VERSION "canboat-NMEA2000-curated"

NS_ :

BS_:

BU_: Vector__XXX
BO_ 2382300672 PGN_130822_navicoConfigurationSet: 17 Vector__XXX
 SG_ Manufacturer_Code : 0|11@1+ (1.0,0) [0|2047] "" Vector__XXX
 SG_ Industry_Code : 13|3@1+ (1.0,0) [0|7] "" Vector__XXX
 SG_ Marker : 16|8@1+ (1.0,0) [0|255] "" Vector__XXX
 SG_ Command : 24|6@1+ (1.0,0) [0|63] "" Vector__XXX
 SG_ Spare : 30|2@1+ (1.0,0) [0|3] "" Vector__XXX
 SG_ Address : 32|8@1+ (1.0,0) [0|255] "" Vector__XXX
 SG_ Section : 40|8@1+ (1.0,0) [0|255] "" Vector__XXX
 SG_ Item : 48|8@1+ (1.0,0) [0|255] "" Vector__XXX
 SG_ Spare_1 : 56|8@1+ (1.0,0) [0|255] "" Vector__XXX
 SG_ Source_Setting_Id : 64|8@1+ (1.0,0) [0|255] "" Vector__XXX
 SG_ Spare_2 : 72|24@1+ (1.0,0) [0|16777215] "" Vector__XXX
 SG_ Token : 96|16@1+ (1.0,0) [0|65535] "" Vector__XXX
 SG_ Length : 112|16@1+ (1.0,0) [0|65535] "" Vector__XXX
 SG_ Value : 128|8@1+ (1.0,0) [0|255] "" Vector__XXX

BO_ 2382300672 PGN_130822_navicoUdbDatabaseBulkReport2: 223 Vector__XXX
 SG_ Manufacturer_Code : 0|11@1+ (1.0,0) [0|2047] "" Vector__XXX
 SG_ Industry_Code : 13|3@1+ (1.0,0) [0|7] "" Vector__XXX
 SG_ Marker : 16|8@1+ (1.0,0) [0|255] "" Vector__XXX
 SG_ Command : 24|6@1+ (1.0,0) [0|63] "" Vector__XXX
 SG_ Spare : 30|2@1+ (1.0,0) [0|3] "" Vector__XXX
 SG_ Address : 32|8@1+ (1.0,0) [0|255] "" Vector__XXX
 SG_ Section : 40|8@1+ (1.0,0) [0|255] "" Vector__XXX
 SG_ Item : 48|8@1+ (1.0,0) [0|255] "" Vector__XXX
 SG_ Data : 56|1728@1+ (1.0,0) [0|15129776317850095820092511389349266990292718729815631986418537353879463563521162185150219603700165130994236082131324756445942491538167955612355559370819630786874949073054392871127532858565042604704229027792897149278536911570984376289178239414281093587086254280625511423417734560103547720775941236898584297864754056409689723511538383397266829071642966529789271374337767970717302376007449935423628987375161285038699647338790955261847896303406764539379637294632424461577413789356619528237622525126579905139518845267220627455] "" Vector__XXX

BO_ 2382300672 PGN_130822_navicoUdbDatabaseBulkReport4: 223 Vector__XXX
 SG_ Manufacturer_Code : 0|11@1+ (1.0,0) [0|2047] "" Vector__XXX
 SG_ Industry_Code : 13|3@1+ (1.0,0) [0|7] "" Vector__XXX
 SG_ Marker : 16|8@1+ (1.0,0) [0|255] "" Vector__XXX
 SG_ Command : 24|6@1+ (1.0,0) [0|63] "" Vector__XXX
 SG_ Address : 32|8@1+ (1.0,0) [0|255] "" Vector__XXX
 SG_ Section : 40|8@1+ (1.0,0) [0|255] "" Vector__XXX
 SG_ Item : 48|8@1+ (1.0,0) [0|255] "" Vector__XXX
 SG_ Data : 56|1728@1+ (1.0,0) [0|15129776317850095820092511389349266990292718729815631986418537353879463563521162185150219603700165130994236082131324756445942491538167955612355559370819630786874949073054392871127532858565042604704229027792897149278536911570984376289178239414281093587086254280625511423417734560103547720775941236898584297864754056409689723511538383397266829071642966529789271374337767970717302376007449935423628987375161285038699647338790955261847896303406764539379637294632424461577413789356619528237622525126579905139518845267220627455] "" Vector__XXX

BO_ 2382300672 PGN_130822_navicoUdbDatabaseObjectDump: 15 Vector__XXX
 SG_ Manufacturer_Code : 0|11@1+ (1.0,0) [0|2047] "" Vector__XXX
 SG_ Industry_Code : 13|3@1+ (1.0,0) [0|7] "" Vector__XXX
 SG_ Marker : 16|8@1+ (1.0,0) [0|255] "" Vector__XXX
 SG_ Command : 24|6@1+ (1.0,0) [0|63] "" Vector__XXX
 SG_ Address : 32|8@1+ (1.0,0) [0|255] "" Vector__XXX
 SG_ Section : 40|8@1+ (1.0,0) [0|255] "" Vector__XXX
 SG_ Item : 48|8@1+ (1.0,0) [0|255] "" Vector__XXX
 SG_ Object_Value : 56|16@1+ (1.0,0) [0|65535] "" Vector__XXX
 SG_ Sub : 72|24@1+ (1.0,0) [0|16777215] "" Vector__XXX
 SG_ Token : 96|16@1+ (1.0,0) [0|65535] "" Vector__XXX
 SG_ field112 : 112|8@1+ (1.0,0) [0|255] "" Vector__XXX

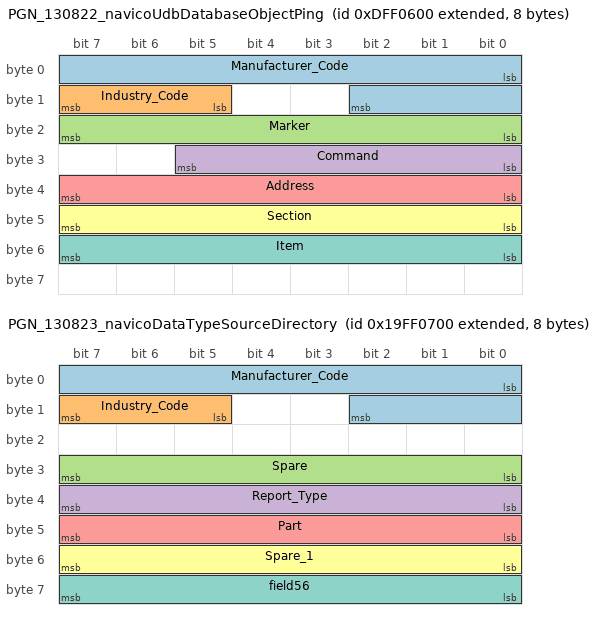
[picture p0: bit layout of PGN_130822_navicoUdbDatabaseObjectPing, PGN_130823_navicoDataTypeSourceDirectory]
BO_ 2382300672 PGN_130822_navicoUdbDatabaseObjectPing: 8 Vector__XXX
 SG_ Manufacturer_Code : 0|11@1+ (1.0,0) [0|2047] "" Vector__XXX
 SG_ Industry_Code : 13|3@1+ (1.0,0) [0|7] "" Vector__XXX
 SG_ Marker : 16|8@1+ (1.0,0) [0|255] "" Vector__XXX
 SG_ Command : 24|6@1+ (1.0,0) [0|63] "" Vector__XXX
 SG_ Address : 32|8@1+ (1.0,0) [0|255] "" Vector__XXX
 SG_ Section : 40|8@1+ (1.0,0) [0|255] "" Vector__XXX
 SG_ Item : 48|8@1+ (1.0,0) [0|255] "" Vector__XXX

BO_ 2382300672 PGN_130822_navicoUdbDatabaseShortReport5: 11 Vector__XXX
 SG_ Manufacturer_Code : 0|11@1+ (1.0,0) [0|2047] "" Vector__XXX
 SG_ Industry_Code : 13|3@1+ (1.0,0) [0|7] "" Vector__XXX
 SG_ Marker : 16|8@1+ (1.0,0) [0|255] "" Vector__XXX
 SG_ Command : 24|6@1+ (1.0,0) [0|63] "" Vector__XXX
 SG_ Address : 32|8@1+ (1.0,0) [0|255] "" Vector__XXX
 SG_ Section : 40|8@1+ (1.0,0) [0|255] "" Vector__XXX
 SG_ Item : 48|8@1+ (1.0,0) [0|255] "" Vector__XXX
 SG_ Data : 56|32@1+ (1.0,0) [0|4294967295] "" Vector__XXX

BO_ 2382300672 PGN_130822_navicoUdbDatabaseShortReport7: 11 Vector__XXX
 SG_ Manufacturer_Code : 0|11@1+ (1.0,0) [0|2047] "" Vector__XXX
 SG_ Industry_Code : 13|3@1+ (1.0,0) [0|7] "" Vector__XXX
 SG_ Marker : 16|8@1+ (1.0,0) [0|255] "" Vector__XXX
 SG_ Command : 24|6@1+ (1.0,0) [0|63] "" Vector__XXX
 SG_ Address : 32|8@1+ (1.0,0) [0|255] "" Vector__XXX
 SG_ Section : 40|8@1+ (1.0,0) [0|255] "" Vector__XXX
 SG_ Item : 48|8@1+ (1.0,0) [0|255] "" Vector__XXX
 SG_ Data : 56|32@1+ (1.0,0) [0|4294967295] "" Vector__XXX

BO_ 2382300672 PGN_130822_navicoUdbDatabaseSourceReport: 15 Vector__XXX
 SG_ Manufacturer_Code : 0|11@1+ (1.0,0) [0|2047] "" Vector__XXX
 SG_ Industry_Code : 13|3@1+ (1.0,0) [0|7] "" Vector__XXX
 SG_ Marker : 16|8@1+ (1.0,0) [0|255] "" Vector__XXX
 SG_ Command : 24|6@1+ (1.0,0) [0|63] "" Vector__XXX
 SG_ Spare : 30|2@1+ (1.0,0) [0|3] "" Vector__XXX
 SG_ Address : 32|8@1+ (1.0,0) [0|255] "" Vector__XXX
 SG_ Source_Setting_Id : 40|8@1+ (1.0,0) [0|255] "" Vector__XXX
 SG_ Item : 48|8@1+ (1.0,0) [0|255] "" Vector__XXX
 SG_ Object_Value : 56|16@1+ (1.0,0) [0|65535] "" Vector__XXX
 SG_ Instance : 72|4@1+ (1.0,0) [0|15] "" Vector__XXX
 SG_ Source_Selection_Master : 76|1@1+ (1.0,0) [0|1] "" Vector__XXX
 SG_ Spare_1 : 77|3@1+ (1.0,0) [0|7] "" Vector__XXX
 SG_ Sub : 80|24@1+ (1.0,0) [0|16777215] "" Vector__XXX
 SG_ Token : 104|16@1+ (1.0,0) [0|65535] "" Vector__XXX

BO_ 2382300928 PGN_130823_maretronProprietaryTemperatureHighRange: 9 Vector__XXX
 SG_ Manufacturer_Code : 0|11@1+ (1.0,0) [0|2047] "" Vector__XXX
 SG_ Industry_Code : 13|3@1+ (1.0,0) [0|7] "" Vector__XXX
 SG_ SID : 16|8@1+ (1.0,0) [0|255] "" Vector__XXX
 SG_ Instance : 24|8@1+ (1.0,0) [0|255] "" Vector__XXX
 SG_ Source : 32|8@1+ (1.0,0) [0|255] "" Vector__XXX
 SG_ Actual_Temperature : 40|16@1+ (0.1,0) [0.0|6553.5] "" Vector__XXX
 SG_ Set_Temperature : 56|16@1+ (0.1,0) [0.0|6553.5] "" Vector__XXX

BO_ 2583627520 PGN_130823_navicoBoatSpeedPolarTable: 230 Vector__XXX
 SG_ Manufacturer_Code : 0|11@1+ (1.0,0) [0|2047] "" Vector__XXX
 SG_ Industry_Code : 13|3@1+ (1.0,0) [0|7] "" Vector__XXX
 SG_ Spare : 24|8@1+ (1.0,0) [0|255] "" Vector__XXX
 SG_ Report_Type : 32|8@1+ (1.0,0) [0|255] "" Vector__XXX
 SG_ Part : 40|8@1+ (1.0,0) [0|255] "" Vector__XXX
 SG_ Spare_1 : 48|8@1+ (1.0,0) [0|255] "" Vector__XXX
 SG_ Data : 56|1784@1+ (1.0,0) [0|1090215279796298345343057319992441691038624747443985361781209060500115864369550760897269927218265076257224706224150656474098235960303036328065314058501678867531182833105052489870268422279120576700031813116210596361941430020414688522690787050244934600671795757515093047026287646566366777283893649942831776083163858446641848270013788759459916945946844663111358071639842481472666169361795887031940572252862030682746818684507336852618633070135215708762463263460541984102045620907003420426453486084172633338261276848631947315738747720031010815] "" Vector__XXX

BO_ 2583627520 PGN_130823_navicoDataTypeSourceDirectory: 8 Vector__XXX
 SG_ Manufacturer_Code : 0|11@1+ (1.0,0) [0|2047] "" Vector__XXX
 SG_ Industry_Code : 13|3@1+ (1.0,0) [0|7] "" Vector__XXX
 SG_ Spare : 24|8@1+ (1.0,0) [0|255] "" Vector__XXX
 SG_ Report_Type : 32|8@1+ (1.0,0) [0|255] "" Vector__XXX
 SG_ Part : 40|8@1+ (1.0,0) [0|255] "" Vector__XXX
 SG_ Spare_1 : 48|8@1+ (1.0,0) [0|255] "" Vector__XXX
 SG_ field56 : 56|8@1+ (1.0,0) [0|255] "" Vector__XXX

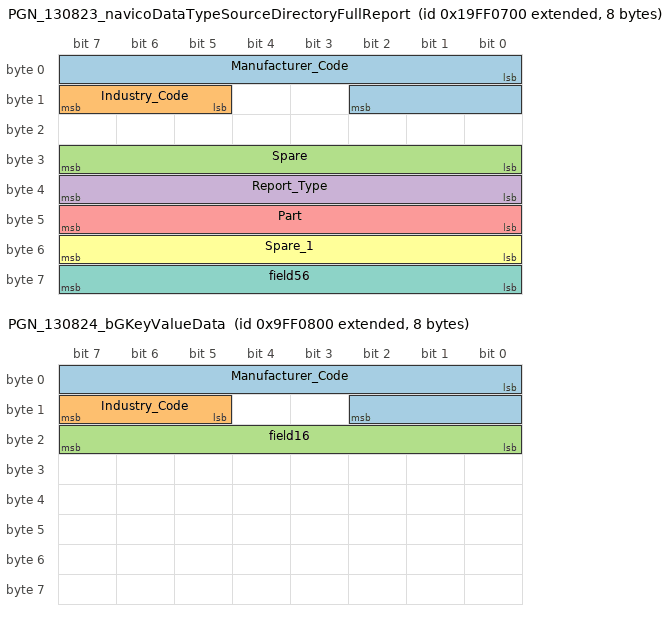
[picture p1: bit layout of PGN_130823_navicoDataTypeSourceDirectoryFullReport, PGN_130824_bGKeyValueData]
BO_ 2583627520 PGN_130823_navicoDataTypeSourceDirectoryFullReport: 8 Vector__XXX
 SG_ Manufacturer_Code : 0|11@1+ (1.0,0) [0|2047] "" Vector__XXX
 SG_ Industry_Code : 13|3@1+ (1.0,0) [0|7] "" Vector__XXX
 SG_ Spare : 24|8@1+ (1.0,0) [0|255] "" Vector__XXX
 SG_ Report_Type : 32|8@1+ (1.0,0) [0|255] "" Vector__XXX
 SG_ Part : 40|8@1+ (1.0,0) [0|255] "" Vector__XXX
 SG_ Spare_1 : 48|8@1+ (1.0,0) [0|255] "" Vector__XXX
 SG_ field56 : 56|8@1+ (1.0,0) [0|255] "" Vector__XXX

BO_ 2315192320 PGN_130824_bGKeyValueData: 8 Vector__XXX
 SG_ Manufacturer_Code : 0|11@1+ (1.0,0) [0|2047] "" Vector__XXX
 SG_ Industry_Code : 13|3@1+ (1.0,0) [0|7] "" Vector__XXX
 SG_ field16 : 16|8@1+ (1.0,0) [0|255] "" Vector__XXX

BO_ 2650736640 PGN_130824_maretronAnnunciator: 9 Vector__XXX
 SG_ Manufacturer_Code : 0|11@1+ (1.0,0) [0|2047] "" Vector__XXX
 SG_ Industry_Code : 13|3@1+ (1.0,0) [0|7] "" Vector__XXX
 SG_ Annunciator_Instance : 16|8@1+ (1.0,0) [0|255] "" Vector__XXX
 SG_ Annunciator_State : 24|8@1+ (1.0,0) [0|255] "" Vector__XXX
 SG_ Pattern : 32|16@1+ (1.0,0) [0|65535] "" Vector__XXX
 SG_ Field_7 : 48|8@1+ (1.0,0) [0|255] "" Vector__XXX
 SG_ Alert_ID : 56|16@1+ (1.0,0) [0|65535] "" Vector__XXX

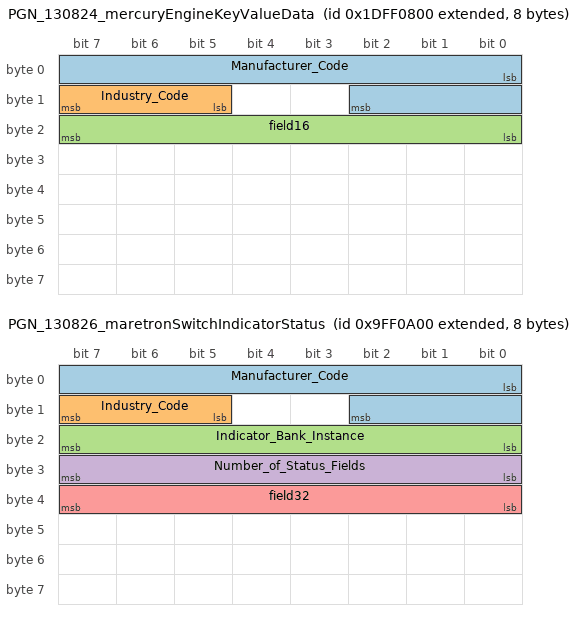
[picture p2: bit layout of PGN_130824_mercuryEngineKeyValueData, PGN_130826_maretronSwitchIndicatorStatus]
BO_ 2650736640 PGN_130824_mercuryEngineKeyValueData: 8 Vector__XXX
 SG_ Manufacturer_Code : 0|11@1+ (1.0,0) [0|2047] "" Vector__XXX
 SG_ Industry_Code : 13|3@1+ (1.0,0) [0|7] "" Vector__XXX
 SG_ field16 : 16|8@1+ (1.0,0) [0|255] "" Vector__XXX

BO_ 2583628032 PGN_130825_bepMarineProprietaryPgn130825: 223 Vector__XXX
 SG_ Manufacturer_Code : 0|11@1+ (1.0,0) [0|2047] "" Vector__XXX
 SG_ Industry_Code : 13|3@1+ (1.0,0) [0|7] "" Vector__XXX
 SG_ Data : 16|1768@1+ (1.0,0) [0|16635364987126134419907490844611231857889171561340108669757218330385068731224834608417815051548234195819468783937845710359164977421616154908223175941492902641772198991471137845920843845811776377869137773379678289214194183661112800944378464511794046030758602257005203964634516091405743061582849883160885255175229773660916874237270946647032424101972117051870087763059119895517977437771543686400460392041962138103436564399831189767740372774280024852942859855049773927338342604171805121253257539126169331943684033945189625789470637817855] "" Vector__XXX

BO_ 2583628032 PGN_130825_maretronDataInstanceChannelCorrelation: 9 Vector__XXX
 SG_ Manufacturer_Code : 0|11@1+ (1.0,0) [0|2047] "" Vector__XXX
 SG_ Industry_Code : 13|3@1+ (1.0,0) [0|7] "" Vector__XXX
 SG_ PGN : 16|24@1+ (1.0,0) [0.0|262143.0] "" Vector__XXX
 SG_ Hardware_Channel : 40|8@1+ (1.0,0) [0|255] "" Vector__XXX
 SG_ Instance : 48|8@1+ (1.0,0) [0|255] "" Vector__XXX
 SG_ Data_Source : 56|8@1+ (1.0,0) [0|255] "" Vector__XXX
 SG_ Data_Indicator : 64|8@1+ (1.0,0) [0|255] "" Vector__XXX

BO_ 2650736896 PGN_130825_mercuryCommandResponse: 33 Vector__XXX
 SG_ Manufacturer_Code : 0|11@1+ (1.0,0) [0|2047] "" Vector__XXX
 SG_ Industry_Code : 13|3@1+ (1.0,0) [0|7] "" Vector__XXX
 SG_ Opcode : 16|8@1+ (1.0,0) [0|255] "" Vector__XXX
 SG_ Data : 24|240@1+ (1.0,0) [0|1766847064778384329583297500742918515827483896875618958121606201292619775] "" Vector__XXX

BO_ 2650736896 PGN_130825_mercuryCruiseControlData: 13 Vector__XXX
 SG_ Manufacturer_Code : 0|11@1+ (1.0,0) [0|2047] "" Vector__XXX
 SG_ Industry_Code : 13|3@1+ (1.0,0) [0|7] "" Vector__XXX
 SG_ Opcode : 16|8@1+ (1.0,0) [0|255] "" Vector__XXX
 SG_ Engine_Instance : 24|8@1+ (1.0,0) [0|255] "" Vector__XXX
 SG_ Cruise_State : 40|8@1+ (1.0,0) [0|255] "" Vector__XXX
 SG_ Cruise_RPM_Setpoint : 48|16@1+ (1.0,0) [0|65535] "rpm" Vector__XXX
 SG_ Cruise_Speed_Setpoint : 64|16@1+ (0.01,0) [0.0|655.35] "km/h" Vector__XXX

BO_ 2650736896 PGN_130825_navicoAlarm: 11 Vector__XXX
 SG_ Manufacturer_Code : 0|11@1+ (1.0,0) [0|2047] "" Vector__XXX
 SG_ Industry_Code : 13|3@1+ (1.0,0) [0|7] "" Vector__XXX
 SG_ Instance : 16|8@1+ (1.0,0) [0|255] "" Vector__XXX
 SG_ Record_ID : 24|8@1+ (1.0,0) [0|255] "" Vector__XXX
 SG_ Alarm_Type : 32|16@1+ (1.0,0) [0|65535] "" Vector__XXX
 SG_ Alarm_ID : 48|16@1+ (1.0,0) [0|65535] "" Vector__XXX
 SG_ Alarm_State : 64|3@1+ (1.0,0) [0|7] "" Vector__XXX
 SG_ Action_Flag : 67|1@1+ (1.0,0) [0|1] "" Vector__XXX
 SG_ Alarm_Severity : 68|4@1+ (1.0,0) [0|15] "" Vector__XXX
 SG_ Value : 72|16@1+ (1.0,0) [0|65535] "" Vector__XXX

BO_ 2583628288 PGN_130826_bepMarineProprietaryPgn130826: 223 Vector__XXX
 SG_ Manufacturer_Code : 0|11@1+ (1.0,0) [0|2047] "" Vector__XXX
 SG_ Industry_Code : 13|3@1+ (1.0,0) [0|7] "" Vector__XXX
 SG_ Data : 16|1768@1+ (1.0,0) [0|16635364987126134419907490844611231857889171561340108669757218330385068731224834608417815051548234195819468783937845710359164977421616154908223175941492902641772198991471137845920843845811776377869137773379678289214194183661112800944378464511794046030758602257005203964634516091405743061582849883160885255175229773660916874237270946647032424101972117051870087763059119895517977437771543686400460392041962138103436564399831189767740372774280024852942859855049773927338342604171805121253257539126169331943684033945189625789470637817855] "" Vector__XXX

BO_ 2315192832 PGN_130826_maretronSwitchIndicatorStatus: 8 Vector__XXX
 SG_ Manufacturer_Code : 0|11@1+ (1.0,0) [0|2047] "" Vector__XXX
 SG_ Industry_Code : 13|3@1+ (1.0,0) [0|7] "" Vector__XXX
 SG_ Indicator_Bank_Instance : 16|8@1+ (1.0,0) [0|255] "" Vector__XXX
 SG_ Number_of_Status_Fields : 24|8@1+ (1.0,0) [0|255] "" Vector__XXX
 SG_ field32 : 32|8@1+ (1.0,0) [0|255] "" Vector__XXX

BO_ 2650737152 PGN_130826_mercuryBamDigitalDataProxy: 38 Vector__XXX
 SG_ Manufacturer_Code : 0|11@1+ (1.0,0) [0|2047] "" Vector__XXX
 SG_ Industry_Code : 13|3@1+ (1.0,0) [0|7] "" Vector__XXX
 SG_ Type : 16|8@1+ (1.0,0) [0|255] "" Vector__XXX
 SG_ Instance : 24|8@1+ (1.0,0) [0|255] "" Vector__XXX
 SG_ Field_4 : 32|2@1+ (1.0,0) [0|3] "" Vector__XXX
 SG_ Flag : 40|8@1+ (1.0,0) [0|255] "" Vector__XXX
 SG_ Data : 48|256@1+ (1.0,0) [0|115792089237316195423570985008687907853269984665640564039457584007913129639935] "" Vector__XXX

CM_ BO_ 2382300672 "NMEA2000: PGN 130822 - Navico: Configuration Set (type: Fast)";
CM_ BO_ 2382300672 "NMEA2000: PGN 130822 - Navico: UDB Database, Bulk Report 2 (type: Fast)";
CM_ BO_ 2382300672 "NMEA2000: PGN 130822 - Navico: UDB Database, Bulk Report 4 (type: Fast)";
CM_ BO_ 2382300672 "NMEA2000: PGN 130822 - Navico: UDB Database, Object Dump (type: Fast)";
CM_ BO_ 2382300672 "NMEA2000: PGN 130822 - Navico: UDB Database, Object Ping (type: Fast)";
CM_ BO_ 2382300672 "NMEA2000: PGN 130822 - Navico: UDB Database, Short Report 5 (type: Fast)";
CM_ BO_ 2382300672 "NMEA2000: PGN 130822 - Navico: UDB Database, Short Report 7 (type: Fast)";
CM_ BO_ 2382300672 "NMEA2000: PGN 130822 - Navico: UDB Database, Source Report (type: Fast)";
CM_ BO_ 2382300928 "NMEA2000: PGN 130823 - Maretron: Proprietary Temperature High Range (type: Fast)";
CM_ BO_ 2583627520 "NMEA2000: PGN 130823 - Navico: Boat Speed Polar Table (type: Fast)";
CM_ BO_ 2583627520 "NMEA2000: PGN 130823 - Navico: Data Type Source Directory (type: Fast)";
CM_ BO_ 2583627520 "NMEA2000: PGN 130823 - Navico: Data Type Source Directory, Full Report (type: Fast)";
CM_ BO_ 2315192320 "NMEA2000: PGN 130824 - B&G: key-value data (type: Fast)";
CM_ BO_ 2650736640 "NMEA2000: PGN 130824 - Maretron: Annunciator (type: Fast)";
CM_ BO_ 2650736640 "NMEA2000: PGN 130824 - Mercury: Engine Key-Value Data (type: Fast)";
CM_ BO_ 2583628032 "NMEA2000: PGN 130825 - BEP Marine: Proprietary PGN 130825 (type: Fast)";
CM_ BO_ 2583628032 "NMEA2000: PGN 130825 - Maretron: Data Instance Channel Correlation (type: Fast)";
CM_ BO_ 2650736896 "NMEA2000: PGN 130825 - Mercury: Command/Response (type: Fast)";
CM_ BO_ 2650736896 "NMEA2000: PGN 130825 - Mercury: Cruise Control Data (type: Fast)";
CM_ BO_ 2650736896 "NMEA2000: PGN 130825 - Navico: Alarm (type: Fast)";
CM_ BO_ 2583628288 "NMEA2000: PGN 130826 - BEP Marine: Proprietary PGN 130826 (type: Fast)";
CM_ BO_ 2315192832 "NMEA2000: PGN 130826 - Maretron: Switch Indicator Status (type: Fast)";
CM_ BO_ 2650737152 "NMEA2000: PGN 130826 - Mercury: BAM Digital-Data Proxy (type: Fast)";
CM_ SG_ 2382300672 Manufacturer_Code "Navico; canboat type: LOOKUP";
CM_ SG_ 2382300672 Industry_Code "Marine Industry; canboat type: LOOKUP";
CM_ SG_ 2382300672 Marker "Always 0xFF; canboat type: UINT8";
CM_ SG_ 2382300672 Command "Configuration Set; canboat type: UNSIGNED_INTEGER";
CM_ SG_ 2382300672 Spare "canboat type: SPARE";
CM_ SG_ 2382300672 Address "Part of the object address; canboat type: UINT8";
CM_ SG_ 2382300672 Section "canboat type: UINT8";
CM_ SG_ 2382300672 Item "canboat type: UINT8";
CM_ SG_ 2382300672 Spare_1 "canboat type: SPARE";
CM_ SG_ 2382300672 Source_Setting_Id "Compacted id selecting which setting this object reports; also resolves the wire type of the Value field that follows. Different id space from the Command 1 'Source Setting Id', the Command 6 dump / PGN 130845 NAVICO_DATA_TYPE ids, and PGN 130840.; canboat type: DYNAMIC_FIELD_KEY";
CM_ SG_ 2382300672 Spare_2 "canboat type: SPARE";
CM_ SG_ 2382300672 Token "Per-object identity token, constant per object; canboat type: UINT16";
CM_ SG_ 2382300672 Length "Byte length of the Value field that follows; canboat type: DYNAMIC_FIELD_LENGTH";
CM_ SG_ 2382300672 Value "Value for this setting; its type is resolved from Source Setting Id.; canboat type: DYNAMIC_FIELD_VALUE";
CM_ SG_ 2382300672 Manufacturer_Code "Navico; canboat type: LOOKUP";
CM_ SG_ 2382300672 Industry_Code "Marine Industry; canboat type: LOOKUP";
CM_ SG_ 2382300672 Marker "Always 0xFF; canboat type: UINT8";
CM_ SG_ 2382300672 Command "Bulk Report 2; canboat type: UNSIGNED_INTEGER";
CM_ SG_ 2382300672 Spare "canboat type: SPARE";
CM_ SG_ 2382300672 Address "Part of the object address; canboat type: UINT8";
CM_ SG_ 2382300672 Section "canboat type: UINT8";
CM_ SG_ 2382300672 Item "canboat type: UINT8";
CM_ SG_ 2382300672 Data "Bulk variant payload (length-prefixed); layout not yet observed on the wire; canboat type: BINARY";
CM_ SG_ 2382300672 Manufacturer_Code "Navico; canboat type: LOOKUP";
CM_ SG_ 2382300672 Industry_Code "Marine Industry; canboat type: LOOKUP";
CM_ SG_ 2382300672 Marker "Always 0xFF; canboat type: UINT8";
CM_ SG_ 2382300672 Command "Bulk Report 4; canboat type: UNSIGNED_INTEGER";
CM_ SG_ 2382300672 Address "Part of the object address; canboat type: UINT8";
CM_ SG_ 2382300672 Section "canboat type: UINT8";
CM_ SG_ 2382300672 Item "canboat type: UINT8";
CM_ SG_ 2382300672 Data "Bulk variant payload (length-prefixed); layout not yet observed on the wire; canboat type: BINARY";
CM_ SG_ 2382300672 Manufacturer_Code "Navico; canboat type: LOOKUP";
CM_ SG_ 2382300672 Industry_Code "Marine Industry; canboat type: LOOKUP";
CM_ SG_ 2382300672 Marker "Always 0xFF; canboat type: UINT8";
CM_ SG_ 2382300672 Command "Object Dump; canboat type: UNSIGNED_INTEGER";
CM_ SG_ 2382300672 Address "Part of the object address; canboat type: UINT8";
CM_ SG_ 2382300672 Section "canboat type: UINT8";
CM_ SG_ 2382300672 Item "canboat type: UINT8";
CM_ SG_ 2382300672 Object_Value "Current value (A); 0xFC00 means no value; canboat type: UINT16";
CM_ SG_ 2382300672 Sub "Sub-index and auxiliary bytes; canboat type: BINARY";
CM_ SG_ 2382300672 Token "Per-object identity/CRC-like token (B), constant per object; canboat type: UINT16";
CM_ SG_ 2382300672 field112 "canboat type: NUMBER";
CM_ SG_ 2382300672 Manufacturer_Code "Navico; canboat type: LOOKUP";
CM_ SG_ 2382300672 Industry_Code "Marine Industry; canboat type: LOOKUP";
CM_ SG_ 2382300672 Marker "Always 0xFF; canboat type: UINT8";
CM_ SG_ 2382300672 Command "Object Ping; canboat type: UNSIGNED_INTEGER";
CM_ SG_ 2382300672 Address "Part of the object address; canboat type: UINT8";
CM_ SG_ 2382300672 Section "canboat type: UINT8";
CM_ SG_ 2382300672 Item "canboat type: UINT8";
CM_ SG_ 2382300672 Manufacturer_Code "Navico; canboat type: LOOKUP";
CM_ SG_ 2382300672 Industry_Code "Marine Industry; canboat type: LOOKUP";
CM_ SG_ 2382300672 Marker "Always 0xFF; canboat type: UINT8";
CM_ SG_ 2382300672 Command "Short Report 5; canboat type: UNSIGNED_INTEGER";
CM_ SG_ 2382300672 Address "Part of the object address; canboat type: UINT8";
CM_ SG_ 2382300672 Section "canboat type: UINT8";
CM_ SG_ 2382300672 Item "canboat type: UINT8";
CM_ SG_ 2382300672 Data "canboat type: BINARY";
CM_ SG_ 2382300672 Manufacturer_Code "Navico; canboat type: LOOKUP";
CM_ SG_ 2382300672 Industry_Code "Marine Industry; canboat type: LOOKUP";
CM_ SG_ 2382300672 Marker "Always 0xFF; canboat type: UINT8";
CM_ SG_ 2382300672 Command "Short Report 7; canboat type: UNSIGNED_INTEGER";
CM_ SG_ 2382300672 Address "Part of the object address; canboat type: UINT8";
CM_ SG_ 2382300672 Section "canboat type: UINT8";
CM_ SG_ 2382300672 Item "canboat type: UINT8";
CM_ SG_ 2382300672 Data "canboat type: BINARY";
CM_ SG_ 2382300672 Manufacturer_Code "Navico; canboat type: LOOKUP";
CM_ SG_ 2382300672 Industry_Code "Marine Industry; canboat type: LOOKUP";
CM_ SG_ 2382300672 Marker "Always 0xFF; canboat type: UINT8";
CM_ SG_ 2382300672 Command "Source Report; canboat type: UNSIGNED_INTEGER";
CM_ SG_ 2382300672 Spare "canboat type: SPARE";
CM_ SG_ 2382300672 Address "Part of the object address; canboat type: UINT8";
CM_ SG_ 2382300672 Source_Setting_Id "Compacted id selecting which data type this object is for. This is a different id space from the Command 6 dump / PGN 130845 data-type ids (NAVICO_DATA_TYPE) - the two use different numbers for the same quantity. Only 0x0F = Heading is mapped so far; see PGN 130840.; canboat type: UINT8";
CM_ SG_ 2382300672 Item "canboat type: UINT8";
CM_ SG_ 2382300672 Object_Value "Current value (A); 0xFC00 means no value. This is the field that varies over time.; canboat type: UINT16";
CM_ SG_ 2382300672 Instance "canboat type: UNSIGNED_INTEGER";
CM_ SG_ 2382300672 Source_Selection_Master "Auto-select / source-selection-master flag; canboat type: UNSIGNED_INTEGER";
CM_ SG_ 2382300672 Spare_1 "canboat type: SPARE";
CM_ SG_ 2382300672 Sub "Sub-index and auxiliary bytes; constant per object (same Sub as the Command 6 dump); canboat type: BINARY";
CM_ SG_ 2382300672 Token "Per-object identity/CRC-like token (B), constant per object (same Token as the Command 6 dump); canboat type: UINT16";
CM_ SG_ 2382300928 Manufacturer_Code "Maretron; canboat type: LOOKUP";
CM_ SG_ 2382300928 Industry_Code "Marine Industry; canboat type: LOOKUP";
CM_ SG_ 2382300928 SID "canboat type: UINT8";
CM_ SG_ 2382300928 Instance "canboat type: UINT8";
CM_ SG_ 2382300928 Source "canboat type: LOOKUP";
CM_ SG_ 2382300928 Actual_Temperature "canboat type: TEMPERATURE_HIGH";
CM_ SG_ 2382300928 Set_Temperature "canboat type: TEMPERATURE_HIGH";
CM_ SG_ 2583627520 Manufacturer_Code "Navico; canboat type: LOOKUP";
CM_ SG_ 2583627520 Industry_Code "Marine Industry; canboat type: LOOKUP";
CM_ SG_ 2583627520 Spare "canboat type: SPARE";
CM_ SG_ 2583627520 Report_Type "Boat-speed polar / performance table; canboat type: UINT8";
CM_ SG_ 2583627520 Part "Part number; the table is split across several parts that must be concatenated in order; canboat type: UINT8";
CM_ SG_ 2583627520 Spare_1 "canboat type: SPARE";
CM_ SG_ 2583627520 Data "Raw table fragment carried by this part; canboat type: BINARY";
CM_ SG_ 2583627520 Manufacturer_Code "Navico; canboat type: LOOKUP";
CM_ SG_ 2583627520 Industry_Code "Marine Industry; canboat type: LOOKUP";
CM_ SG_ 2583627520 Spare "canboat type: SPARE";
CM_ SG_ 2583627520 Report_Type "Data-type source directory; canboat type: UINT8";
CM_ SG_ 2583627520 Part "Sequence/part number of the directory report; canboat type: UINT8";
CM_ SG_ 2583627520 Spare_1 "canboat type: SPARE";
CM_ SG_ 2583627520 field56 "canboat type: NUMBER";
CM_ SG_ 2583627520 Manufacturer_Code "Navico; canboat type: LOOKUP";
CM_ SG_ 2583627520 Industry_Code "Marine Industry; canboat type: LOOKUP";
CM_ SG_ 2583627520 Spare "canboat type: SPARE";
CM_ SG_ 2583627520 Report_Type "Data-type source directory (full report); canboat type: UINT8";
CM_ SG_ 2583627520 Part "Sequence/part number of the directory report; canboat type: UINT8";
CM_ SG_ 2583627520 Spare_1 "canboat type: SPARE";
CM_ SG_ 2583627520 field56 "canboat type: NUMBER";
CM_ SG_ 2315192320 Manufacturer_Code "B & G; canboat type: LOOKUP";
CM_ SG_ 2315192320 Industry_Code "Marine Industry; canboat type: LOOKUP";
CM_ SG_ 2315192320 field16 "canboat type: NUMBER";
CM_ SG_ 2650736640 Manufacturer_Code "Maretron; canboat type: LOOKUP";
CM_ SG_ 2650736640 Industry_Code "Marine Industry; canboat type: LOOKUP";
CM_ SG_ 2650736640 Annunciator_Instance "canboat type: UINT8";
CM_ SG_ 2650736640 Annunciator_State "100 while the annunciator is sounding, 0 while it is idle.; canboat type: UINT8";
CM_ SG_ 2650736640 Pattern "Selects the pulse pattern; observed values 0 to 4 give audibly different beep cadences, not different pitches. Unavailable while idle.; canboat type: UINT16";
CM_ SG_ 2650736640 Field_7 "canboat type: UINT8";
CM_ SG_ 2650736640 Alert_ID "Identifies the alert the annunciator is currently sounding for.; canboat type: UINT16";
CM_ SG_ 2650736640 Manufacturer_Code "Mercury Marine; canboat type: LOOKUP";
CM_ SG_ 2650736640 Industry_Code "Marine Industry; canboat type: LOOKUP";
CM_ SG_ 2650736640 field16 "canboat type: NUMBER";
CM_ SG_ 2583628032 Manufacturer_Code "BEP Marine; canboat type: LOOKUP";
CM_ SG_ 2583628032 Industry_Code "Marine Industry; canboat type: LOOKUP";
CM_ SG_ 2583628032 Data "canboat type: BINARY";
CM_ SG_ 2583628032 Manufacturer_Code "Maretron; canboat type: LOOKUP";
CM_ SG_ 2583628032 Industry_Code "Marine Industry; canboat type: LOOKUP";
CM_ SG_ 2583628032 PGN "PGN for which the correlation is reported; canboat type: PGN";
CM_ SG_ 2583628032 Hardware_Channel "canboat type: UINT8";
CM_ SG_ 2583628032 Instance "canboat type: UINT8";
CM_ SG_ 2583628032 Data_Source "canboat type: UINT8";
CM_ SG_ 2583628032 Data_Indicator "canboat type: UINT8";
CM_ SG_ 2650736896 Manufacturer_Code "Mercury Marine; canboat type: LOOKUP";
CM_ SG_ 2650736896 Industry_Code "Marine Industry; canboat type: LOOKUP";
CM_ SG_ 2650736896 Opcode "canboat type: LOOKUP";
CM_ SG_ 2650736896 Data "canboat type: BINARY";
CM_ SG_ 2650736896 Manufacturer_Code "Mercury Marine; canboat type: LOOKUP";
CM_ SG_ 2650736896 Industry_Code "Marine Industry; canboat type: LOOKUP";
CM_ SG_ 2650736896 Opcode "Cruise Control; canboat type: LOOKUP";
CM_ SG_ 2650736896 Engine_Instance "canboat type: UINT8";
CM_ SG_ 2650736896 Cruise_State "Cruise engagement/mode byte; 0 = disengaged, 5 = engaged; canboat type: UINT8";
CM_ SG_ 2650736896 Cruise_RPM_Setpoint "canboat type: UINT16";
CM_ SG_ 2650736896 Cruise_Speed_Setpoint "canboat type: DILUTION_OF_PRECISION_UFIX16";
CM_ SG_ 2650736896 Manufacturer_Code "Navico; canboat type: LOOKUP";
CM_ SG_ 2650736896 Industry_Code "Marine Industry; canboat type: LOOKUP";
CM_ SG_ 2650736896 Instance "canboat type: UINT8";
CM_ SG_ 2650736896 Record_ID "canboat type: UINT8";
CM_ SG_ 2650736896 Alarm_Type "canboat type: UINT16";
CM_ SG_ 2650736896 Alarm_ID "canboat type: LOOKUP";
CM_ SG_ 2650736896 Alarm_State "canboat type: LOOKUP";
CM_ SG_ 2650736896 Action_Flag "canboat type: UNSIGNED_INTEGER";
CM_ SG_ 2650736896 Alarm_Severity "canboat type: LOOKUP";
CM_ SG_ 2650736896 Value "canboat type: UINT16";
CM_ SG_ 2583628288 Manufacturer_Code "BEP Marine; canboat type: LOOKUP";
CM_ SG_ 2583628288 Industry_Code "Marine Industry; canboat type: LOOKUP";
CM_ SG_ 2583628288 Data "canboat type: BINARY";
CM_ SG_ 2315192832 Manufacturer_Code "Maretron; canboat type: LOOKUP";
CM_ SG_ 2315192832 Industry_Code "Marine Industry; canboat type: LOOKUP";
CM_ SG_ 2315192832 Indicator_Bank_Instance "canboat type: UINT8";
CM_ SG_ 2315192832 Number_of_Status_Fields "canboat type: UINT8";
CM_ SG_ 2315192832 field32 "canboat type: NUMBER";
CM_ SG_ 2650737152 Manufacturer_Code "Mercury Marine; canboat type: LOOKUP";
CM_ SG_ 2650737152 Industry_Code "Marine Industry; canboat type: LOOKUP";
CM_ SG_ 2650737152 Type "canboat type: UINT8";
CM_ SG_ 2650737152 Instance "canboat type: UINT8";
CM_ SG_ 2650737152 Field_4 "canboat type: UNSIGNED_INTEGER";
CM_ SG_ 2650737152 Flag "canboat type: UINT8";
CM_ SG_ 2650737152 Data "canboat type: BINARY";
VAL_ 2382300672 Manufacturer_Code 69 "ARKS Enterprises" 78 "FW Murphy/Enovation Controls" 80 "Twin Disc" 85 "Kohler Power Systems" 88 "Hemisphere GPS" 135 "Airmar" 137 "Maretron" 140 "Lowrance" 144 "Mercury Marine" 147 "Nautibus Electronic" 148 "Blue Water Data" 154 "Westerbeke" 157 "ISSPRO" 161 "Offshore Systems (UK)" 163 "Evinrude/BRP" 165 "CPAC Systems" 168 "Xantrex Technology" 169 "Marlin Technologies" 172 "Yanmar Marine" 174 "Volvo Penta" 176 "Carling Technologies Inc. (Moritz Aerospace)" 185 "Beede Instruments" 192 "Floscan Instrument" 193 "Nobeltec" 198 "Mystic Valley Communications" 199 "Actia" 201 "Disenos Y Technologia" 211 "Digital Switching Systems" 215 "Xintex/Atena" 224 "EMMI NETWORK" 228 "ZF" 229 "Garmin" 233 "Yacht Monitoring Solutions" 235 "Sailormade Marine Telemetry/Tetra Technology" 243 "Eride" 257 "Honda Motor" 272 "Groco" 273 "Actisense" 274 "Amphenol LTW Technology" 275 "Navico" 283 "Hamilton Jet" 285 "Sea Recovery" 286 "Coelmo SRL Italy" 295 "BEP Marine" 304 "Empir Bus" 305 "NovAtel" 306 "Sleipner Motor" 307 "MBW Technologies" 315 "ICOM" 328 "Qwerty" 329 "Dief" 341 "Boening Automationstechnologie" 345 "Korean Maritime University" 351 "Thrane and Thrane" 355 "Mastervolt" 356 "Fischer Panda Generators" 358 "Victron Energy" 370 "Rolls Royce Marine" 373 "Electronic Design" 374 "Northern Lights" 378 "Glendinning" 381 "B & G" 384 "Rose Point Navigation Systems" 385 "Johnson Outdoors Marine Electronics Inc Geonav" 394 "Capi 2" 396 "Beyond Measure" 400 "Livorsi Marine" 404 "ComNav" 409 "Chetco" 419 "Fusion Electronics" 421 "Standard Horizon" 422 "True Heading" 426 "Egersund Marine Electronics" 427 "em-trak Marine Electronics" 431 "Tohatsu Co, JP" 437 "Digital Yacht" 438 "Comar Systems Limited" 440 "Cummins" 443 "VDO (aka Continental-Corporation)" 451 "Parker Hannifin aka Village Marine Tech" 459 "Alltek Marine Electronics" 460 "SAN GIORGIO S.E.I.N" 466 "Veethree Electronics & Marine" 470 "SI-TEX Marine Electronics" 471 "Sea Cross Marine" 475 "GME aka Standard Communications" 476 "Humminbird Marine Electronics" 478 "Ocean Sat" 481 "Chetco Digital Instruments" 493 "Watcheye" 499 "Lcj Capteurs" 502 "Attwood Marine" 503 "Naviop S.R.L." 504 "Vesper Marine" 510 "Marinesoft" 513 "Simarine" 517 "NoLand Engineering" 518 "Transas USA" 529 "National Instruments Korea" 530 "National Marine Electronics Association" 532 "Onwa Marine" 540 "Webasto" 571 "Marinecraft (South Korea)" 573 "McMurdo Group aka Orolia" 578 "Advansea" 579 "KVH" 580 "San Jose Technology" 583 "Yacht Control" 586 "Suzuki Motor" 591 "US Coast Guard" 595 "Ship Module aka Customware" 600 "Aquatic AV" 605 "Aventics" 606 "Intellian" 612 "SamwonIT" 614 "Arlt Tecnologies" 637 "Bavaria Yachts" 641 "Diverse Yacht Services" 644 "Wema U.S.A dba KUS" 658 "Shenzhen Jiuzhou Himunication" 688 "Rockford" 699 "Harman International" 704 "JL Audio" 708 "Lars Thrane" 715 "Autonnic" 717 "Yacht Devices" 734 "REAP Systems" 735 "AEM Performance Electronics" 739 "LxNav" 741 "Littelfuse, Inc (formerly Carling Technologies)" 743 "DaeMyung" 744 "Woosung" 748 "ISOTTA IFRA srl" 773 "Clarion US" 776 "HMI Systems" 777 "Ocean Signal" 778 "Seakeeper" 781 "Poly Planar" 785 "Fischer Panda DE" 795 "Broyda Industries" 796 "Canadian Automotive" 797 "Tides Marine" 798 "Lumishore" 799 "Still Water Designs and Audio" 802 "BJ Technologies (Beneteau)" 803 "Gill Sensors" 811 "Blue Water Desalination" 815 "FLIR" 824 "Undheim Systems" 826 "Lewmar" 838 "TeamSurv" 844 "Fell Marine" 847 "Oceanvolt" 862 "Prospec" 868 "Data Panel" 890 "L3 Technologies" 894 "Rhodan Marine Systems" 896 "Nexfour Solutions" 905 "ASA Electronics" 909 "Marines Co (South Korea)" 911 "Nautic-on" 917 "Sentinel" 929 "JL Marine Systems" 930 "Ecotronix" 944 "Zontisa Marine" 951 "EXOR International" 962 "Timbolier Industries" 963 "TJC Micro" 968 "Cox Powertrain" 969 "Blue Seas" 981 "Kobelt Manufacturing" 992 "Blue Ocean IOT" 997 "Xenta Systems" 999 "Signal K" 1004 "Ultraflex" 1008 "Lintest SmartBoat" 1011 "Soundmax" 1020 "Team Italia Marine (Onyx Marine Automation s.r.l)" 1021 "Entratech" 1022 "ITC" 1029 "The Marine Guardian" 1047 "Sonic" 1051 "ProNav" 1053 "Vetus Maxwell INC." 1056 "Lithium Pros" 1059 "Boatrax" 1062 "Marol Co ltd" 1065 "CALYPSO Instruments" 1066 "Spot Zero Water" 1069 "Lithionics Battery" 1070 "Quick-teck Electronics" 1075 "Uniden America" 1083 "Nauticoncept" 1084 "Shadow-Caster LED lighting" 1085 "Wet Sounds" 1088 "E-T-A Circuit Breakers" 1092 "Scheiber" 1100 "Smart Yachts International Limited" 1109 "Dockmate" 1114 "Bobs Machine" 1118 "L3Harris ASV" 1119 "Balmar" 1120 "Elettromedia" 1127 "Electromaax" 1140 "Across Oceans Systems" 1145 "Kiwi Yachting" 1150 "BSB Artificial Intelligence" 1151 "Orca Technologies" 1154 "TBS Electronics" 1158 "Technoton Electroics" 1160 "MG Energy Systems" 1169 "Sea Machine Robotics" 1171 "Vista Manufacturing" 1183 "Zipwake" 1186 "Sailmon" 1192 "Airmoniq Pro Kft" 1194 "Sierra Marine" 1200 "Xinuo Information Technology (Xiamen)" 1218 "Septentrio" 1233 "NKE Marine Electronics" 1238 "SuperTrack Aps" 1239 "Honda Electronics" 1245 "Raritan Engineering" 1249 "Integrated Power Solutions AG" 1260 "Interactive Technologies" 1283 "LTG-Tech" 1299 "Energy Solutions (UK)" 1300 "WATT Fuel Cell" 1302 "Pro Mainer" 1305 "Dragonfly Energy" 1306 "Koden Electronics" 1311 "Humphree" 1316 "Hinkley Yachts" 1317 "Global Marine Management GmbH (GMM)" 1320 "Triskel Marine" 1330 "Warwick Control Technologies" 1331 "Dolphin Charger" 1337 "Barnacle Systems" 1348 "Radian IoT" 1353 "Ocean LED Marine" 1359 "BluNav" 1361 "OVA (Nantong Saiyang Electronics Co., Ltd)" 1368 "RAD Propulsion" 1369 "Electric Yacht" 1372 "Elco Motor Yachts" 1384 "Tecnoseal Foundry S.r.l" 1385 "Pro Charging Systems" 1389 "EVEX" 1398 "Gobius Sensor Technology" 1403 "Arco Marine" 1408 "Lenco Marine" 1413 "Naocontrol" 1417 "Revatek" 1438 "Aeolionics" 1439 "PredictWind" 1440 "Egis Mobile Electric" 1445 "Starboard Yacht Group" 1446 "Roswell Marine" 1451 "ePropulsion (Guangdong ePropulsion Technology Ltd.)" 1452 "Micro-Air" 1453 "Vital Battery" 1458 "Ride Controller" 1460 "Tocaro Blue" 1461 "Vanquish Yachts" 1471 "FT Technologies" 1478 "Alps Alpine" 1481 "E-Force Marine" 1482 "CMC Marine" 1483 "Nanjing Sandemarine Information Technology" 1850 "Teleflex Marine (SeaStar Solutions)" 1851 "Raymarine" 1852 "Navionics" 1853 "Japan Radio" 1854 "Northstar Technologies" 1855 "Furuno" 1856 "Trimble" 1857 "Simrad" 1858 "Litton" 1859 "Kvasar" 1860 "MMP" 1861 "Vector Cantech" 1862 "Yamaha Marine" 1863 "Faria Instruments" ;
VAL_ 2382300672 Industry_Code 0 "Global" 1 "Highway" 2 "Agriculture" 3 "Construction" 4 "Marine Industry" 5 "Industrial" ;
VAL_ 2382300672 Manufacturer_Code 69 "ARKS Enterprises" 78 "FW Murphy/Enovation Controls" 80 "Twin Disc" 85 "Kohler Power Systems" 88 "Hemisphere GPS" 135 "Airmar" 137 "Maretron" 140 "Lowrance" 144 "Mercury Marine" 147 "Nautibus Electronic" 148 "Blue Water Data" 154 "Westerbeke" 157 "ISSPRO" 161 "Offshore Systems (UK)" 163 "Evinrude/BRP" 165 "CPAC Systems" 168 "Xantrex Technology" 169 "Marlin Technologies" 172 "Yanmar Marine" 174 "Volvo Penta" 176 "Carling Technologies Inc. (Moritz Aerospace)" 185 "Beede Instruments" 192 "Floscan Instrument" 193 "Nobeltec" 198 "Mystic Valley Communications" 199 "Actia" 201 "Disenos Y Technologia" 211 "Digital Switching Systems" 215 "Xintex/Atena" 224 "EMMI NETWORK" 228 "ZF" 229 "Garmin" 233 "Yacht Monitoring Solutions" 235 "Sailormade Marine Telemetry/Tetra Technology" 243 "Eride" 257 "Honda Motor" 272 "Groco" 273 "Actisense" 274 "Amphenol LTW Technology" 275 "Navico" 283 "Hamilton Jet" 285 "Sea Recovery" 286 "Coelmo SRL Italy" 295 "BEP Marine" 304 "Empir Bus" 305 "NovAtel" 306 "Sleipner Motor" 307 "MBW Technologies" 315 "ICOM" 328 "Qwerty" 329 "Dief" 341 "Boening Automationstechnologie" 345 "Korean Maritime University" 351 "Thrane and Thrane" 355 "Mastervolt" 356 "Fischer Panda Generators" 358 "Victron Energy" 370 "Rolls Royce Marine" 373 "Electronic Design" 374 "Northern Lights" 378 "Glendinning" 381 "B & G" 384 "Rose Point Navigation Systems" 385 "Johnson Outdoors Marine Electronics Inc Geonav" 394 "Capi 2" 396 "Beyond Measure" 400 "Livorsi Marine" 404 "ComNav" 409 "Chetco" 419 "Fusion Electronics" 421 "Standard Horizon" 422 "True Heading" 426 "Egersund Marine Electronics" 427 "em-trak Marine Electronics" 431 "Tohatsu Co, JP" 437 "Digital Yacht" 438 "Comar Systems Limited" 440 "Cummins" 443 "VDO (aka Continental-Corporation)" 451 "Parker Hannifin aka Village Marine Tech" 459 "Alltek Marine Electronics" 460 "SAN GIORGIO S.E.I.N" 466 "Veethree Electronics & Marine" 470 "SI-TEX Marine Electronics" 471 "Sea Cross Marine" 475 "GME aka Standard Communications" 476 "Humminbird Marine Electronics" 478 "Ocean Sat" 481 "Chetco Digital Instruments" 493 "Watcheye" 499 "Lcj Capteurs" 502 "Attwood Marine" 503 "Naviop S.R.L." 504 "Vesper Marine" 510 "Marinesoft" 513 "Simarine" 517 "NoLand Engineering" 518 "Transas USA" 529 "National Instruments Korea" 530 "National Marine Electronics Association" 532 "Onwa Marine" 540 "Webasto" 571 "Marinecraft (South Korea)" 573 "McMurdo Group aka Orolia" 578 "Advansea" 579 "KVH" 580 "San Jose Technology" 583 "Yacht Control" 586 "Suzuki Motor" 591 "US Coast Guard" 595 "Ship Module aka Customware" 600 "Aquatic AV" 605 "Aventics" 606 "Intellian" 612 "SamwonIT" 614 "Arlt Tecnologies" 637 "Bavaria Yachts" 641 "Diverse Yacht Services" 644 "Wema U.S.A dba KUS" 658 "Shenzhen Jiuzhou Himunication" 688 "Rockford" 699 "Harman International" 704 "JL Audio" 708 "Lars Thrane" 715 "Autonnic" 717 "Yacht Devices" 734 "REAP Systems" 735 "AEM Performance Electronics" 739 "LxNav" 741 "Littelfuse, Inc (formerly Carling Technologies)" 743 "DaeMyung" 744 "Woosung" 748 "ISOTTA IFRA srl" 773 "Clarion US" 776 "HMI Systems" 777 "Ocean Signal" 778 "Seakeeper" 781 "Poly Planar" 785 "Fischer Panda DE" 795 "Broyda Industries" 796 "Canadian Automotive" 797 "Tides Marine" 798 "Lumishore" 799 "Still Water Designs and Audio" 802 "BJ Technologies (Beneteau)" 803 "Gill Sensors" 811 "Blue Water Desalination" 815 "FLIR" 824 "Undheim Systems" 826 "Lewmar" 838 "TeamSurv" 844 "Fell Marine" 847 "Oceanvolt" 862 "Prospec" 868 "Data Panel" 890 "L3 Technologies" 894 "Rhodan Marine Systems" 896 "Nexfour Solutions" 905 "ASA Electronics" 909 "Marines Co (South Korea)" 911 "Nautic-on" 917 "Sentinel" 929 "JL Marine Systems" 930 "Ecotronix" 944 "Zontisa Marine" 951 "EXOR International" 962 "Timbolier Industries" 963 "TJC Micro" 968 "Cox Powertrain" 969 "Blue Seas" 981 "Kobelt Manufacturing" 992 "Blue Ocean IOT" 997 "Xenta Systems" 999 "Signal K" 1004 "Ultraflex" 1008 "Lintest SmartBoat" 1011 "Soundmax" 1020 "Team Italia Marine (Onyx Marine Automation s.r.l)" 1021 "Entratech" 1022 "ITC" 1029 "The Marine Guardian" 1047 "Sonic" 1051 "ProNav" 1053 "Vetus Maxwell INC." 1056 "Lithium Pros" 1059 "Boatrax" 1062 "Marol Co ltd" 1065 "CALYPSO Instruments" 1066 "Spot Zero Water" 1069 "Lithionics Battery" 1070 "Quick-teck Electronics" 1075 "Uniden America" 1083 "Nauticoncept" 1084 "Shadow-Caster LED lighting" 1085 "Wet Sounds" 1088 "E-T-A Circuit Breakers" 1092 "Scheiber" 1100 "Smart Yachts International Limited" 1109 "Dockmate" 1114 "Bobs Machine" 1118 "L3Harris ASV" 1119 "Balmar" 1120 "Elettromedia" 1127 "Electromaax" 1140 "Across Oceans Systems" 1145 "Kiwi Yachting" 1150 "BSB Artificial Intelligence" 1151 "Orca Technologies" 1154 "TBS Electronics" 1158 "Technoton Electroics" 1160 "MG Energy Systems" 1169 "Sea Machine Robotics" 1171 "Vista Manufacturing" 1183 "Zipwake" 1186 "Sailmon" 1192 "Airmoniq Pro Kft" 1194 "Sierra Marine" 1200 "Xinuo Information Technology (Xiamen)" 1218 "Septentrio" 1233 "NKE Marine Electronics" 1238 "SuperTrack Aps" 1239 "Honda Electronics" 1245 "Raritan Engineering" 1249 "Integrated Power Solutions AG" 1260 "Interactive Technologies" 1283 "LTG-Tech" 1299 "Energy Solutions (UK)" 1300 "WATT Fuel Cell" 1302 "Pro Mainer" 1305 "Dragonfly Energy" 1306 "Koden Electronics" 1311 "Humphree" 1316 "Hinkley Yachts" 1317 "Global Marine Management GmbH (GMM)" 1320 "Triskel Marine" 1330 "Warwick Control Technologies" 1331 "Dolphin Charger" 1337 "Barnacle Systems" 1348 "Radian IoT" 1353 "Ocean LED Marine" 1359 "BluNav" 1361 "OVA (Nantong Saiyang Electronics Co., Ltd)" 1368 "RAD Propulsion" 1369 "Electric Yacht" 1372 "Elco Motor Yachts" 1384 "Tecnoseal Foundry S.r.l" 1385 "Pro Charging Systems" 1389 "EVEX" 1398 "Gobius Sensor Technology" 1403 "Arco Marine" 1408 "Lenco Marine" 1413 "Naocontrol" 1417 "Revatek" 1438 "Aeolionics" 1439 "PredictWind" 1440 "Egis Mobile Electric" 1445 "Starboard Yacht Group" 1446 "Roswell Marine" 1451 "ePropulsion (Guangdong ePropulsion Technology Ltd.)" 1452 "Micro-Air" 1453 "Vital Battery" 1458 "Ride Controller" 1460 "Tocaro Blue" 1461 "Vanquish Yachts" 1471 "FT Technologies" 1478 "Alps Alpine" 1481 "E-Force Marine" 1482 "CMC Marine" 1483 "Nanjing Sandemarine Information Technology" 1850 "Teleflex Marine (SeaStar Solutions)" 1851 "Raymarine" 1852 "Navionics" 1853 "Japan Radio" 1854 "Northstar Technologies" 1855 "Furuno" 1856 "Trimble" 1857 "Simrad" 1858 "Litton" 1859 "Kvasar" 1860 "MMP" 1861 "Vector Cantech" 1862 "Yamaha Marine" 1863 "Faria Instruments" ;
VAL_ 2382300672 Industry_Code 0 "Global" 1 "Highway" 2 "Agriculture" 3 "Construction" 4 "Marine Industry" 5 "Industrial" ;
VAL_ 2382300672 Manufacturer_Code 69 "ARKS Enterprises" 78 "FW Murphy/Enovation Controls" 80 "Twin Disc" 85 "Kohler Power Systems" 88 "Hemisphere GPS" 135 "Airmar" 137 "Maretron" 140 "Lowrance" 144 "Mercury Marine" 147 "Nautibus Electronic" 148 "Blue Water Data" 154 "Westerbeke" 157 "ISSPRO" 161 "Offshore Systems (UK)" 163 "Evinrude/BRP" 165 "CPAC Systems" 168 "Xantrex Technology" 169 "Marlin Technologies" 172 "Yanmar Marine" 174 "Volvo Penta" 176 "Carling Technologies Inc. (Moritz Aerospace)" 185 "Beede Instruments" 192 "Floscan Instrument" 193 "Nobeltec" 198 "Mystic Valley Communications" 199 "Actia" 201 "Disenos Y Technologia" 211 "Digital Switching Systems" 215 "Xintex/Atena" 224 "EMMI NETWORK" 228 "ZF" 229 "Garmin" 233 "Yacht Monitoring Solutions" 235 "Sailormade Marine Telemetry/Tetra Technology" 243 "Eride" 257 "Honda Motor" 272 "Groco" 273 "Actisense" 274 "Amphenol LTW Technology" 275 "Navico" 283 "Hamilton Jet" 285 "Sea Recovery" 286 "Coelmo SRL Italy" 295 "BEP Marine" 304 "Empir Bus" 305 "NovAtel" 306 "Sleipner Motor" 307 "MBW Technologies" 315 "ICOM" 328 "Qwerty" 329 "Dief" 341 "Boening Automationstechnologie" 345 "Korean Maritime University" 351 "Thrane and Thrane" 355 "Mastervolt" 356 "Fischer Panda Generators" 358 "Victron Energy" 370 "Rolls Royce Marine" 373 "Electronic Design" 374 "Northern Lights" 378 "Glendinning" 381 "B & G" 384 "Rose Point Navigation Systems" 385 "Johnson Outdoors Marine Electronics Inc Geonav" 394 "Capi 2" 396 "Beyond Measure" 400 "Livorsi Marine" 404 "ComNav" 409 "Chetco" 419 "Fusion Electronics" 421 "Standard Horizon" 422 "True Heading" 426 "Egersund Marine Electronics" 427 "em-trak Marine Electronics" 431 "Tohatsu Co, JP" 437 "Digital Yacht" 438 "Comar Systems Limited" 440 "Cummins" 443 "VDO (aka Continental-Corporation)" 451 "Parker Hannifin aka Village Marine Tech" 459 "Alltek Marine Electronics" 460 "SAN GIORGIO S.E.I.N" 466 "Veethree Electronics & Marine" 470 "SI-TEX Marine Electronics" 471 "Sea Cross Marine" 475 "GME aka Standard Communications" 476 "Humminbird Marine Electronics" 478 "Ocean Sat" 481 "Chetco Digital Instruments" 493 "Watcheye" 499 "Lcj Capteurs" 502 "Attwood Marine" 503 "Naviop S.R.L." 504 "Vesper Marine" 510 "Marinesoft" 513 "Simarine" 517 "NoLand Engineering" 518 "Transas USA" 529 "National Instruments Korea" 530 "National Marine Electronics Association" 532 "Onwa Marine" 540 "Webasto" 571 "Marinecraft (South Korea)" 573 "McMurdo Group aka Orolia" 578 "Advansea" 579 "KVH" 580 "San Jose Technology" 583 "Yacht Control" 586 "Suzuki Motor" 591 "US Coast Guard" 595 "Ship Module aka Customware" 600 "Aquatic AV" 605 "Aventics" 606 "Intellian" 612 "SamwonIT" 614 "Arlt Tecnologies" 637 "Bavaria Yachts" 641 "Diverse Yacht Services" 644 "Wema U.S.A dba KUS" 658 "Shenzhen Jiuzhou Himunication" 688 "Rockford" 699 "Harman International" 704 "JL Audio" 708 "Lars Thrane" 715 "Autonnic" 717 "Yacht Devices" 734 "REAP Systems" 735 "AEM Performance Electronics" 739 "LxNav" 741 "Littelfuse, Inc (formerly Carling Technologies)" 743 "DaeMyung" 744 "Woosung" 748 "ISOTTA IFRA srl" 773 "Clarion US" 776 "HMI Systems" 777 "Ocean Signal" 778 "Seakeeper" 781 "Poly Planar" 785 "Fischer Panda DE" 795 "Broyda Industries" 796 "Canadian Automotive" 797 "Tides Marine" 798 "Lumishore" 799 "Still Water Designs and Audio" 802 "BJ Technologies (Beneteau)" 803 "Gill Sensors" 811 "Blue Water Desalination" 815 "FLIR" 824 "Undheim Systems" 826 "Lewmar" 838 "TeamSurv" 844 "Fell Marine" 847 "Oceanvolt" 862 "Prospec" 868 "Data Panel" 890 "L3 Technologies" 894 "Rhodan Marine Systems" 896 "Nexfour Solutions" 905 "ASA Electronics" 909 "Marines Co (South Korea)" 911 "Nautic-on" 917 "Sentinel" 929 "JL Marine Systems" 930 "Ecotronix" 944 "Zontisa Marine" 951 "EXOR International" 962 "Timbolier Industries" 963 "TJC Micro" 968 "Cox Powertrain" 969 "Blue Seas" 981 "Kobelt Manufacturing" 992 "Blue Ocean IOT" 997 "Xenta Systems" 999 "Signal K" 1004 "Ultraflex" 1008 "Lintest SmartBoat" 1011 "Soundmax" 1020 "Team Italia Marine (Onyx Marine Automation s.r.l)" 1021 "Entratech" 1022 "ITC" 1029 "The Marine Guardian" 1047 "Sonic" 1051 "ProNav" 1053 "Vetus Maxwell INC." 1056 "Lithium Pros" 1059 "Boatrax" 1062 "Marol Co ltd" 1065 "CALYPSO Instruments" 1066 "Spot Zero Water" 1069 "Lithionics Battery" 1070 "Quick-teck Electronics" 1075 "Uniden America" 1083 "Nauticoncept" 1084 "Shadow-Caster LED lighting" 1085 "Wet Sounds" 1088 "E-T-A Circuit Breakers" 1092 "Scheiber" 1100 "Smart Yachts International Limited" 1109 "Dockmate" 1114 "Bobs Machine" 1118 "L3Harris ASV" 1119 "Balmar" 1120 "Elettromedia" 1127 "Electromaax" 1140 "Across Oceans Systems" 1145 "Kiwi Yachting" 1150 "BSB Artificial Intelligence" 1151 "Orca Technologies" 1154 "TBS Electronics" 1158 "Technoton Electroics" 1160 "MG Energy Systems" 1169 "Sea Machine Robotics" 1171 "Vista Manufacturing" 1183 "Zipwake" 1186 "Sailmon" 1192 "Airmoniq Pro Kft" 1194 "Sierra Marine" 1200 "Xinuo Information Technology (Xiamen)" 1218 "Septentrio" 1233 "NKE Marine Electronics" 1238 "SuperTrack Aps" 1239 "Honda Electronics" 1245 "Raritan Engineering" 1249 "Integrated Power Solutions AG" 1260 "Interactive Technologies" 1283 "LTG-Tech" 1299 "Energy Solutions (UK)" 1300 "WATT Fuel Cell" 1302 "Pro Mainer" 1305 "Dragonfly Energy" 1306 "Koden Electronics" 1311 "Humphree" 1316 "Hinkley Yachts" 1317 "Global Marine Management GmbH (GMM)" 1320 "Triskel Marine" 1330 "Warwick Control Technologies" 1331 "Dolphin Charger" 1337 "Barnacle Systems" 1348 "Radian IoT" 1353 "Ocean LED Marine" 1359 "BluNav" 1361 "OVA (Nantong Saiyang Electronics Co., Ltd)" 1368 "RAD Propulsion" 1369 "Electric Yacht" 1372 "Elco Motor Yachts" 1384 "Tecnoseal Foundry S.r.l" 1385 "Pro Charging Systems" 1389 "EVEX" 1398 "Gobius Sensor Technology" 1403 "Arco Marine" 1408 "Lenco Marine" 1413 "Naocontrol" 1417 "Revatek" 1438 "Aeolionics" 1439 "PredictWind" 1440 "Egis Mobile Electric" 1445 "Starboard Yacht Group" 1446 "Roswell Marine" 1451 "ePropulsion (Guangdong ePropulsion Technology Ltd.)" 1452 "Micro-Air" 1453 "Vital Battery" 1458 "Ride Controller" 1460 "Tocaro Blue" 1461 "Vanquish Yachts" 1471 "FT Technologies" 1478 "Alps Alpine" 1481 "E-Force Marine" 1482 "CMC Marine" 1483 "Nanjing Sandemarine Information Technology" 1850 "Teleflex Marine (SeaStar Solutions)" 1851 "Raymarine" 1852 "Navionics" 1853 "Japan Radio" 1854 "Northstar Technologies" 1855 "Furuno" 1856 "Trimble" 1857 "Simrad" 1858 "Litton" 1859 "Kvasar" 1860 "MMP" 1861 "Vector Cantech" 1862 "Yamaha Marine" 1863 "Faria Instruments" ;
VAL_ 2382300672 Industry_Code 0 "Global" 1 "Highway" 2 "Agriculture" 3 "Construction" 4 "Marine Industry" 5 "Industrial" ;
VAL_ 2382300672 Manufacturer_Code 69 "ARKS Enterprises" 78 "FW Murphy/Enovation Controls" 80 "Twin Disc" 85 "Kohler Power Systems" 88 "Hemisphere GPS" 135 "Airmar" 137 "Maretron" 140 "Lowrance" 144 "Mercury Marine" 147 "Nautibus Electronic" 148 "Blue Water Data" 154 "Westerbeke" 157 "ISSPRO" 161 "Offshore Systems (UK)" 163 "Evinrude/BRP" 165 "CPAC Systems" 168 "Xantrex Technology" 169 "Marlin Technologies" 172 "Yanmar Marine" 174 "Volvo Penta" 176 "Carling Technologies Inc. (Moritz Aerospace)" 185 "Beede Instruments" 192 "Floscan Instrument" 193 "Nobeltec" 198 "Mystic Valley Communications" 199 "Actia" 201 "Disenos Y Technologia" 211 "Digital Switching Systems" 215 "Xintex/Atena" 224 "EMMI NETWORK" 228 "ZF" 229 "Garmin" 233 "Yacht Monitoring Solutions" 235 "Sailormade Marine Telemetry/Tetra Technology" 243 "Eride" 257 "Honda Motor" 272 "Groco" 273 "Actisense" 274 "Amphenol LTW Technology" 275 "Navico" 283 "Hamilton Jet" 285 "Sea Recovery" 286 "Coelmo SRL Italy" 295 "BEP Marine" 304 "Empir Bus" 305 "NovAtel" 306 "Sleipner Motor" 307 "MBW Technologies" 315 "ICOM" 328 "Qwerty" 329 "Dief" 341 "Boening Automationstechnologie" 345 "Korean Maritime University" 351 "Thrane and Thrane" 355 "Mastervolt" 356 "Fischer Panda Generators" 358 "Victron Energy" 370 "Rolls Royce Marine" 373 "Electronic Design" 374 "Northern Lights" 378 "Glendinning" 381 "B & G" 384 "Rose Point Navigation Systems" 385 "Johnson Outdoors Marine Electronics Inc Geonav" 394 "Capi 2" 396 "Beyond Measure" 400 "Livorsi Marine" 404 "ComNav" 409 "Chetco" 419 "Fusion Electronics" 421 "Standard Horizon" 422 "True Heading" 426 "Egersund Marine Electronics" 427 "em-trak Marine Electronics" 431 "Tohatsu Co, JP" 437 "Digital Yacht" 438 "Comar Systems Limited" 440 "Cummins" 443 "VDO (aka Continental-Corporation)" 451 "Parker Hannifin aka Village Marine Tech" 459 "Alltek Marine Electronics" 460 "SAN GIORGIO S.E.I.N" 466 "Veethree Electronics & Marine" 470 "SI-TEX Marine Electronics" 471 "Sea Cross Marine" 475 "GME aka Standard Communications" 476 "Humminbird Marine Electronics" 478 "Ocean Sat" 481 "Chetco Digital Instruments" 493 "Watcheye" 499 "Lcj Capteurs" 502 "Attwood Marine" 503 "Naviop S.R.L." 504 "Vesper Marine" 510 "Marinesoft" 513 "Simarine" 517 "NoLand Engineering" 518 "Transas USA" 529 "National Instruments Korea" 530 "National Marine Electronics Association" 532 "Onwa Marine" 540 "Webasto" 571 "Marinecraft (South Korea)" 573 "McMurdo Group aka Orolia" 578 "Advansea" 579 "KVH" 580 "San Jose Technology" 583 "Yacht Control" 586 "Suzuki Motor" 591 "US Coast Guard" 595 "Ship Module aka Customware" 600 "Aquatic AV" 605 "Aventics" 606 "Intellian" 612 "SamwonIT" 614 "Arlt Tecnologies" 637 "Bavaria Yachts" 641 "Diverse Yacht Services" 644 "Wema U.S.A dba KUS" 658 "Shenzhen Jiuzhou Himunication" 688 "Rockford" 699 "Harman International" 704 "JL Audio" 708 "Lars Thrane" 715 "Autonnic" 717 "Yacht Devices" 734 "REAP Systems" 735 "AEM Performance Electronics" 739 "LxNav" 741 "Littelfuse, Inc (formerly Carling Technologies)" 743 "DaeMyung" 744 "Woosung" 748 "ISOTTA IFRA srl" 773 "Clarion US" 776 "HMI Systems" 777 "Ocean Signal" 778 "Seakeeper" 781 "Poly Planar" 785 "Fischer Panda DE" 795 "Broyda Industries" 796 "Canadian Automotive" 797 "Tides Marine" 798 "Lumishore" 799 "Still Water Designs and Audio" 802 "BJ Technologies (Beneteau)" 803 "Gill Sensors" 811 "Blue Water Desalination" 815 "FLIR" 824 "Undheim Systems" 826 "Lewmar" 838 "TeamSurv" 844 "Fell Marine" 847 "Oceanvolt" 862 "Prospec" 868 "Data Panel" 890 "L3 Technologies" 894 "Rhodan Marine Systems" 896 "Nexfour Solutions" 905 "ASA Electronics" 909 "Marines Co (South Korea)" 911 "Nautic-on" 917 "Sentinel" 929 "JL Marine Systems" 930 "Ecotronix" 944 "Zontisa Marine" 951 "EXOR International" 962 "Timbolier Industries" 963 "TJC Micro" 968 "Cox Powertrain" 969 "Blue Seas" 981 "Kobelt Manufacturing" 992 "Blue Ocean IOT" 997 "Xenta Systems" 999 "Signal K" 1004 "Ultraflex" 1008 "Lintest SmartBoat" 1011 "Soundmax" 1020 "Team Italia Marine (Onyx Marine Automation s.r.l)" 1021 "Entratech" 1022 "ITC" 1029 "The Marine Guardian" 1047 "Sonic" 1051 "ProNav" 1053 "Vetus Maxwell INC." 1056 "Lithium Pros" 1059 "Boatrax" 1062 "Marol Co ltd" 1065 "CALYPSO Instruments" 1066 "Spot Zero Water" 1069 "Lithionics Battery" 1070 "Quick-teck Electronics" 1075 "Uniden America" 1083 "Nauticoncept" 1084 "Shadow-Caster LED lighting" 1085 "Wet Sounds" 1088 "E-T-A Circuit Breakers" 1092 "Scheiber" 1100 "Smart Yachts International Limited" 1109 "Dockmate" 1114 "Bobs Machine" 1118 "L3Harris ASV" 1119 "Balmar" 1120 "Elettromedia" 1127 "Electromaax" 1140 "Across Oceans Systems" 1145 "Kiwi Yachting" 1150 "BSB Artificial Intelligence" 1151 "Orca Technologies" 1154 "TBS Electronics" 1158 "Technoton Electroics" 1160 "MG Energy Systems" 1169 "Sea Machine Robotics" 1171 "Vista Manufacturing" 1183 "Zipwake" 1186 "Sailmon" 1192 "Airmoniq Pro Kft" 1194 "Sierra Marine" 1200 "Xinuo Information Technology (Xiamen)" 1218 "Septentrio" 1233 "NKE Marine Electronics" 1238 "SuperTrack Aps" 1239 "Honda Electronics" 1245 "Raritan Engineering" 1249 "Integrated Power Solutions AG" 1260 "Interactive Technologies" 1283 "LTG-Tech" 1299 "Energy Solutions (UK)" 1300 "WATT Fuel Cell" 1302 "Pro Mainer" 1305 "Dragonfly Energy" 1306 "Koden Electronics" 1311 "Humphree" 1316 "Hinkley Yachts" 1317 "Global Marine Management GmbH (GMM)" 1320 "Triskel Marine" 1330 "Warwick Control Technologies" 1331 "Dolphin Charger" 1337 "Barnacle Systems" 1348 "Radian IoT" 1353 "Ocean LED Marine" 1359 "BluNav" 1361 "OVA (Nantong Saiyang Electronics Co., Ltd)" 1368 "RAD Propulsion" 1369 "Electric Yacht" 1372 "Elco Motor Yachts" 1384 "Tecnoseal Foundry S.r.l" 1385 "Pro Charging Systems" 1389 "EVEX" 1398 "Gobius Sensor Technology" 1403 "Arco Marine" 1408 "Lenco Marine" 1413 "Naocontrol" 1417 "Revatek" 1438 "Aeolionics" 1439 "PredictWind" 1440 "Egis Mobile Electric" 1445 "Starboard Yacht Group" 1446 "Roswell Marine" 1451 "ePropulsion (Guangdong ePropulsion Technology Ltd.)" 1452 "Micro-Air" 1453 "Vital Battery" 1458 "Ride Controller" 1460 "Tocaro Blue" 1461 "Vanquish Yachts" 1471 "FT Technologies" 1478 "Alps Alpine" 1481 "E-Force Marine" 1482 "CMC Marine" 1483 "Nanjing Sandemarine Information Technology" 1850 "Teleflex Marine (SeaStar Solutions)" 1851 "Raymarine" 1852 "Navionics" 1853 "Japan Radio" 1854 "Northstar Technologies" 1855 "Furuno" 1856 "Trimble" 1857 "Simrad" 1858 "Litton" 1859 "Kvasar" 1860 "MMP" 1861 "Vector Cantech" 1862 "Yamaha Marine" 1863 "Faria Instruments" ;
VAL_ 2382300672 Industry_Code 0 "Global" 1 "Highway" 2 "Agriculture" 3 "Construction" 4 "Marine Industry" 5 "Industrial" ;
VAL_ 2382300672 Manufacturer_Code 69 "ARKS Enterprises" 78 "FW Murphy/Enovation Controls" 80 "Twin Disc" 85 "Kohler Power Systems" 88 "Hemisphere GPS" 135 "Airmar" 137 "Maretron" 140 "Lowrance" 144 "Mercury Marine" 147 "Nautibus Electronic" 148 "Blue Water Data" 154 "Westerbeke" 157 "ISSPRO" 161 "Offshore Systems (UK)" 163 "Evinrude/BRP" 165 "CPAC Systems" 168 "Xantrex Technology" 169 "Marlin Technologies" 172 "Yanmar Marine" 174 "Volvo Penta" 176 "Carling Technologies Inc. (Moritz Aerospace)" 185 "Beede Instruments" 192 "Floscan Instrument" 193 "Nobeltec" 198 "Mystic Valley Communications" 199 "Actia" 201 "Disenos Y Technologia" 211 "Digital Switching Systems" 215 "Xintex/Atena" 224 "EMMI NETWORK" 228 "ZF" 229 "Garmin" 233 "Yacht Monitoring Solutions" 235 "Sailormade Marine Telemetry/Tetra Technology" 243 "Eride" 257 "Honda Motor" 272 "Groco" 273 "Actisense" 274 "Amphenol LTW Technology" 275 "Navico" 283 "Hamilton Jet" 285 "Sea Recovery" 286 "Coelmo SRL Italy" 295 "BEP Marine" 304 "Empir Bus" 305 "NovAtel" 306 "Sleipner Motor" 307 "MBW Technologies" 315 "ICOM" 328 "Qwerty" 329 "Dief" 341 "Boening Automationstechnologie" 345 "Korean Maritime University" 351 "Thrane and Thrane" 355 "Mastervolt" 356 "Fischer Panda Generators" 358 "Victron Energy" 370 "Rolls Royce Marine" 373 "Electronic Design" 374 "Northern Lights" 378 "Glendinning" 381 "B & G" 384 "Rose Point Navigation Systems" 385 "Johnson Outdoors Marine Electronics Inc Geonav" 394 "Capi 2" 396 "Beyond Measure" 400 "Livorsi Marine" 404 "ComNav" 409 "Chetco" 419 "Fusion Electronics" 421 "Standard Horizon" 422 "True Heading" 426 "Egersund Marine Electronics" 427 "em-trak Marine Electronics" 431 "Tohatsu Co, JP" 437 "Digital Yacht" 438 "Comar Systems Limited" 440 "Cummins" 443 "VDO (aka Continental-Corporation)" 451 "Parker Hannifin aka Village Marine Tech" 459 "Alltek Marine Electronics" 460 "SAN GIORGIO S.E.I.N" 466 "Veethree Electronics & Marine" 470 "SI-TEX Marine Electronics" 471 "Sea Cross Marine" 475 "GME aka Standard Communications" 476 "Humminbird Marine Electronics" 478 "Ocean Sat" 481 "Chetco Digital Instruments" 493 "Watcheye" 499 "Lcj Capteurs" 502 "Attwood Marine" 503 "Naviop S.R.L." 504 "Vesper Marine" 510 "Marinesoft" 513 "Simarine" 517 "NoLand Engineering" 518 "Transas USA" 529 "National Instruments Korea" 530 "National Marine Electronics Association" 532 "Onwa Marine" 540 "Webasto" 571 "Marinecraft (South Korea)" 573 "McMurdo Group aka Orolia" 578 "Advansea" 579 "KVH" 580 "San Jose Technology" 583 "Yacht Control" 586 "Suzuki Motor" 591 "US Coast Guard" 595 "Ship Module aka Customware" 600 "Aquatic AV" 605 "Aventics" 606 "Intellian" 612 "SamwonIT" 614 "Arlt Tecnologies" 637 "Bavaria Yachts" 641 "Diverse Yacht Services" 644 "Wema U.S.A dba KUS" 658 "Shenzhen Jiuzhou Himunication" 688 "Rockford" 699 "Harman International" 704 "JL Audio" 708 "Lars Thrane" 715 "Autonnic" 717 "Yacht Devices" 734 "REAP Systems" 735 "AEM Performance Electronics" 739 "LxNav" 741 "Littelfuse, Inc (formerly Carling Technologies)" 743 "DaeMyung" 744 "Woosung" 748 "ISOTTA IFRA srl" 773 "Clarion US" 776 "HMI Systems" 777 "Ocean Signal" 778 "Seakeeper" 781 "Poly Planar" 785 "Fischer Panda DE" 795 "Broyda Industries" 796 "Canadian Automotive" 797 "Tides Marine" 798 "Lumishore" 799 "Still Water Designs and Audio" 802 "BJ Technologies (Beneteau)" 803 "Gill Sensors" 811 "Blue Water Desalination" 815 "FLIR" 824 "Undheim Systems" 826 "Lewmar" 838 "TeamSurv" 844 "Fell Marine" 847 "Oceanvolt" 862 "Prospec" 868 "Data Panel" 890 "L3 Technologies" 894 "Rhodan Marine Systems" 896 "Nexfour Solutions" 905 "ASA Electronics" 909 "Marines Co (South Korea)" 911 "Nautic-on" 917 "Sentinel" 929 "JL Marine Systems" 930 "Ecotronix" 944 "Zontisa Marine" 951 "EXOR International" 962 "Timbolier Industries" 963 "TJC Micro" 968 "Cox Powertrain" 969 "Blue Seas" 981 "Kobelt Manufacturing" 992 "Blue Ocean IOT" 997 "Xenta Systems" 999 "Signal K" 1004 "Ultraflex" 1008 "Lintest SmartBoat" 1011 "Soundmax" 1020 "Team Italia Marine (Onyx Marine Automation s.r.l)" 1021 "Entratech" 1022 "ITC" 1029 "The Marine Guardian" 1047 "Sonic" 1051 "ProNav" 1053 "Vetus Maxwell INC." 1056 "Lithium Pros" 1059 "Boatrax" 1062 "Marol Co ltd" 1065 "CALYPSO Instruments" 1066 "Spot Zero Water" 1069 "Lithionics Battery" 1070 "Quick-teck Electronics" 1075 "Uniden America" 1083 "Nauticoncept" 1084 "Shadow-Caster LED lighting" 1085 "Wet Sounds" 1088 "E-T-A Circuit Breakers" 1092 "Scheiber" 1100 "Smart Yachts International Limited" 1109 "Dockmate" 1114 "Bobs Machine" 1118 "L3Harris ASV" 1119 "Balmar" 1120 "Elettromedia" 1127 "Electromaax" 1140 "Across Oceans Systems" 1145 "Kiwi Yachting" 1150 "BSB Artificial Intelligence" 1151 "Orca Technologies" 1154 "TBS Electronics" 1158 "Technoton Electroics" 1160 "MG Energy Systems" 1169 "Sea Machine Robotics" 1171 "Vista Manufacturing" 1183 "Zipwake" 1186 "Sailmon" 1192 "Airmoniq Pro Kft" 1194 "Sierra Marine" 1200 "Xinuo Information Technology (Xiamen)" 1218 "Septentrio" 1233 "NKE Marine Electronics" 1238 "SuperTrack Aps" 1239 "Honda Electronics" 1245 "Raritan Engineering" 1249 "Integrated Power Solutions AG" 1260 "Interactive Technologies" 1283 "LTG-Tech" 1299 "Energy Solutions (UK)" 1300 "WATT Fuel Cell" 1302 "Pro Mainer" 1305 "Dragonfly Energy" 1306 "Koden Electronics" 1311 "Humphree" 1316 "Hinkley Yachts" 1317 "Global Marine Management GmbH (GMM)" 1320 "Triskel Marine" 1330 "Warwick Control Technologies" 1331 "Dolphin Charger" 1337 "Barnacle Systems" 1348 "Radian IoT" 1353 "Ocean LED Marine" 1359 "BluNav" 1361 "OVA (Nantong Saiyang Electronics Co., Ltd)" 1368 "RAD Propulsion" 1369 "Electric Yacht" 1372 "Elco Motor Yachts" 1384 "Tecnoseal Foundry S.r.l" 1385 "Pro Charging Systems" 1389 "EVEX" 1398 "Gobius Sensor Technology" 1403 "Arco Marine" 1408 "Lenco Marine" 1413 "Naocontrol" 1417 "Revatek" 1438 "Aeolionics" 1439 "PredictWind" 1440 "Egis Mobile Electric" 1445 "Starboard Yacht Group" 1446 "Roswell Marine" 1451 "ePropulsion (Guangdong ePropulsion Technology Ltd.)" 1452 "Micro-Air" 1453 "Vital Battery" 1458 "Ride Controller" 1460 "Tocaro Blue" 1461 "Vanquish Yachts" 1471 "FT Technologies" 1478 "Alps Alpine" 1481 "E-Force Marine" 1482 "CMC Marine" 1483 "Nanjing Sandemarine Information Technology" 1850 "Teleflex Marine (SeaStar Solutions)" 1851 "Raymarine" 1852 "Navionics" 1853 "Japan Radio" 1854 "Northstar Technologies" 1855 "Furuno" 1856 "Trimble" 1857 "Simrad" 1858 "Litton" 1859 "Kvasar" 1860 "MMP" 1861 "Vector Cantech" 1862 "Yamaha Marine" 1863 "Faria Instruments" ;
VAL_ 2382300672 Industry_Code 0 "Global" 1 "Highway" 2 "Agriculture" 3 "Construction" 4 "Marine Industry" 5 "Industrial" ;
VAL_ 2382300672 Manufacturer_Code 69 "ARKS Enterprises" 78 "FW Murphy/Enovation Controls" 80 "Twin Disc" 85 "Kohler Power Systems" 88 "Hemisphere GPS" 135 "Airmar" 137 "Maretron" 140 "Lowrance" 144 "Mercury Marine" 147 "Nautibus Electronic" 148 "Blue Water Data" 154 "Westerbeke" 157 "ISSPRO" 161 "Offshore Systems (UK)" 163 "Evinrude/BRP" 165 "CPAC Systems" 168 "Xantrex Technology" 169 "Marlin Technologies" 172 "Yanmar Marine" 174 "Volvo Penta" 176 "Carling Technologies Inc. (Moritz Aerospace)" 185 "Beede Instruments" 192 "Floscan Instrument" 193 "Nobeltec" 198 "Mystic Valley Communications" 199 "Actia" 201 "Disenos Y Technologia" 211 "Digital Switching Systems" 215 "Xintex/Atena" 224 "EMMI NETWORK" 228 "ZF" 229 "Garmin" 233 "Yacht Monitoring Solutions" 235 "Sailormade Marine Telemetry/Tetra Technology" 243 "Eride" 257 "Honda Motor" 272 "Groco" 273 "Actisense" 274 "Amphenol LTW Technology" 275 "Navico" 283 "Hamilton Jet" 285 "Sea Recovery" 286 "Coelmo SRL Italy" 295 "BEP Marine" 304 "Empir Bus" 305 "NovAtel" 306 "Sleipner Motor" 307 "MBW Technologies" 315 "ICOM" 328 "Qwerty" 329 "Dief" 341 "Boening Automationstechnologie" 345 "Korean Maritime University" 351 "Thrane and Thrane" 355 "Mastervolt" 356 "Fischer Panda Generators" 358 "Victron Energy" 370 "Rolls Royce Marine" 373 "Electronic Design" 374 "Northern Lights" 378 "Glendinning" 381 "B & G" 384 "Rose Point Navigation Systems" 385 "Johnson Outdoors Marine Electronics Inc Geonav" 394 "Capi 2" 396 "Beyond Measure" 400 "Livorsi Marine" 404 "ComNav" 409 "Chetco" 419 "Fusion Electronics" 421 "Standard Horizon" 422 "True Heading" 426 "Egersund Marine Electronics" 427 "em-trak Marine Electronics" 431 "Tohatsu Co, JP" 437 "Digital Yacht" 438 "Comar Systems Limited" 440 "Cummins" 443 "VDO (aka Continental-Corporation)" 451 "Parker Hannifin aka Village Marine Tech" 459 "Alltek Marine Electronics" 460 "SAN GIORGIO S.E.I.N" 466 "Veethree Electronics & Marine" 470 "SI-TEX Marine Electronics" 471 "Sea Cross Marine" 475 "GME aka Standard Communications" 476 "Humminbird Marine Electronics" 478 "Ocean Sat" 481 "Chetco Digital Instruments" 493 "Watcheye" 499 "Lcj Capteurs" 502 "Attwood Marine" 503 "Naviop S.R.L." 504 "Vesper Marine" 510 "Marinesoft" 513 "Simarine" 517 "NoLand Engineering" 518 "Transas USA" 529 "National Instruments Korea" 530 "National Marine Electronics Association" 532 "Onwa Marine" 540 "Webasto" 571 "Marinecraft (South Korea)" 573 "McMurdo Group aka Orolia" 578 "Advansea" 579 "KVH" 580 "San Jose Technology" 583 "Yacht Control" 586 "Suzuki Motor" 591 "US Coast Guard" 595 "Ship Module aka Customware" 600 "Aquatic AV" 605 "Aventics" 606 "Intellian" 612 "SamwonIT" 614 "Arlt Tecnologies" 637 "Bavaria Yachts" 641 "Diverse Yacht Services" 644 "Wema U.S.A dba KUS" 658 "Shenzhen Jiuzhou Himunication" 688 "Rockford" 699 "Harman International" 704 "JL Audio" 708 "Lars Thrane" 715 "Autonnic" 717 "Yacht Devices" 734 "REAP Systems" 735 "AEM Performance Electronics" 739 "LxNav" 741 "Littelfuse, Inc (formerly Carling Technologies)" 743 "DaeMyung" 744 "Woosung" 748 "ISOTTA IFRA srl" 773 "Clarion US" 776 "HMI Systems" 777 "Ocean Signal" 778 "Seakeeper" 781 "Poly Planar" 785 "Fischer Panda DE" 795 "Broyda Industries" 796 "Canadian Automotive" 797 "Tides Marine" 798 "Lumishore" 799 "Still Water Designs and Audio" 802 "BJ Technologies (Beneteau)" 803 "Gill Sensors" 811 "Blue Water Desalination" 815 "FLIR" 824 "Undheim Systems" 826 "Lewmar" 838 "TeamSurv" 844 "Fell Marine" 847 "Oceanvolt" 862 "Prospec" 868 "Data Panel" 890 "L3 Technologies" 894 "Rhodan Marine Systems" 896 "Nexfour Solutions" 905 "ASA Electronics" 909 "Marines Co (South Korea)" 911 "Nautic-on" 917 "Sentinel" 929 "JL Marine Systems" 930 "Ecotronix" 944 "Zontisa Marine" 951 "EXOR International" 962 "Timbolier Industries" 963 "TJC Micro" 968 "Cox Powertrain" 969 "Blue Seas" 981 "Kobelt Manufacturing" 992 "Blue Ocean IOT" 997 "Xenta Systems" 999 "Signal K" 1004 "Ultraflex" 1008 "Lintest SmartBoat" 1011 "Soundmax" 1020 "Team Italia Marine (Onyx Marine Automation s.r.l)" 1021 "Entratech" 1022 "ITC" 1029 "The Marine Guardian" 1047 "Sonic" 1051 "ProNav" 1053 "Vetus Maxwell INC." 1056 "Lithium Pros" 1059 "Boatrax" 1062 "Marol Co ltd" 1065 "CALYPSO Instruments" 1066 "Spot Zero Water" 1069 "Lithionics Battery" 1070 "Quick-teck Electronics" 1075 "Uniden America" 1083 "Nauticoncept" 1084 "Shadow-Caster LED lighting" 1085 "Wet Sounds" 1088 "E-T-A Circuit Breakers" 1092 "Scheiber" 1100 "Smart Yachts International Limited" 1109 "Dockmate" 1114 "Bobs Machine" 1118 "L3Harris ASV" 1119 "Balmar" 1120 "Elettromedia" 1127 "Electromaax" 1140 "Across Oceans Systems" 1145 "Kiwi Yachting" 1150 "BSB Artificial Intelligence" 1151 "Orca Technologies" 1154 "TBS Electronics" 1158 "Technoton Electroics" 1160 "MG Energy Systems" 1169 "Sea Machine Robotics" 1171 "Vista Manufacturing" 1183 "Zipwake" 1186 "Sailmon" 1192 "Airmoniq Pro Kft" 1194 "Sierra Marine" 1200 "Xinuo Information Technology (Xiamen)" 1218 "Septentrio" 1233 "NKE Marine Electronics" 1238 "SuperTrack Aps" 1239 "Honda Electronics" 1245 "Raritan Engineering" 1249 "Integrated Power Solutions AG" 1260 "Interactive Technologies" 1283 "LTG-Tech" 1299 "Energy Solutions (UK)" 1300 "WATT Fuel Cell" 1302 "Pro Mainer" 1305 "Dragonfly Energy" 1306 "Koden Electronics" 1311 "Humphree" 1316 "Hinkley Yachts" 1317 "Global Marine Management GmbH (GMM)" 1320 "Triskel Marine" 1330 "Warwick Control Technologies" 1331 "Dolphin Charger" 1337 "Barnacle Systems" 1348 "Radian IoT" 1353 "Ocean LED Marine" 1359 "BluNav" 1361 "OVA (Nantong Saiyang Electronics Co., Ltd)" 1368 "RAD Propulsion" 1369 "Electric Yacht" 1372 "Elco Motor Yachts" 1384 "Tecnoseal Foundry S.r.l" 1385 "Pro Charging Systems" 1389 "EVEX" 1398 "Gobius Sensor Technology" 1403 "Arco Marine" 1408 "Lenco Marine" 1413 "Naocontrol" 1417 "Revatek" 1438 "Aeolionics" 1439 "PredictWind" 1440 "Egis Mobile Electric" 1445 "Starboard Yacht Group" 1446 "Roswell Marine" 1451 "ePropulsion (Guangdong ePropulsion Technology Ltd.)" 1452 "Micro-Air" 1453 "Vital Battery" 1458 "Ride Controller" 1460 "Tocaro Blue" 1461 "Vanquish Yachts" 1471 "FT Technologies" 1478 "Alps Alpine" 1481 "E-Force Marine" 1482 "CMC Marine" 1483 "Nanjing Sandemarine Information Technology" 1850 "Teleflex Marine (SeaStar Solutions)" 1851 "Raymarine" 1852 "Navionics" 1853 "Japan Radio" 1854 "Northstar Technologies" 1855 "Furuno" 1856 "Trimble" 1857 "Simrad" 1858 "Litton" 1859 "Kvasar" 1860 "MMP" 1861 "Vector Cantech" 1862 "Yamaha Marine" 1863 "Faria Instruments" ;
VAL_ 2382300672 Industry_Code 0 "Global" 1 "Highway" 2 "Agriculture" 3 "Construction" 4 "Marine Industry" 5 "Industrial" ;
VAL_ 2382300672 Manufacturer_Code 69 "ARKS Enterprises" 78 "FW Murphy/Enovation Controls" 80 "Twin Disc" 85 "Kohler Power Systems" 88 "Hemisphere GPS" 135 "Airmar" 137 "Maretron" 140 "Lowrance" 144 "Mercury Marine" 147 "Nautibus Electronic" 148 "Blue Water Data" 154 "Westerbeke" 157 "ISSPRO" 161 "Offshore Systems (UK)" 163 "Evinrude/BRP" 165 "CPAC Systems" 168 "Xantrex Technology" 169 "Marlin Technologies" 172 "Yanmar Marine" 174 "Volvo Penta" 176 "Carling Technologies Inc. (Moritz Aerospace)" 185 "Beede Instruments" 192 "Floscan Instrument" 193 "Nobeltec" 198 "Mystic Valley Communications" 199 "Actia" 201 "Disenos Y Technologia" 211 "Digital Switching Systems" 215 "Xintex/Atena" 224 "EMMI NETWORK" 228 "ZF" 229 "Garmin" 233 "Yacht Monitoring Solutions" 235 "Sailormade Marine Telemetry/Tetra Technology" 243 "Eride" 257 "Honda Motor" 272 "Groco" 273 "Actisense" 274 "Amphenol LTW Technology" 275 "Navico" 283 "Hamilton Jet" 285 "Sea Recovery" 286 "Coelmo SRL Italy" 295 "BEP Marine" 304 "Empir Bus" 305 "NovAtel" 306 "Sleipner Motor" 307 "MBW Technologies" 315 "ICOM" 328 "Qwerty" 329 "Dief" 341 "Boening Automationstechnologie" 345 "Korean Maritime University" 351 "Thrane and Thrane" 355 "Mastervolt" 356 "Fischer Panda Generators" 358 "Victron Energy" 370 "Rolls Royce Marine" 373 "Electronic Design" 374 "Northern Lights" 378 "Glendinning" 381 "B & G" 384 "Rose Point Navigation Systems" 385 "Johnson Outdoors Marine Electronics Inc Geonav" 394 "Capi 2" 396 "Beyond Measure" 400 "Livorsi Marine" 404 "ComNav" 409 "Chetco" 419 "Fusion Electronics" 421 "Standard Horizon" 422 "True Heading" 426 "Egersund Marine Electronics" 427 "em-trak Marine Electronics" 431 "Tohatsu Co, JP" 437 "Digital Yacht" 438 "Comar Systems Limited" 440 "Cummins" 443 "VDO (aka Continental-Corporation)" 451 "Parker Hannifin aka Village Marine Tech" 459 "Alltek Marine Electronics" 460 "SAN GIORGIO S.E.I.N" 466 "Veethree Electronics & Marine" 470 "SI-TEX Marine Electronics" 471 "Sea Cross Marine" 475 "GME aka Standard Communications" 476 "Humminbird Marine Electronics" 478 "Ocean Sat" 481 "Chetco Digital Instruments" 493 "Watcheye" 499 "Lcj Capteurs" 502 "Attwood Marine" 503 "Naviop S.R.L." 504 "Vesper Marine" 510 "Marinesoft" 513 "Simarine" 517 "NoLand Engineering" 518 "Transas USA" 529 "National Instruments Korea" 530 "National Marine Electronics Association" 532 "Onwa Marine" 540 "Webasto" 571 "Marinecraft (South Korea)" 573 "McMurdo Group aka Orolia" 578 "Advansea" 579 "KVH" 580 "San Jose Technology" 583 "Yacht Control" 586 "Suzuki Motor" 591 "US Coast Guard" 595 "Ship Module aka Customware" 600 "Aquatic AV" 605 "Aventics" 606 "Intellian" 612 "SamwonIT" 614 "Arlt Tecnologies" 637 "Bavaria Yachts" 641 "Diverse Yacht Services" 644 "Wema U.S.A dba KUS" 658 "Shenzhen Jiuzhou Himunication" 688 "Rockford" 699 "Harman International" 704 "JL Audio" 708 "Lars Thrane" 715 "Autonnic" 717 "Yacht Devices" 734 "REAP Systems" 735 "AEM Performance Electronics" 739 "LxNav" 741 "Littelfuse, Inc (formerly Carling Technologies)" 743 "DaeMyung" 744 "Woosung" 748 "ISOTTA IFRA srl" 773 "Clarion US" 776 "HMI Systems" 777 "Ocean Signal" 778 "Seakeeper" 781 "Poly Planar" 785 "Fischer Panda DE" 795 "Broyda Industries" 796 "Canadian Automotive" 797 "Tides Marine" 798 "Lumishore" 799 "Still Water Designs and Audio" 802 "BJ Technologies (Beneteau)" 803 "Gill Sensors" 811 "Blue Water Desalination" 815 "FLIR" 824 "Undheim Systems" 826 "Lewmar" 838 "TeamSurv" 844 "Fell Marine" 847 "Oceanvolt" 862 "Prospec" 868 "Data Panel" 890 "L3 Technologies" 894 "Rhodan Marine Systems" 896 "Nexfour Solutions" 905 "ASA Electronics" 909 "Marines Co (South Korea)" 911 "Nautic-on" 917 "Sentinel" 929 "JL Marine Systems" 930 "Ecotronix" 944 "Zontisa Marine" 951 "EXOR International" 962 "Timbolier Industries" 963 "TJC Micro" 968 "Cox Powertrain" 969 "Blue Seas" 981 "Kobelt Manufacturing" 992 "Blue Ocean IOT" 997 "Xenta Systems" 999 "Signal K" 1004 "Ultraflex" 1008 "Lintest SmartBoat" 1011 "Soundmax" 1020 "Team Italia Marine (Onyx Marine Automation s.r.l)" 1021 "Entratech" 1022 "ITC" 1029 "The Marine Guardian" 1047 "Sonic" 1051 "ProNav" 1053 "Vetus Maxwell INC." 1056 "Lithium Pros" 1059 "Boatrax" 1062 "Marol Co ltd" 1065 "CALYPSO Instruments" 1066 "Spot Zero Water" 1069 "Lithionics Battery" 1070 "Quick-teck Electronics" 1075 "Uniden America" 1083 "Nauticoncept" 1084 "Shadow-Caster LED lighting" 1085 "Wet Sounds" 1088 "E-T-A Circuit Breakers" 1092 "Scheiber" 1100 "Smart Yachts International Limited" 1109 "Dockmate" 1114 "Bobs Machine" 1118 "L3Harris ASV" 1119 "Balmar" 1120 "Elettromedia" 1127 "Electromaax" 1140 "Across Oceans Systems" 1145 "Kiwi Yachting" 1150 "BSB Artificial Intelligence" 1151 "Orca Technologies" 1154 "TBS Electronics" 1158 "Technoton Electroics" 1160 "MG Energy Systems" 1169 "Sea Machine Robotics" 1171 "Vista Manufacturing" 1183 "Zipwake" 1186 "Sailmon" 1192 "Airmoniq Pro Kft" 1194 "Sierra Marine" 1200 "Xinuo Information Technology (Xiamen)" 1218 "Septentrio" 1233 "NKE Marine Electronics" 1238 "SuperTrack Aps" 1239 "Honda Electronics" 1245 "Raritan Engineering" 1249 "Integrated Power Solutions AG" 1260 "Interactive Technologies" 1283 "LTG-Tech" 1299 "Energy Solutions (UK)" 1300 "WATT Fuel Cell" 1302 "Pro Mainer" 1305 "Dragonfly Energy" 1306 "Koden Electronics" 1311 "Humphree" 1316 "Hinkley Yachts" 1317 "Global Marine Management GmbH (GMM)" 1320 "Triskel Marine" 1330 "Warwick Control Technologies" 1331 "Dolphin Charger" 1337 "Barnacle Systems" 1348 "Radian IoT" 1353 "Ocean LED Marine" 1359 "BluNav" 1361 "OVA (Nantong Saiyang Electronics Co., Ltd)" 1368 "RAD Propulsion" 1369 "Electric Yacht" 1372 "Elco Motor Yachts" 1384 "Tecnoseal Foundry S.r.l" 1385 "Pro Charging Systems" 1389 "EVEX" 1398 "Gobius Sensor Technology" 1403 "Arco Marine" 1408 "Lenco Marine" 1413 "Naocontrol" 1417 "Revatek" 1438 "Aeolionics" 1439 "PredictWind" 1440 "Egis Mobile Electric" 1445 "Starboard Yacht Group" 1446 "Roswell Marine" 1451 "ePropulsion (Guangdong ePropulsion Technology Ltd.)" 1452 "Micro-Air" 1453 "Vital Battery" 1458 "Ride Controller" 1460 "Tocaro Blue" 1461 "Vanquish Yachts" 1471 "FT Technologies" 1478 "Alps Alpine" 1481 "E-Force Marine" 1482 "CMC Marine" 1483 "Nanjing Sandemarine Information Technology" 1850 "Teleflex Marine (SeaStar Solutions)" 1851 "Raymarine" 1852 "Navionics" 1853 "Japan Radio" 1854 "Northstar Technologies" 1855 "Furuno" 1856 "Trimble" 1857 "Simrad" 1858 "Litton" 1859 "Kvasar" 1860 "MMP" 1861 "Vector Cantech" 1862 "Yamaha Marine" 1863 "Faria Instruments" ;
VAL_ 2382300672 Industry_Code 0 "Global" 1 "Highway" 2 "Agriculture" 3 "Construction" 4 "Marine Industry" 5 "Industrial" ;
VAL_ 2382300672 Manufacturer_Code 69 "ARKS Enterprises" 78 "FW Murphy/Enovation Controls" 80 "Twin Disc" 85 "Kohler Power Systems" 88 "Hemisphere GPS" 135 "Airmar" 137 "Maretron" 140 "Lowrance" 144 "Mercury Marine" 147 "Nautibus Electronic" 148 "Blue Water Data" 154 "Westerbeke" 157 "ISSPRO" 161 "Offshore Systems (UK)" 163 "Evinrude/BRP" 165 "CPAC Systems" 168 "Xantrex Technology" 169 "Marlin Technologies" 172 "Yanmar Marine" 174 "Volvo Penta" 176 "Carling Technologies Inc. (Moritz Aerospace)" 185 "Beede Instruments" 192 "Floscan Instrument" 193 "Nobeltec" 198 "Mystic Valley Communications" 199 "Actia" 201 "Disenos Y Technologia" 211 "Digital Switching Systems" 215 "Xintex/Atena" 224 "EMMI NETWORK" 228 "ZF" 229 "Garmin" 233 "Yacht Monitoring Solutions" 235 "Sailormade Marine Telemetry/Tetra Technology" 243 "Eride" 257 "Honda Motor" 272 "Groco" 273 "Actisense" 274 "Amphenol LTW Technology" 275 "Navico" 283 "Hamilton Jet" 285 "Sea Recovery" 286 "Coelmo SRL Italy" 295 "BEP Marine" 304 "Empir Bus" 305 "NovAtel" 306 "Sleipner Motor" 307 "MBW Technologies" 315 "ICOM" 328 "Qwerty" 329 "Dief" 341 "Boening Automationstechnologie" 345 "Korean Maritime University" 351 "Thrane and Thrane" 355 "Mastervolt" 356 "Fischer Panda Generators" 358 "Victron Energy" 370 "Rolls Royce Marine" 373 "Electronic Design" 374 "Northern Lights" 378 "Glendinning" 381 "B & G" 384 "Rose Point Navigation Systems" 385 "Johnson Outdoors Marine Electronics Inc Geonav" 394 "Capi 2" 396 "Beyond Measure" 400 "Livorsi Marine" 404 "ComNav" 409 "Chetco" 419 "Fusion Electronics" 421 "Standard Horizon" 422 "True Heading" 426 "Egersund Marine Electronics" 427 "em-trak Marine Electronics" 431 "Tohatsu Co, JP" 437 "Digital Yacht" 438 "Comar Systems Limited" 440 "Cummins" 443 "VDO (aka Continental-Corporation)" 451 "Parker Hannifin aka Village Marine Tech" 459 "Alltek Marine Electronics" 460 "SAN GIORGIO S.E.I.N" 466 "Veethree Electronics & Marine" 470 "SI-TEX Marine Electronics" 471 "Sea Cross Marine" 475 "GME aka Standard Communications" 476 "Humminbird Marine Electronics" 478 "Ocean Sat" 481 "Chetco Digital Instruments" 493 "Watcheye" 499 "Lcj Capteurs" 502 "Attwood Marine" 503 "Naviop S.R.L." 504 "Vesper Marine" 510 "Marinesoft" 513 "Simarine" 517 "NoLand Engineering" 518 "Transas USA" 529 "National Instruments Korea" 530 "National Marine Electronics Association" 532 "Onwa Marine" 540 "Webasto" 571 "Marinecraft (South Korea)" 573 "McMurdo Group aka Orolia" 578 "Advansea" 579 "KVH" 580 "San Jose Technology" 583 "Yacht Control" 586 "Suzuki Motor" 591 "US Coast Guard" 595 "Ship Module aka Customware" 600 "Aquatic AV" 605 "Aventics" 606 "Intellian" 612 "SamwonIT" 614 "Arlt Tecnologies" 637 "Bavaria Yachts" 641 "Diverse Yacht Services" 644 "Wema U.S.A dba KUS" 658 "Shenzhen Jiuzhou Himunication" 688 "Rockford" 699 "Harman International" 704 "JL Audio" 708 "Lars Thrane" 715 "Autonnic" 717 "Yacht Devices" 734 "REAP Systems" 735 "AEM Performance Electronics" 739 "LxNav" 741 "Littelfuse, Inc (formerly Carling Technologies)" 743 "DaeMyung" 744 "Woosung" 748 "ISOTTA IFRA srl" 773 "Clarion US" 776 "HMI Systems" 777 "Ocean Signal" 778 "Seakeeper" 781 "Poly Planar" 785 "Fischer Panda DE" 795 "Broyda Industries" 796 "Canadian Automotive" 797 "Tides Marine" 798 "Lumishore" 799 "Still Water Designs and Audio" 802 "BJ Technologies (Beneteau)" 803 "Gill Sensors" 811 "Blue Water Desalination" 815 "FLIR" 824 "Undheim Systems" 826 "Lewmar" 838 "TeamSurv" 844 "Fell Marine" 847 "Oceanvolt" 862 "Prospec" 868 "Data Panel" 890 "L3 Technologies" 894 "Rhodan Marine Systems" 896 "Nexfour Solutions" 905 "ASA Electronics" 909 "Marines Co (South Korea)" 911 "Nautic-on" 917 "Sentinel" 929 "JL Marine Systems" 930 "Ecotronix" 944 "Zontisa Marine" 951 "EXOR International" 962 "Timbolier Industries" 963 "TJC Micro" 968 "Cox Powertrain" 969 "Blue Seas" 981 "Kobelt Manufacturing" 992 "Blue Ocean IOT" 997 "Xenta Systems" 999 "Signal K" 1004 "Ultraflex" 1008 "Lintest SmartBoat" 1011 "Soundmax" 1020 "Team Italia Marine (Onyx Marine Automation s.r.l)" 1021 "Entratech" 1022 "ITC" 1029 "The Marine Guardian" 1047 "Sonic" 1051 "ProNav" 1053 "Vetus Maxwell INC." 1056 "Lithium Pros" 1059 "Boatrax" 1062 "Marol Co ltd" 1065 "CALYPSO Instruments" 1066 "Spot Zero Water" 1069 "Lithionics Battery" 1070 "Quick-teck Electronics" 1075 "Uniden America" 1083 "Nauticoncept" 1084 "Shadow-Caster LED lighting" 1085 "Wet Sounds" 1088 "E-T-A Circuit Breakers" 1092 "Scheiber" 1100 "Smart Yachts International Limited" 1109 "Dockmate" 1114 "Bobs Machine" 1118 "L3Harris ASV" 1119 "Balmar" 1120 "Elettromedia" 1127 "Electromaax" 1140 "Across Oceans Systems" 1145 "Kiwi Yachting" 1150 "BSB Artificial Intelligence" 1151 "Orca Technologies" 1154 "TBS Electronics" 1158 "Technoton Electroics" 1160 "MG Energy Systems" 1169 "Sea Machine Robotics" 1171 "Vista Manufacturing" 1183 "Zipwake" 1186 "Sailmon" 1192 "Airmoniq Pro Kft" 1194 "Sierra Marine" 1200 "Xinuo Information Technology (Xiamen)" 1218 "Septentrio" 1233 "NKE Marine Electronics" 1238 "SuperTrack Aps" 1239 "Honda Electronics" 1245 "Raritan Engineering" 1249 "Integrated Power Solutions AG" 1260 "Interactive Technologies" 1283 "LTG-Tech" 1299 "Energy Solutions (UK)" 1300 "WATT Fuel Cell" 1302 "Pro Mainer" 1305 "Dragonfly Energy" 1306 "Koden Electronics" 1311 "Humphree" 1316 "Hinkley Yachts" 1317 "Global Marine Management GmbH (GMM)" 1320 "Triskel Marine" 1330 "Warwick Control Technologies" 1331 "Dolphin Charger" 1337 "Barnacle Systems" 1348 "Radian IoT" 1353 "Ocean LED Marine" 1359 "BluNav" 1361 "OVA (Nantong Saiyang Electronics Co., Ltd)" 1368 "RAD Propulsion" 1369 "Electric Yacht" 1372 "Elco Motor Yachts" 1384 "Tecnoseal Foundry S.r.l" 1385 "Pro Charging Systems" 1389 "EVEX" 1398 "Gobius Sensor Technology" 1403 "Arco Marine" 1408 "Lenco Marine" 1413 "Naocontrol" 1417 "Revatek" 1438 "Aeolionics" 1439 "PredictWind" 1440 "Egis Mobile Electric" 1445 "Starboard Yacht Group" 1446 "Roswell Marine" 1451 "ePropulsion (Guangdong ePropulsion Technology Ltd.)" 1452 "Micro-Air" 1453 "Vital Battery" 1458 "Ride Controller" 1460 "Tocaro Blue" 1461 "Vanquish Yachts" 1471 "FT Technologies" 1478 "Alps Alpine" 1481 "E-Force Marine" 1482 "CMC Marine" 1483 "Nanjing Sandemarine Information Technology" 1850 "Teleflex Marine (SeaStar Solutions)" 1851 "Raymarine" 1852 "Navionics" 1853 "Japan Radio" 1854 "Northstar Technologies" 1855 "Furuno" 1856 "Trimble" 1857 "Simrad" 1858 "Litton" 1859 "Kvasar" 1860 "MMP" 1861 "Vector Cantech" 1862 "Yamaha Marine" 1863 "Faria Instruments" ;
VAL_ 2382300672 Industry_Code 0 "Global" 1 "Highway" 2 "Agriculture" 3 "Construction" 4 "Marine Industry" 5 "Industrial" ;
VAL_ 2382300928 Manufacturer_Code 69 "ARKS Enterprises" 78 "FW Murphy/Enovation Controls" 80 "Twin Disc" 85 "Kohler Power Systems" 88 "Hemisphere GPS" 135 "Airmar" 137 "Maretron" 140 "Lowrance" 144 "Mercury Marine" 147 "Nautibus Electronic" 148 "Blue Water Data" 154 "Westerbeke" 157 "ISSPRO" 161 "Offshore Systems (UK)" 163 "Evinrude/BRP" 165 "CPAC Systems" 168 "Xantrex Technology" 169 "Marlin Technologies" 172 "Yanmar Marine" 174 "Volvo Penta" 176 "Carling Technologies Inc. (Moritz Aerospace)" 185 "Beede Instruments" 192 "Floscan Instrument" 193 "Nobeltec" 198 "Mystic Valley Communications" 199 "Actia" 201 "Disenos Y Technologia" 211 "Digital Switching Systems" 215 "Xintex/Atena" 224 "EMMI NETWORK" 228 "ZF" 229 "Garmin" 233 "Yacht Monitoring Solutions" 235 "Sailormade Marine Telemetry/Tetra Technology" 243 "Eride" 257 "Honda Motor" 272 "Groco" 273 "Actisense" 274 "Amphenol LTW Technology" 275 "Navico" 283 "Hamilton Jet" 285 "Sea Recovery" 286 "Coelmo SRL Italy" 295 "BEP Marine" 304 "Empir Bus" 305 "NovAtel" 306 "Sleipner Motor" 307 "MBW Technologies" 315 "ICOM" 328 "Qwerty" 329 "Dief" 341 "Boening Automationstechnologie" 345 "Korean Maritime University" 351 "Thrane and Thrane" 355 "Mastervolt" 356 "Fischer Panda Generators" 358 "Victron Energy" 370 "Rolls Royce Marine" 373 "Electronic Design" 374 "Northern Lights" 378 "Glendinning" 381 "B & G" 384 "Rose Point Navigation Systems" 385 "Johnson Outdoors Marine Electronics Inc Geonav" 394 "Capi 2" 396 "Beyond Measure" 400 "Livorsi Marine" 404 "ComNav" 409 "Chetco" 419 "Fusion Electronics" 421 "Standard Horizon" 422 "True Heading" 426 "Egersund Marine Electronics" 427 "em-trak Marine Electronics" 431 "Tohatsu Co, JP" 437 "Digital Yacht" 438 "Comar Systems Limited" 440 "Cummins" 443 "VDO (aka Continental-Corporation)" 451 "Parker Hannifin aka Village Marine Tech" 459 "Alltek Marine Electronics" 460 "SAN GIORGIO S.E.I.N" 466 "Veethree Electronics & Marine" 470 "SI-TEX Marine Electronics" 471 "Sea Cross Marine" 475 "GME aka Standard Communications" 476 "Humminbird Marine Electronics" 478 "Ocean Sat" 481 "Chetco Digital Instruments" 493 "Watcheye" 499 "Lcj Capteurs" 502 "Attwood Marine" 503 "Naviop S.R.L." 504 "Vesper Marine" 510 "Marinesoft" 513 "Simarine" 517 "NoLand Engineering" 518 "Transas USA" 529 "National Instruments Korea" 530 "National Marine Electronics Association" 532 "Onwa Marine" 540 "Webasto" 571 "Marinecraft (South Korea)" 573 "McMurdo Group aka Orolia" 578 "Advansea" 579 "KVH" 580 "San Jose Technology" 583 "Yacht Control" 586 "Suzuki Motor" 591 "US Coast Guard" 595 "Ship Module aka Customware" 600 "Aquatic AV" 605 "Aventics" 606 "Intellian" 612 "SamwonIT" 614 "Arlt Tecnologies" 637 "Bavaria Yachts" 641 "Diverse Yacht Services" 644 "Wema U.S.A dba KUS" 658 "Shenzhen Jiuzhou Himunication" 688 "Rockford" 699 "Harman International" 704 "JL Audio" 708 "Lars Thrane" 715 "Autonnic" 717 "Yacht Devices" 734 "REAP Systems" 735 "AEM Performance Electronics" 739 "LxNav" 741 "Littelfuse, Inc (formerly Carling Technologies)" 743 "DaeMyung" 744 "Woosung" 748 "ISOTTA IFRA srl" 773 "Clarion US" 776 "HMI Systems" 777 "Ocean Signal" 778 "Seakeeper" 781 "Poly Planar" 785 "Fischer Panda DE" 795 "Broyda Industries" 796 "Canadian Automotive" 797 "Tides Marine" 798 "Lumishore" 799 "Still Water Designs and Audio" 802 "BJ Technologies (Beneteau)" 803 "Gill Sensors" 811 "Blue Water Desalination" 815 "FLIR" 824 "Undheim Systems" 826 "Lewmar" 838 "TeamSurv" 844 "Fell Marine" 847 "Oceanvolt" 862 "Prospec" 868 "Data Panel" 890 "L3 Technologies" 894 "Rhodan Marine Systems" 896 "Nexfour Solutions" 905 "ASA Electronics" 909 "Marines Co (South Korea)" 911 "Nautic-on" 917 "Sentinel" 929 "JL Marine Systems" 930 "Ecotronix" 944 "Zontisa Marine" 951 "EXOR International" 962 "Timbolier Industries" 963 "TJC Micro" 968 "Cox Powertrain" 969 "Blue Seas" 981 "Kobelt Manufacturing" 992 "Blue Ocean IOT" 997 "Xenta Systems" 999 "Signal K" 1004 "Ultraflex" 1008 "Lintest SmartBoat" 1011 "Soundmax" 1020 "Team Italia Marine (Onyx Marine Automation s.r.l)" 1021 "Entratech" 1022 "ITC" 1029 "The Marine Guardian" 1047 "Sonic" 1051 "ProNav" 1053 "Vetus Maxwell INC." 1056 "Lithium Pros" 1059 "Boatrax" 1062 "Marol Co ltd" 1065 "CALYPSO Instruments" 1066 "Spot Zero Water" 1069 "Lithionics Battery" 1070 "Quick-teck Electronics" 1075 "Uniden America" 1083 "Nauticoncept" 1084 "Shadow-Caster LED lighting" 1085 "Wet Sounds" 1088 "E-T-A Circuit Breakers" 1092 "Scheiber" 1100 "Smart Yachts International Limited" 1109 "Dockmate" 1114 "Bobs Machine" 1118 "L3Harris ASV" 1119 "Balmar" 1120 "Elettromedia" 1127 "Electromaax" 1140 "Across Oceans Systems" 1145 "Kiwi Yachting" 1150 "BSB Artificial Intelligence" 1151 "Orca Technologies" 1154 "TBS Electronics" 1158 "Technoton Electroics" 1160 "MG Energy Systems" 1169 "Sea Machine Robotics" 1171 "Vista Manufacturing" 1183 "Zipwake" 1186 "Sailmon" 1192 "Airmoniq Pro Kft" 1194 "Sierra Marine" 1200 "Xinuo Information Technology (Xiamen)" 1218 "Septentrio" 1233 "NKE Marine Electronics" 1238 "SuperTrack Aps" 1239 "Honda Electronics" 1245 "Raritan Engineering" 1249 "Integrated Power Solutions AG" 1260 "Interactive Technologies" 1283 "LTG-Tech" 1299 "Energy Solutions (UK)" 1300 "WATT Fuel Cell" 1302 "Pro Mainer" 1305 "Dragonfly Energy" 1306 "Koden Electronics" 1311 "Humphree" 1316 "Hinkley Yachts" 1317 "Global Marine Management GmbH (GMM)" 1320 "Triskel Marine" 1330 "Warwick Control Technologies" 1331 "Dolphin Charger" 1337 "Barnacle Systems" 1348 "Radian IoT" 1353 "Ocean LED Marine" 1359 "BluNav" 1361 "OVA (Nantong Saiyang Electronics Co., Ltd)" 1368 "RAD Propulsion" 1369 "Electric Yacht" 1372 "Elco Motor Yachts" 1384 "Tecnoseal Foundry S.r.l" 1385 "Pro Charging Systems" 1389 "EVEX" 1398 "Gobius Sensor Technology" 1403 "Arco Marine" 1408 "Lenco Marine" 1413 "Naocontrol" 1417 "Revatek" 1438 "Aeolionics" 1439 "PredictWind" 1440 "Egis Mobile Electric" 1445 "Starboard Yacht Group" 1446 "Roswell Marine" 1451 "ePropulsion (Guangdong ePropulsion Technology Ltd.)" 1452 "Micro-Air" 1453 "Vital Battery" 1458 "Ride Controller" 1460 "Tocaro Blue" 1461 "Vanquish Yachts" 1471 "FT Technologies" 1478 "Alps Alpine" 1481 "E-Force Marine" 1482 "CMC Marine" 1483 "Nanjing Sandemarine Information Technology" 1850 "Teleflex Marine (SeaStar Solutions)" 1851 "Raymarine" 1852 "Navionics" 1853 "Japan Radio" 1854 "Northstar Technologies" 1855 "Furuno" 1856 "Trimble" 1857 "Simrad" 1858 "Litton" 1859 "Kvasar" 1860 "MMP" 1861 "Vector Cantech" 1862 "Yamaha Marine" 1863 "Faria Instruments" ;
VAL_ 2382300928 Industry_Code 0 "Global" 1 "Highway" 2 "Agriculture" 3 "Construction" 4 "Marine Industry" 5 "Industrial" ;
VAL_ 2382300928 Source 0 "Sea Temperature" 1 "Outside Temperature" 2 "Inside Temperature" 3 "Engine Room Temperature" 4 "Main Cabin Temperature" 5 "Live Well Temperature" 6 "Bait Well Temperature" 7 "Refrigeration Temperature" 8 "Heating System Temperature" 9 "Dew Point Temperature" 10 "Apparent Wind Chill Temperature" 11 "Theoretical Wind Chill Temperature" 12 "Heat Index Temperature" 13 "Freezer Temperature" 14 "Exhaust Gas Temperature" 15 "Shaft Seal Temperature" ;
VAL_ 2583627520 Manufacturer_Code 69 "ARKS Enterprises" 78 "FW Murphy/Enovation Controls" 80 "Twin Disc" 85 "Kohler Power Systems" 88 "Hemisphere GPS" 135 "Airmar" 137 "Maretron" 140 "Lowrance" 144 "Mercury Marine" 147 "Nautibus Electronic" 148 "Blue Water Data" 154 "Westerbeke" 157 "ISSPRO" 161 "Offshore Systems (UK)" 163 "Evinrude/BRP" 165 "CPAC Systems" 168 "Xantrex Technology" 169 "Marlin Technologies" 172 "Yanmar Marine" 174 "Volvo Penta" 176 "Carling Technologies Inc. (Moritz Aerospace)" 185 "Beede Instruments" 192 "Floscan Instrument" 193 "Nobeltec" 198 "Mystic Valley Communications" 199 "Actia" 201 "Disenos Y Technologia" 211 "Digital Switching Systems" 215 "Xintex/Atena" 224 "EMMI NETWORK" 228 "ZF" 229 "Garmin" 233 "Yacht Monitoring Solutions" 235 "Sailormade Marine Telemetry/Tetra Technology" 243 "Eride" 257 "Honda Motor" 272 "Groco" 273 "Actisense" 274 "Amphenol LTW Technology" 275 "Navico" 283 "Hamilton Jet" 285 "Sea Recovery" 286 "Coelmo SRL Italy" 295 "BEP Marine" 304 "Empir Bus" 305 "NovAtel" 306 "Sleipner Motor" 307 "MBW Technologies" 315 "ICOM" 328 "Qwerty" 329 "Dief" 341 "Boening Automationstechnologie" 345 "Korean Maritime University" 351 "Thrane and Thrane" 355 "Mastervolt" 356 "Fischer Panda Generators" 358 "Victron Energy" 370 "Rolls Royce Marine" 373 "Electronic Design" 374 "Northern Lights" 378 "Glendinning" 381 "B & G" 384 "Rose Point Navigation Systems" 385 "Johnson Outdoors Marine Electronics Inc Geonav" 394 "Capi 2" 396 "Beyond Measure" 400 "Livorsi Marine" 404 "ComNav" 409 "Chetco" 419 "Fusion Electronics" 421 "Standard Horizon" 422 "True Heading" 426 "Egersund Marine Electronics" 427 "em-trak Marine Electronics" 431 "Tohatsu Co, JP" 437 "Digital Yacht" 438 "Comar Systems Limited" 440 "Cummins" 443 "VDO (aka Continental-Corporation)" 451 "Parker Hannifin aka Village Marine Tech" 459 "Alltek Marine Electronics" 460 "SAN GIORGIO S.E.I.N" 466 "Veethree Electronics & Marine" 470 "SI-TEX Marine Electronics" 471 "Sea Cross Marine" 475 "GME aka Standard Communications" 476 "Humminbird Marine Electronics" 478 "Ocean Sat" 481 "Chetco Digital Instruments" 493 "Watcheye" 499 "Lcj Capteurs" 502 "Attwood Marine" 503 "Naviop S.R.L." 504 "Vesper Marine" 510 "Marinesoft" 513 "Simarine" 517 "NoLand Engineering" 518 "Transas USA" 529 "National Instruments Korea" 530 "National Marine Electronics Association" 532 "Onwa Marine" 540 "Webasto" 571 "Marinecraft (South Korea)" 573 "McMurdo Group aka Orolia" 578 "Advansea" 579 "KVH" 580 "San Jose Technology" 583 "Yacht Control" 586 "Suzuki Motor" 591 "US Coast Guard" 595 "Ship Module aka Customware" 600 "Aquatic AV" 605 "Aventics" 606 "Intellian" 612 "SamwonIT" 614 "Arlt Tecnologies" 637 "Bavaria Yachts" 641 "Diverse Yacht Services" 644 "Wema U.S.A dba KUS" 658 "Shenzhen Jiuzhou Himunication" 688 "Rockford" 699 "Harman International" 704 "JL Audio" 708 "Lars Thrane" 715 "Autonnic" 717 "Yacht Devices" 734 "REAP Systems" 735 "AEM Performance Electronics" 739 "LxNav" 741 "Littelfuse, Inc (formerly Carling Technologies)" 743 "DaeMyung" 744 "Woosung" 748 "ISOTTA IFRA srl" 773 "Clarion US" 776 "HMI Systems" 777 "Ocean Signal" 778 "Seakeeper" 781 "Poly Planar" 785 "Fischer Panda DE" 795 "Broyda Industries" 796 "Canadian Automotive" 797 "Tides Marine" 798 "Lumishore" 799 "Still Water Designs and Audio" 802 "BJ Technologies (Beneteau)" 803 "Gill Sensors" 811 "Blue Water Desalination" 815 "FLIR" 824 "Undheim Systems" 826 "Lewmar" 838 "TeamSurv" 844 "Fell Marine" 847 "Oceanvolt" 862 "Prospec" 868 "Data Panel" 890 "L3 Technologies" 894 "Rhodan Marine Systems" 896 "Nexfour Solutions" 905 "ASA Electronics" 909 "Marines Co (South Korea)" 911 "Nautic-on" 917 "Sentinel" 929 "JL Marine Systems" 930 "Ecotronix" 944 "Zontisa Marine" 951 "EXOR International" 962 "Timbolier Industries" 963 "TJC Micro" 968 "Cox Powertrain" 969 "Blue Seas" 981 "Kobelt Manufacturing" 992 "Blue Ocean IOT" 997 "Xenta Systems" 999 "Signal K" 1004 "Ultraflex" 1008 "Lintest SmartBoat" 1011 "Soundmax" 1020 "Team Italia Marine (Onyx Marine Automation s.r.l)" 1021 "Entratech" 1022 "ITC" 1029 "The Marine Guardian" 1047 "Sonic" 1051 "ProNav" 1053 "Vetus Maxwell INC." 1056 "Lithium Pros" 1059 "Boatrax" 1062 "Marol Co ltd" 1065 "CALYPSO Instruments" 1066 "Spot Zero Water" 1069 "Lithionics Battery" 1070 "Quick-teck Electronics" 1075 "Uniden America" 1083 "Nauticoncept" 1084 "Shadow-Caster LED lighting" 1085 "Wet Sounds" 1088 "E-T-A Circuit Breakers" 1092 "Scheiber" 1100 "Smart Yachts International Limited" 1109 "Dockmate" 1114 "Bobs Machine" 1118 "L3Harris ASV" 1119 "Balmar" 1120 "Elettromedia" 1127 "Electromaax" 1140 "Across Oceans Systems" 1145 "Kiwi Yachting" 1150 "BSB Artificial Intelligence" 1151 "Orca Technologies" 1154 "TBS Electronics" 1158 "Technoton Electroics" 1160 "MG Energy Systems" 1169 "Sea Machine Robotics" 1171 "Vista Manufacturing" 1183 "Zipwake" 1186 "Sailmon" 1192 "Airmoniq Pro Kft" 1194 "Sierra Marine" 1200 "Xinuo Information Technology (Xiamen)" 1218 "Septentrio" 1233 "NKE Marine Electronics" 1238 "SuperTrack Aps" 1239 "Honda Electronics" 1245 "Raritan Engineering" 1249 "Integrated Power Solutions AG" 1260 "Interactive Technologies" 1283 "LTG-Tech" 1299 "Energy Solutions (UK)" 1300 "WATT Fuel Cell" 1302 "Pro Mainer" 1305 "Dragonfly Energy" 1306 "Koden Electronics" 1311 "Humphree" 1316 "Hinkley Yachts" 1317 "Global Marine Management GmbH (GMM)" 1320 "Triskel Marine" 1330 "Warwick Control Technologies" 1331 "Dolphin Charger" 1337 "Barnacle Systems" 1348 "Radian IoT" 1353 "Ocean LED Marine" 1359 "BluNav" 1361 "OVA (Nantong Saiyang Electronics Co., Ltd)" 1368 "RAD Propulsion" 1369 "Electric Yacht" 1372 "Elco Motor Yachts" 1384 "Tecnoseal Foundry S.r.l" 1385 "Pro Charging Systems" 1389 "EVEX" 1398 "Gobius Sensor Technology" 1403 "Arco Marine" 1408 "Lenco Marine" 1413 "Naocontrol" 1417 "Revatek" 1438 "Aeolionics" 1439 "PredictWind" 1440 "Egis Mobile Electric" 1445 "Starboard Yacht Group" 1446 "Roswell Marine" 1451 "ePropulsion (Guangdong ePropulsion Technology Ltd.)" 1452 "Micro-Air" 1453 "Vital Battery" 1458 "Ride Controller" 1460 "Tocaro Blue" 1461 "Vanquish Yachts" 1471 "FT Technologies" 1478 "Alps Alpine" 1481 "E-Force Marine" 1482 "CMC Marine" 1483 "Nanjing Sandemarine Information Technology" 1850 "Teleflex Marine (SeaStar Solutions)" 1851 "Raymarine" 1852 "Navionics" 1853 "Japan Radio" 1854 "Northstar Technologies" 1855 "Furuno" 1856 "Trimble" 1857 "Simrad" 1858 "Litton" 1859 "Kvasar" 1860 "MMP" 1861 "Vector Cantech" 1862 "Yamaha Marine" 1863 "Faria Instruments" ;
VAL_ 2583627520 Industry_Code 0 "Global" 1 "Highway" 2 "Agriculture" 3 "Construction" 4 "Marine Industry" 5 "Industrial" ;
VAL_ 2583627520 Manufacturer_Code 69 "ARKS Enterprises" 78 "FW Murphy/Enovation Controls" 80 "Twin Disc" 85 "Kohler Power Systems" 88 "Hemisphere GPS" 135 "Airmar" 137 "Maretron" 140 "Lowrance" 144 "Mercury Marine" 147 "Nautibus Electronic" 148 "Blue Water Data" 154 "Westerbeke" 157 "ISSPRO" 161 "Offshore Systems (UK)" 163 "Evinrude/BRP" 165 "CPAC Systems" 168 "Xantrex Technology" 169 "Marlin Technologies" 172 "Yanmar Marine" 174 "Volvo Penta" 176 "Carling Technologies Inc. (Moritz Aerospace)" 185 "Beede Instruments" 192 "Floscan Instrument" 193 "Nobeltec" 198 "Mystic Valley Communications" 199 "Actia" 201 "Disenos Y Technologia" 211 "Digital Switching Systems" 215 "Xintex/Atena" 224 "EMMI NETWORK" 228 "ZF" 229 "Garmin" 233 "Yacht Monitoring Solutions" 235 "Sailormade Marine Telemetry/Tetra Technology" 243 "Eride" 257 "Honda Motor" 272 "Groco" 273 "Actisense" 274 "Amphenol LTW Technology" 275 "Navico" 283 "Hamilton Jet" 285 "Sea Recovery" 286 "Coelmo SRL Italy" 295 "BEP Marine" 304 "Empir Bus" 305 "NovAtel" 306 "Sleipner Motor" 307 "MBW Technologies" 315 "ICOM" 328 "Qwerty" 329 "Dief" 341 "Boening Automationstechnologie" 345 "Korean Maritime University" 351 "Thrane and Thrane" 355 "Mastervolt" 356 "Fischer Panda Generators" 358 "Victron Energy" 370 "Rolls Royce Marine" 373 "Electronic Design" 374 "Northern Lights" 378 "Glendinning" 381 "B & G" 384 "Rose Point Navigation Systems" 385 "Johnson Outdoors Marine Electronics Inc Geonav" 394 "Capi 2" 396 "Beyond Measure" 400 "Livorsi Marine" 404 "ComNav" 409 "Chetco" 419 "Fusion Electronics" 421 "Standard Horizon" 422 "True Heading" 426 "Egersund Marine Electronics" 427 "em-trak Marine Electronics" 431 "Tohatsu Co, JP" 437 "Digital Yacht" 438 "Comar Systems Limited" 440 "Cummins" 443 "VDO (aka Continental-Corporation)" 451 "Parker Hannifin aka Village Marine Tech" 459 "Alltek Marine Electronics" 460 "SAN GIORGIO S.E.I.N" 466 "Veethree Electronics & Marine" 470 "SI-TEX Marine Electronics" 471 "Sea Cross Marine" 475 "GME aka Standard Communications" 476 "Humminbird Marine Electronics" 478 "Ocean Sat" 481 "Chetco Digital Instruments" 493 "Watcheye" 499 "Lcj Capteurs" 502 "Attwood Marine" 503 "Naviop S.R.L." 504 "Vesper Marine" 510 "Marinesoft" 513 "Simarine" 517 "NoLand Engineering" 518 "Transas USA" 529 "National Instruments Korea" 530 "National Marine Electronics Association" 532 "Onwa Marine" 540 "Webasto" 571 "Marinecraft (South Korea)" 573 "McMurdo Group aka Orolia" 578 "Advansea" 579 "KVH" 580 "San Jose Technology" 583 "Yacht Control" 586 "Suzuki Motor" 591 "US Coast Guard" 595 "Ship Module aka Customware" 600 "Aquatic AV" 605 "Aventics" 606 "Intellian" 612 "SamwonIT" 614 "Arlt Tecnologies" 637 "Bavaria Yachts" 641 "Diverse Yacht Services" 644 "Wema U.S.A dba KUS" 658 "Shenzhen Jiuzhou Himunication" 688 "Rockford" 699 "Harman International" 704 "JL Audio" 708 "Lars Thrane" 715 "Autonnic" 717 "Yacht Devices" 734 "REAP Systems" 735 "AEM Performance Electronics" 739 "LxNav" 741 "Littelfuse, Inc (formerly Carling Technologies)" 743 "DaeMyung" 744 "Woosung" 748 "ISOTTA IFRA srl" 773 "Clarion US" 776 "HMI Systems" 777 "Ocean Signal" 778 "Seakeeper" 781 "Poly Planar" 785 "Fischer Panda DE" 795 "Broyda Industries" 796 "Canadian Automotive" 797 "Tides Marine" 798 "Lumishore" 799 "Still Water Designs and Audio" 802 "BJ Technologies (Beneteau)" 803 "Gill Sensors" 811 "Blue Water Desalination" 815 "FLIR" 824 "Undheim Systems" 826 "Lewmar" 838 "TeamSurv" 844 "Fell Marine" 847 "Oceanvolt" 862 "Prospec" 868 "Data Panel" 890 "L3 Technologies" 894 "Rhodan Marine Systems" 896 "Nexfour Solutions" 905 "ASA Electronics" 909 "Marines Co (South Korea)" 911 "Nautic-on" 917 "Sentinel" 929 "JL Marine Systems" 930 "Ecotronix" 944 "Zontisa Marine" 951 "EXOR International" 962 "Timbolier Industries" 963 "TJC Micro" 968 "Cox Powertrain" 969 "Blue Seas" 981 "Kobelt Manufacturing" 992 "Blue Ocean IOT" 997 "Xenta Systems" 999 "Signal K" 1004 "Ultraflex" 1008 "Lintest SmartBoat" 1011 "Soundmax" 1020 "Team Italia Marine (Onyx Marine Automation s.r.l)" 1021 "Entratech" 1022 "ITC" 1029 "The Marine Guardian" 1047 "Sonic" 1051 "ProNav" 1053 "Vetus Maxwell INC." 1056 "Lithium Pros" 1059 "Boatrax" 1062 "Marol Co ltd" 1065 "CALYPSO Instruments" 1066 "Spot Zero Water" 1069 "Lithionics Battery" 1070 "Quick-teck Electronics" 1075 "Uniden America" 1083 "Nauticoncept" 1084 "Shadow-Caster LED lighting" 1085 "Wet Sounds" 1088 "E-T-A Circuit Breakers" 1092 "Scheiber" 1100 "Smart Yachts International Limited" 1109 "Dockmate" 1114 "Bobs Machine" 1118 "L3Harris ASV" 1119 "Balmar" 1120 "Elettromedia" 1127 "Electromaax" 1140 "Across Oceans Systems" 1145 "Kiwi Yachting" 1150 "BSB Artificial Intelligence" 1151 "Orca Technologies" 1154 "TBS Electronics" 1158 "Technoton Electroics" 1160 "MG Energy Systems" 1169 "Sea Machine Robotics" 1171 "Vista Manufacturing" 1183 "Zipwake" 1186 "Sailmon" 1192 "Airmoniq Pro Kft" 1194 "Sierra Marine" 1200 "Xinuo Information Technology (Xiamen)" 1218 "Septentrio" 1233 "NKE Marine Electronics" 1238 "SuperTrack Aps" 1239 "Honda Electronics" 1245 "Raritan Engineering" 1249 "Integrated Power Solutions AG" 1260 "Interactive Technologies" 1283 "LTG-Tech" 1299 "Energy Solutions (UK)" 1300 "WATT Fuel Cell" 1302 "Pro Mainer" 1305 "Dragonfly Energy" 1306 "Koden Electronics" 1311 "Humphree" 1316 "Hinkley Yachts" 1317 "Global Marine Management GmbH (GMM)" 1320 "Triskel Marine" 1330 "Warwick Control Technologies" 1331 "Dolphin Charger" 1337 "Barnacle Systems" 1348 "Radian IoT" 1353 "Ocean LED Marine" 1359 "BluNav" 1361 "OVA (Nantong Saiyang Electronics Co., Ltd)" 1368 "RAD Propulsion" 1369 "Electric Yacht" 1372 "Elco Motor Yachts" 1384 "Tecnoseal Foundry S.r.l" 1385 "Pro Charging Systems" 1389 "EVEX" 1398 "Gobius Sensor Technology" 1403 "Arco Marine" 1408 "Lenco Marine" 1413 "Naocontrol" 1417 "Revatek" 1438 "Aeolionics" 1439 "PredictWind" 1440 "Egis Mobile Electric" 1445 "Starboard Yacht Group" 1446 "Roswell Marine" 1451 "ePropulsion (Guangdong ePropulsion Technology Ltd.)" 1452 "Micro-Air" 1453 "Vital Battery" 1458 "Ride Controller" 1460 "Tocaro Blue" 1461 "Vanquish Yachts" 1471 "FT Technologies" 1478 "Alps Alpine" 1481 "E-Force Marine" 1482 "CMC Marine" 1483 "Nanjing Sandemarine Information Technology" 1850 "Teleflex Marine (SeaStar Solutions)" 1851 "Raymarine" 1852 "Navionics" 1853 "Japan Radio" 1854 "Northstar Technologies" 1855 "Furuno" 1856 "Trimble" 1857 "Simrad" 1858 "Litton" 1859 "Kvasar" 1860 "MMP" 1861 "Vector Cantech" 1862 "Yamaha Marine" 1863 "Faria Instruments" ;
VAL_ 2583627520 Industry_Code 0 "Global" 1 "Highway" 2 "Agriculture" 3 "Construction" 4 "Marine Industry" 5 "Industrial" ;
VAL_ 2583627520 Manufacturer_Code 69 "ARKS Enterprises" 78 "FW Murphy/Enovation Controls" 80 "Twin Disc" 85 "Kohler Power Systems" 88 "Hemisphere GPS" 135 "Airmar" 137 "Maretron" 140 "Lowrance" 144 "Mercury Marine" 147 "Nautibus Electronic" 148 "Blue Water Data" 154 "Westerbeke" 157 "ISSPRO" 161 "Offshore Systems (UK)" 163 "Evinrude/BRP" 165 "CPAC Systems" 168 "Xantrex Technology" 169 "Marlin Technologies" 172 "Yanmar Marine" 174 "Volvo Penta" 176 "Carling Technologies Inc. (Moritz Aerospace)" 185 "Beede Instruments" 192 "Floscan Instrument" 193 "Nobeltec" 198 "Mystic Valley Communications" 199 "Actia" 201 "Disenos Y Technologia" 211 "Digital Switching Systems" 215 "Xintex/Atena" 224 "EMMI NETWORK" 228 "ZF" 229 "Garmin" 233 "Yacht Monitoring Solutions" 235 "Sailormade Marine Telemetry/Tetra Technology" 243 "Eride" 257 "Honda Motor" 272 "Groco" 273 "Actisense" 274 "Amphenol LTW Technology" 275 "Navico" 283 "Hamilton Jet" 285 "Sea Recovery" 286 "Coelmo SRL Italy" 295 "BEP Marine" 304 "Empir Bus" 305 "NovAtel" 306 "Sleipner Motor" 307 "MBW Technologies" 315 "ICOM" 328 "Qwerty" 329 "Dief" 341 "Boening Automationstechnologie" 345 "Korean Maritime University" 351 "Thrane and Thrane" 355 "Mastervolt" 356 "Fischer Panda Generators" 358 "Victron Energy" 370 "Rolls Royce Marine" 373 "Electronic Design" 374 "Northern Lights" 378 "Glendinning" 381 "B & G" 384 "Rose Point Navigation Systems" 385 "Johnson Outdoors Marine Electronics Inc Geonav" 394 "Capi 2" 396 "Beyond Measure" 400 "Livorsi Marine" 404 "ComNav" 409 "Chetco" 419 "Fusion Electronics" 421 "Standard Horizon" 422 "True Heading" 426 "Egersund Marine Electronics" 427 "em-trak Marine Electronics" 431 "Tohatsu Co, JP" 437 "Digital Yacht" 438 "Comar Systems Limited" 440 "Cummins" 443 "VDO (aka Continental-Corporation)" 451 "Parker Hannifin aka Village Marine Tech" 459 "Alltek Marine Electronics" 460 "SAN GIORGIO S.E.I.N" 466 "Veethree Electronics & Marine" 470 "SI-TEX Marine Electronics" 471 "Sea Cross Marine" 475 "GME aka Standard Communications" 476 "Humminbird Marine Electronics" 478 "Ocean Sat" 481 "Chetco Digital Instruments" 493 "Watcheye" 499 "Lcj Capteurs" 502 "Attwood Marine" 503 "Naviop S.R.L." 504 "Vesper Marine" 510 "Marinesoft" 513 "Simarine" 517 "NoLand Engineering" 518 "Transas USA" 529 "National Instruments Korea" 530 "National Marine Electronics Association" 532 "Onwa Marine" 540 "Webasto" 571 "Marinecraft (South Korea)" 573 "McMurdo Group aka Orolia" 578 "Advansea" 579 "KVH" 580 "San Jose Technology" 583 "Yacht Control" 586 "Suzuki Motor" 591 "US Coast Guard" 595 "Ship Module aka Customware" 600 "Aquatic AV" 605 "Aventics" 606 "Intellian" 612 "SamwonIT" 614 "Arlt Tecnologies" 637 "Bavaria Yachts" 641 "Diverse Yacht Services" 644 "Wema U.S.A dba KUS" 658 "Shenzhen Jiuzhou Himunication" 688 "Rockford" 699 "Harman International" 704 "JL Audio" 708 "Lars Thrane" 715 "Autonnic" 717 "Yacht Devices" 734 "REAP Systems" 735 "AEM Performance Electronics" 739 "LxNav" 741 "Littelfuse, Inc (formerly Carling Technologies)" 743 "DaeMyung" 744 "Woosung" 748 "ISOTTA IFRA srl" 773 "Clarion US" 776 "HMI Systems" 777 "Ocean Signal" 778 "Seakeeper" 781 "Poly Planar" 785 "Fischer Panda DE" 795 "Broyda Industries" 796 "Canadian Automotive" 797 "Tides Marine" 798 "Lumishore" 799 "Still Water Designs and Audio" 802 "BJ Technologies (Beneteau)" 803 "Gill Sensors" 811 "Blue Water Desalination" 815 "FLIR" 824 "Undheim Systems" 826 "Lewmar" 838 "TeamSurv" 844 "Fell Marine" 847 "Oceanvolt" 862 "Prospec" 868 "Data Panel" 890 "L3 Technologies" 894 "Rhodan Marine Systems" 896 "Nexfour Solutions" 905 "ASA Electronics" 909 "Marines Co (South Korea)" 911 "Nautic-on" 917 "Sentinel" 929 "JL Marine Systems" 930 "Ecotronix" 944 "Zontisa Marine" 951 "EXOR International" 962 "Timbolier Industries" 963 "TJC Micro" 968 "Cox Powertrain" 969 "Blue Seas" 981 "Kobelt Manufacturing" 992 "Blue Ocean IOT" 997 "Xenta Systems" 999 "Signal K" 1004 "Ultraflex" 1008 "Lintest SmartBoat" 1011 "Soundmax" 1020 "Team Italia Marine (Onyx Marine Automation s.r.l)" 1021 "Entratech" 1022 "ITC" 1029 "The Marine Guardian" 1047 "Sonic" 1051 "ProNav" 1053 "Vetus Maxwell INC." 1056 "Lithium Pros" 1059 "Boatrax" 1062 "Marol Co ltd" 1065 "CALYPSO Instruments" 1066 "Spot Zero Water" 1069 "Lithionics Battery" 1070 "Quick-teck Electronics" 1075 "Uniden America" 1083 "Nauticoncept" 1084 "Shadow-Caster LED lighting" 1085 "Wet Sounds" 1088 "E-T-A Circuit Breakers" 1092 "Scheiber" 1100 "Smart Yachts International Limited" 1109 "Dockmate" 1114 "Bobs Machine" 1118 "L3Harris ASV" 1119 "Balmar" 1120 "Elettromedia" 1127 "Electromaax" 1140 "Across Oceans Systems" 1145 "Kiwi Yachting" 1150 "BSB Artificial Intelligence" 1151 "Orca Technologies" 1154 "TBS Electronics" 1158 "Technoton Electroics" 1160 "MG Energy Systems" 1169 "Sea Machine Robotics" 1171 "Vista Manufacturing" 1183 "Zipwake" 1186 "Sailmon" 1192 "Airmoniq Pro Kft" 1194 "Sierra Marine" 1200 "Xinuo Information Technology (Xiamen)" 1218 "Septentrio" 1233 "NKE Marine Electronics" 1238 "SuperTrack Aps" 1239 "Honda Electronics" 1245 "Raritan Engineering" 1249 "Integrated Power Solutions AG" 1260 "Interactive Technologies" 1283 "LTG-Tech" 1299 "Energy Solutions (UK)" 1300 "WATT Fuel Cell" 1302 "Pro Mainer" 1305 "Dragonfly Energy" 1306 "Koden Electronics" 1311 "Humphree" 1316 "Hinkley Yachts" 1317 "Global Marine Management GmbH (GMM)" 1320 "Triskel Marine" 1330 "Warwick Control Technologies" 1331 "Dolphin Charger" 1337 "Barnacle Systems" 1348 "Radian IoT" 1353 "Ocean LED Marine" 1359 "BluNav" 1361 "OVA (Nantong Saiyang Electronics Co., Ltd)" 1368 "RAD Propulsion" 1369 "Electric Yacht" 1372 "Elco Motor Yachts" 1384 "Tecnoseal Foundry S.r.l" 1385 "Pro Charging Systems" 1389 "EVEX" 1398 "Gobius Sensor Technology" 1403 "Arco Marine" 1408 "Lenco Marine" 1413 "Naocontrol" 1417 "Revatek" 1438 "Aeolionics" 1439 "PredictWind" 1440 "Egis Mobile Electric" 1445 "Starboard Yacht Group" 1446 "Roswell Marine" 1451 "ePropulsion (Guangdong ePropulsion Technology Ltd.)" 1452 "Micro-Air" 1453 "Vital Battery" 1458 "Ride Controller" 1460 "Tocaro Blue" 1461 "Vanquish Yachts" 1471 "FT Technologies" 1478 "Alps Alpine" 1481 "E-Force Marine" 1482 "CMC Marine" 1483 "Nanjing Sandemarine Information Technology" 1850 "Teleflex Marine (SeaStar Solutions)" 1851 "Raymarine" 1852 "Navionics" 1853 "Japan Radio" 1854 "Northstar Technologies" 1855 "Furuno" 1856 "Trimble" 1857 "Simrad" 1858 "Litton" 1859 "Kvasar" 1860 "MMP" 1861 "Vector Cantech" 1862 "Yamaha Marine" 1863 "Faria Instruments" ;
VAL_ 2583627520 Industry_Code 0 "Global" 1 "Highway" 2 "Agriculture" 3 "Construction" 4 "Marine Industry" 5 "Industrial" ;
VAL_ 2315192320 Manufacturer_Code 69 "ARKS Enterprises" 78 "FW Murphy/Enovation Controls" 80 "Twin Disc" 85 "Kohler Power Systems" 88 "Hemisphere GPS" 135 "Airmar" 137 "Maretron" 140 "Lowrance" 144 "Mercury Marine" 147 "Nautibus Electronic" 148 "Blue Water Data" 154 "Westerbeke" 157 "ISSPRO" 161 "Offshore Systems (UK)" 163 "Evinrude/BRP" 165 "CPAC Systems" 168 "Xantrex Technology" 169 "Marlin Technologies" 172 "Yanmar Marine" 174 "Volvo Penta" 176 "Carling Technologies Inc. (Moritz Aerospace)" 185 "Beede Instruments" 192 "Floscan Instrument" 193 "Nobeltec" 198 "Mystic Valley Communications" 199 "Actia" 201 "Disenos Y Technologia" 211 "Digital Switching Systems" 215 "Xintex/Atena" 224 "EMMI NETWORK" 228 "ZF" 229 "Garmin" 233 "Yacht Monitoring Solutions" 235 "Sailormade Marine Telemetry/Tetra Technology" 243 "Eride" 257 "Honda Motor" 272 "Groco" 273 "Actisense" 274 "Amphenol LTW Technology" 275 "Navico" 283 "Hamilton Jet" 285 "Sea Recovery" 286 "Coelmo SRL Italy" 295 "BEP Marine" 304 "Empir Bus" 305 "NovAtel" 306 "Sleipner Motor" 307 "MBW Technologies" 315 "ICOM" 328 "Qwerty" 329 "Dief" 341 "Boening Automationstechnologie" 345 "Korean Maritime University" 351 "Thrane and Thrane" 355 "Mastervolt" 356 "Fischer Panda Generators" 358 "Victron Energy" 370 "Rolls Royce Marine" 373 "Electronic Design" 374 "Northern Lights" 378 "Glendinning" 381 "B & G" 384 "Rose Point Navigation Systems" 385 "Johnson Outdoors Marine Electronics Inc Geonav" 394 "Capi 2" 396 "Beyond Measure" 400 "Livorsi Marine" 404 "ComNav" 409 "Chetco" 419 "Fusion Electronics" 421 "Standard Horizon" 422 "True Heading" 426 "Egersund Marine Electronics" 427 "em-trak Marine Electronics" 431 "Tohatsu Co, JP" 437 "Digital Yacht" 438 "Comar Systems Limited" 440 "Cummins" 443 "VDO (aka Continental-Corporation)" 451 "Parker Hannifin aka Village Marine Tech" 459 "Alltek Marine Electronics" 460 "SAN GIORGIO S.E.I.N" 466 "Veethree Electronics & Marine" 470 "SI-TEX Marine Electronics" 471 "Sea Cross Marine" 475 "GME aka Standard Communications" 476 "Humminbird Marine Electronics" 478 "Ocean Sat" 481 "Chetco Digital Instruments" 493 "Watcheye" 499 "Lcj Capteurs" 502 "Attwood Marine" 503 "Naviop S.R.L." 504 "Vesper Marine" 510 "Marinesoft" 513 "Simarine" 517 "NoLand Engineering" 518 "Transas USA" 529 "National Instruments Korea" 530 "National Marine Electronics Association" 532 "Onwa Marine" 540 "Webasto" 571 "Marinecraft (South Korea)" 573 "McMurdo Group aka Orolia" 578 "Advansea" 579 "KVH" 580 "San Jose Technology" 583 "Yacht Control" 586 "Suzuki Motor" 591 "US Coast Guard" 595 "Ship Module aka Customware" 600 "Aquatic AV" 605 "Aventics" 606 "Intellian" 612 "SamwonIT" 614 "Arlt Tecnologies" 637 "Bavaria Yachts" 641 "Diverse Yacht Services" 644 "Wema U.S.A dba KUS" 658 "Shenzhen Jiuzhou Himunication" 688 "Rockford" 699 "Harman International" 704 "JL Audio" 708 "Lars Thrane" 715 "Autonnic" 717 "Yacht Devices" 734 "REAP Systems" 735 "AEM Performance Electronics" 739 "LxNav" 741 "Littelfuse, Inc (formerly Carling Technologies)" 743 "DaeMyung" 744 "Woosung" 748 "ISOTTA IFRA srl" 773 "Clarion US" 776 "HMI Systems" 777 "Ocean Signal" 778 "Seakeeper" 781 "Poly Planar" 785 "Fischer Panda DE" 795 "Broyda Industries" 796 "Canadian Automotive" 797 "Tides Marine" 798 "Lumishore" 799 "Still Water Designs and Audio" 802 "BJ Technologies (Beneteau)" 803 "Gill Sensors" 811 "Blue Water Desalination" 815 "FLIR" 824 "Undheim Systems" 826 "Lewmar" 838 "TeamSurv" 844 "Fell Marine" 847 "Oceanvolt" 862 "Prospec" 868 "Data Panel" 890 "L3 Technologies" 894 "Rhodan Marine Systems" 896 "Nexfour Solutions" 905 "ASA Electronics" 909 "Marines Co (South Korea)" 911 "Nautic-on" 917 "Sentinel" 929 "JL Marine Systems" 930 "Ecotronix" 944 "Zontisa Marine" 951 "EXOR International" 962 "Timbolier Industries" 963 "TJC Micro" 968 "Cox Powertrain" 969 "Blue Seas" 981 "Kobelt Manufacturing" 992 "Blue Ocean IOT" 997 "Xenta Systems" 999 "Signal K" 1004 "Ultraflex" 1008 "Lintest SmartBoat" 1011 "Soundmax" 1020 "Team Italia Marine (Onyx Marine Automation s.r.l)" 1021 "Entratech" 1022 "ITC" 1029 "The Marine Guardian" 1047 "Sonic" 1051 "ProNav" 1053 "Vetus Maxwell INC." 1056 "Lithium Pros" 1059 "Boatrax" 1062 "Marol Co ltd" 1065 "CALYPSO Instruments" 1066 "Spot Zero Water" 1069 "Lithionics Battery" 1070 "Quick-teck Electronics" 1075 "Uniden America" 1083 "Nauticoncept" 1084 "Shadow-Caster LED lighting" 1085 "Wet Sounds" 1088 "E-T-A Circuit Breakers" 1092 "Scheiber" 1100 "Smart Yachts International Limited" 1109 "Dockmate" 1114 "Bobs Machine" 1118 "L3Harris ASV" 1119 "Balmar" 1120 "Elettromedia" 1127 "Electromaax" 1140 "Across Oceans Systems" 1145 "Kiwi Yachting" 1150 "BSB Artificial Intelligence" 1151 "Orca Technologies" 1154 "TBS Electronics" 1158 "Technoton Electroics" 1160 "MG Energy Systems" 1169 "Sea Machine Robotics" 1171 "Vista Manufacturing" 1183 "Zipwake" 1186 "Sailmon" 1192 "Airmoniq Pro Kft" 1194 "Sierra Marine" 1200 "Xinuo Information Technology (Xiamen)" 1218 "Septentrio" 1233 "NKE Marine Electronics" 1238 "SuperTrack Aps" 1239 "Honda Electronics" 1245 "Raritan Engineering" 1249 "Integrated Power Solutions AG" 1260 "Interactive Technologies" 1283 "LTG-Tech" 1299 "Energy Solutions (UK)" 1300 "WATT Fuel Cell" 1302 "Pro Mainer" 1305 "Dragonfly Energy" 1306 "Koden Electronics" 1311 "Humphree" 1316 "Hinkley Yachts" 1317 "Global Marine Management GmbH (GMM)" 1320 "Triskel Marine" 1330 "Warwick Control Technologies" 1331 "Dolphin Charger" 1337 "Barnacle Systems" 1348 "Radian IoT" 1353 "Ocean LED Marine" 1359 "BluNav" 1361 "OVA (Nantong Saiyang Electronics Co., Ltd)" 1368 "RAD Propulsion" 1369 "Electric Yacht" 1372 "Elco Motor Yachts" 1384 "Tecnoseal Foundry S.r.l" 1385 "Pro Charging Systems" 1389 "EVEX" 1398 "Gobius Sensor Technology" 1403 "Arco Marine" 1408 "Lenco Marine" 1413 "Naocontrol" 1417 "Revatek" 1438 "Aeolionics" 1439 "PredictWind" 1440 "Egis Mobile Electric" 1445 "Starboard Yacht Group" 1446 "Roswell Marine" 1451 "ePropulsion (Guangdong ePropulsion Technology Ltd.)" 1452 "Micro-Air" 1453 "Vital Battery" 1458 "Ride Controller" 1460 "Tocaro Blue" 1461 "Vanquish Yachts" 1471 "FT Technologies" 1478 "Alps Alpine" 1481 "E-Force Marine" 1482 "CMC Marine" 1483 "Nanjing Sandemarine Information Technology" 1850 "Teleflex Marine (SeaStar Solutions)" 1851 "Raymarine" 1852 "Navionics" 1853 "Japan Radio" 1854 "Northstar Technologies" 1855 "Furuno" 1856 "Trimble" 1857 "Simrad" 1858 "Litton" 1859 "Kvasar" 1860 "MMP" 1861 "Vector Cantech" 1862 "Yamaha Marine" 1863 "Faria Instruments" ;
VAL_ 2315192320 Industry_Code 0 "Global" 1 "Highway" 2 "Agriculture" 3 "Construction" 4 "Marine Industry" 5 "Industrial" ;
VAL_ 2650736640 Manufacturer_Code 69 "ARKS Enterprises" 78 "FW Murphy/Enovation Controls" 80 "Twin Disc" 85 "Kohler Power Systems" 88 "Hemisphere GPS" 135 "Airmar" 137 "Maretron" 140 "Lowrance" 144 "Mercury Marine" 147 "Nautibus Electronic" 148 "Blue Water Data" 154 "Westerbeke" 157 "ISSPRO" 161 "Offshore Systems (UK)" 163 "Evinrude/BRP" 165 "CPAC Systems" 168 "Xantrex Technology" 169 "Marlin Technologies" 172 "Yanmar Marine" 174 "Volvo Penta" 176 "Carling Technologies Inc. (Moritz Aerospace)" 185 "Beede Instruments" 192 "Floscan Instrument" 193 "Nobeltec" 198 "Mystic Valley Communications" 199 "Actia" 201 "Disenos Y Technologia" 211 "Digital Switching Systems" 215 "Xintex/Atena" 224 "EMMI NETWORK" 228 "ZF" 229 "Garmin" 233 "Yacht Monitoring Solutions" 235 "Sailormade Marine Telemetry/Tetra Technology" 243 "Eride" 257 "Honda Motor" 272 "Groco" 273 "Actisense" 274 "Amphenol LTW Technology" 275 "Navico" 283 "Hamilton Jet" 285 "Sea Recovery" 286 "Coelmo SRL Italy" 295 "BEP Marine" 304 "Empir Bus" 305 "NovAtel" 306 "Sleipner Motor" 307 "MBW Technologies" 315 "ICOM" 328 "Qwerty" 329 "Dief" 341 "Boening Automationstechnologie" 345 "Korean Maritime University" 351 "Thrane and Thrane" 355 "Mastervolt" 356 "Fischer Panda Generators" 358 "Victron Energy" 370 "Rolls Royce Marine" 373 "Electronic Design" 374 "Northern Lights" 378 "Glendinning" 381 "B & G" 384 "Rose Point Navigation Systems" 385 "Johnson Outdoors Marine Electronics Inc Geonav" 394 "Capi 2" 396 "Beyond Measure" 400 "Livorsi Marine" 404 "ComNav" 409 "Chetco" 419 "Fusion Electronics" 421 "Standard Horizon" 422 "True Heading" 426 "Egersund Marine Electronics" 427 "em-trak Marine Electronics" 431 "Tohatsu Co, JP" 437 "Digital Yacht" 438 "Comar Systems Limited" 440 "Cummins" 443 "VDO (aka Continental-Corporation)" 451 "Parker Hannifin aka Village Marine Tech" 459 "Alltek Marine Electronics" 460 "SAN GIORGIO S.E.I.N" 466 "Veethree Electronics & Marine" 470 "SI-TEX Marine Electronics" 471 "Sea Cross Marine" 475 "GME aka Standard Communications" 476 "Humminbird Marine Electronics" 478 "Ocean Sat" 481 "Chetco Digital Instruments" 493 "Watcheye" 499 "Lcj Capteurs" 502 "Attwood Marine" 503 "Naviop S.R.L." 504 "Vesper Marine" 510 "Marinesoft" 513 "Simarine" 517 "NoLand Engineering" 518 "Transas USA" 529 "National Instruments Korea" 530 "National Marine Electronics Association" 532 "Onwa Marine" 540 "Webasto" 571 "Marinecraft (South Korea)" 573 "McMurdo Group aka Orolia" 578 "Advansea" 579 "KVH" 580 "San Jose Technology" 583 "Yacht Control" 586 "Suzuki Motor" 591 "US Coast Guard" 595 "Ship Module aka Customware" 600 "Aquatic AV" 605 "Aventics" 606 "Intellian" 612 "SamwonIT" 614 "Arlt Tecnologies" 637 "Bavaria Yachts" 641 "Diverse Yacht Services" 644 "Wema U.S.A dba KUS" 658 "Shenzhen Jiuzhou Himunication" 688 "Rockford" 699 "Harman International" 704 "JL Audio" 708 "Lars Thrane" 715 "Autonnic" 717 "Yacht Devices" 734 "REAP Systems" 735 "AEM Performance Electronics" 739 "LxNav" 741 "Littelfuse, Inc (formerly Carling Technologies)" 743 "DaeMyung" 744 "Woosung" 748 "ISOTTA IFRA srl" 773 "Clarion US" 776 "HMI Systems" 777 "Ocean Signal" 778 "Seakeeper" 781 "Poly Planar" 785 "Fischer Panda DE" 795 "Broyda Industries" 796 "Canadian Automotive" 797 "Tides Marine" 798 "Lumishore" 799 "Still Water Designs and Audio" 802 "BJ Technologies (Beneteau)" 803 "Gill Sensors" 811 "Blue Water Desalination" 815 "FLIR" 824 "Undheim Systems" 826 "Lewmar" 838 "TeamSurv" 844 "Fell Marine" 847 "Oceanvolt" 862 "Prospec" 868 "Data Panel" 890 "L3 Technologies" 894 "Rhodan Marine Systems" 896 "Nexfour Solutions" 905 "ASA Electronics" 909 "Marines Co (South Korea)" 911 "Nautic-on" 917 "Sentinel" 929 "JL Marine Systems" 930 "Ecotronix" 944 "Zontisa Marine" 951 "EXOR International" 962 "Timbolier Industries" 963 "TJC Micro" 968 "Cox Powertrain" 969 "Blue Seas" 981 "Kobelt Manufacturing" 992 "Blue Ocean IOT" 997 "Xenta Systems" 999 "Signal K" 1004 "Ultraflex" 1008 "Lintest SmartBoat" 1011 "Soundmax" 1020 "Team Italia Marine (Onyx Marine Automation s.r.l)" 1021 "Entratech" 1022 "ITC" 1029 "The Marine Guardian" 1047 "Sonic" 1051 "ProNav" 1053 "Vetus Maxwell INC." 1056 "Lithium Pros" 1059 "Boatrax" 1062 "Marol Co ltd" 1065 "CALYPSO Instruments" 1066 "Spot Zero Water" 1069 "Lithionics Battery" 1070 "Quick-teck Electronics" 1075 "Uniden America" 1083 "Nauticoncept" 1084 "Shadow-Caster LED lighting" 1085 "Wet Sounds" 1088 "E-T-A Circuit Breakers" 1092 "Scheiber" 1100 "Smart Yachts International Limited" 1109 "Dockmate" 1114 "Bobs Machine" 1118 "L3Harris ASV" 1119 "Balmar" 1120 "Elettromedia" 1127 "Electromaax" 1140 "Across Oceans Systems" 1145 "Kiwi Yachting" 1150 "BSB Artificial Intelligence" 1151 "Orca Technologies" 1154 "TBS Electronics" 1158 "Technoton Electroics" 1160 "MG Energy Systems" 1169 "Sea Machine Robotics" 1171 "Vista Manufacturing" 1183 "Zipwake" 1186 "Sailmon" 1192 "Airmoniq Pro Kft" 1194 "Sierra Marine" 1200 "Xinuo Information Technology (Xiamen)" 1218 "Septentrio" 1233 "NKE Marine Electronics" 1238 "SuperTrack Aps" 1239 "Honda Electronics" 1245 "Raritan Engineering" 1249 "Integrated Power Solutions AG" 1260 "Interactive Technologies" 1283 "LTG-Tech" 1299 "Energy Solutions (UK)" 1300 "WATT Fuel Cell" 1302 "Pro Mainer" 1305 "Dragonfly Energy" 1306 "Koden Electronics" 1311 "Humphree" 1316 "Hinkley Yachts" 1317 "Global Marine Management GmbH (GMM)" 1320 "Triskel Marine" 1330 "Warwick Control Technologies" 1331 "Dolphin Charger" 1337 "Barnacle Systems" 1348 "Radian IoT" 1353 "Ocean LED Marine" 1359 "BluNav" 1361 "OVA (Nantong Saiyang Electronics Co., Ltd)" 1368 "RAD Propulsion" 1369 "Electric Yacht" 1372 "Elco Motor Yachts" 1384 "Tecnoseal Foundry S.r.l" 1385 "Pro Charging Systems" 1389 "EVEX" 1398 "Gobius Sensor Technology" 1403 "Arco Marine" 1408 "Lenco Marine" 1413 "Naocontrol" 1417 "Revatek" 1438 "Aeolionics" 1439 "PredictWind" 1440 "Egis Mobile Electric" 1445 "Starboard Yacht Group" 1446 "Roswell Marine" 1451 "ePropulsion (Guangdong ePropulsion Technology Ltd.)" 1452 "Micro-Air" 1453 "Vital Battery" 1458 "Ride Controller" 1460 "Tocaro Blue" 1461 "Vanquish Yachts" 1471 "FT Technologies" 1478 "Alps Alpine" 1481 "E-Force Marine" 1482 "CMC Marine" 1483 "Nanjing Sandemarine Information Technology" 1850 "Teleflex Marine (SeaStar Solutions)" 1851 "Raymarine" 1852 "Navionics" 1853 "Japan Radio" 1854 "Northstar Technologies" 1855 "Furuno" 1856 "Trimble" 1857 "Simrad" 1858 "Litton" 1859 "Kvasar" 1860 "MMP" 1861 "Vector Cantech" 1862 "Yamaha Marine" 1863 "Faria Instruments" ;
VAL_ 2650736640 Industry_Code 0 "Global" 1 "Highway" 2 "Agriculture" 3 "Construction" 4 "Marine Industry" 5 "Industrial" ;
VAL_ 2650736640 Manufacturer_Code 69 "ARKS Enterprises" 78 "FW Murphy/Enovation Controls" 80 "Twin Disc" 85 "Kohler Power Systems" 88 "Hemisphere GPS" 135 "Airmar" 137 "Maretron" 140 "Lowrance" 144 "Mercury Marine" 147 "Nautibus Electronic" 148 "Blue Water Data" 154 "Westerbeke" 157 "ISSPRO" 161 "Offshore Systems (UK)" 163 "Evinrude/BRP" 165 "CPAC Systems" 168 "Xantrex Technology" 169 "Marlin Technologies" 172 "Yanmar Marine" 174 "Volvo Penta" 176 "Carling Technologies Inc. (Moritz Aerospace)" 185 "Beede Instruments" 192 "Floscan Instrument" 193 "Nobeltec" 198 "Mystic Valley Communications" 199 "Actia" 201 "Disenos Y Technologia" 211 "Digital Switching Systems" 215 "Xintex/Atena" 224 "EMMI NETWORK" 228 "ZF" 229 "Garmin" 233 "Yacht Monitoring Solutions" 235 "Sailormade Marine Telemetry/Tetra Technology" 243 "Eride" 257 "Honda Motor" 272 "Groco" 273 "Actisense" 274 "Amphenol LTW Technology" 275 "Navico" 283 "Hamilton Jet" 285 "Sea Recovery" 286 "Coelmo SRL Italy" 295 "BEP Marine" 304 "Empir Bus" 305 "NovAtel" 306 "Sleipner Motor" 307 "MBW Technologies" 315 "ICOM" 328 "Qwerty" 329 "Dief" 341 "Boening Automationstechnologie" 345 "Korean Maritime University" 351 "Thrane and Thrane" 355 "Mastervolt" 356 "Fischer Panda Generators" 358 "Victron Energy" 370 "Rolls Royce Marine" 373 "Electronic Design" 374 "Northern Lights" 378 "Glendinning" 381 "B & G" 384 "Rose Point Navigation Systems" 385 "Johnson Outdoors Marine Electronics Inc Geonav" 394 "Capi 2" 396 "Beyond Measure" 400 "Livorsi Marine" 404 "ComNav" 409 "Chetco" 419 "Fusion Electronics" 421 "Standard Horizon" 422 "True Heading" 426 "Egersund Marine Electronics" 427 "em-trak Marine Electronics" 431 "Tohatsu Co, JP" 437 "Digital Yacht" 438 "Comar Systems Limited" 440 "Cummins" 443 "VDO (aka Continental-Corporation)" 451 "Parker Hannifin aka Village Marine Tech" 459 "Alltek Marine Electronics" 460 "SAN GIORGIO S.E.I.N" 466 "Veethree Electronics & Marine" 470 "SI-TEX Marine Electronics" 471 "Sea Cross Marine" 475 "GME aka Standard Communications" 476 "Humminbird Marine Electronics" 478 "Ocean Sat" 481 "Chetco Digital Instruments" 493 "Watcheye" 499 "Lcj Capteurs" 502 "Attwood Marine" 503 "Naviop S.R.L." 504 "Vesper Marine" 510 "Marinesoft" 513 "Simarine" 517 "NoLand Engineering" 518 "Transas USA" 529 "National Instruments Korea" 530 "National Marine Electronics Association" 532 "Onwa Marine" 540 "Webasto" 571 "Marinecraft (South Korea)" 573 "McMurdo Group aka Orolia" 578 "Advansea" 579 "KVH" 580 "San Jose Technology" 583 "Yacht Control" 586 "Suzuki Motor" 591 "US Coast Guard" 595 "Ship Module aka Customware" 600 "Aquatic AV" 605 "Aventics" 606 "Intellian" 612 "SamwonIT" 614 "Arlt Tecnologies" 637 "Bavaria Yachts" 641 "Diverse Yacht Services" 644 "Wema U.S.A dba KUS" 658 "Shenzhen Jiuzhou Himunication" 688 "Rockford" 699 "Harman International" 704 "JL Audio" 708 "Lars Thrane" 715 "Autonnic" 717 "Yacht Devices" 734 "REAP Systems" 735 "AEM Performance Electronics" 739 "LxNav" 741 "Littelfuse, Inc (formerly Carling Technologies)" 743 "DaeMyung" 744 "Woosung" 748 "ISOTTA IFRA srl" 773 "Clarion US" 776 "HMI Systems" 777 "Ocean Signal" 778 "Seakeeper" 781 "Poly Planar" 785 "Fischer Panda DE" 795 "Broyda Industries" 796 "Canadian Automotive" 797 "Tides Marine" 798 "Lumishore" 799 "Still Water Designs and Audio" 802 "BJ Technologies (Beneteau)" 803 "Gill Sensors" 811 "Blue Water Desalination" 815 "FLIR" 824 "Undheim Systems" 826 "Lewmar" 838 "TeamSurv" 844 "Fell Marine" 847 "Oceanvolt" 862 "Prospec" 868 "Data Panel" 890 "L3 Technologies" 894 "Rhodan Marine Systems" 896 "Nexfour Solutions" 905 "ASA Electronics" 909 "Marines Co (South Korea)" 911 "Nautic-on" 917 "Sentinel" 929 "JL Marine Systems" 930 "Ecotronix" 944 "Zontisa Marine" 951 "EXOR International" 962 "Timbolier Industries" 963 "TJC Micro" 968 "Cox Powertrain" 969 "Blue Seas" 981 "Kobelt Manufacturing" 992 "Blue Ocean IOT" 997 "Xenta Systems" 999 "Signal K" 1004 "Ultraflex" 1008 "Lintest SmartBoat" 1011 "Soundmax" 1020 "Team Italia Marine (Onyx Marine Automation s.r.l)" 1021 "Entratech" 1022 "ITC" 1029 "The Marine Guardian" 1047 "Sonic" 1051 "ProNav" 1053 "Vetus Maxwell INC." 1056 "Lithium Pros" 1059 "Boatrax" 1062 "Marol Co ltd" 1065 "CALYPSO Instruments" 1066 "Spot Zero Water" 1069 "Lithionics Battery" 1070 "Quick-teck Electronics" 1075 "Uniden America" 1083 "Nauticoncept" 1084 "Shadow-Caster LED lighting" 1085 "Wet Sounds" 1088 "E-T-A Circuit Breakers" 1092 "Scheiber" 1100 "Smart Yachts International Limited" 1109 "Dockmate" 1114 "Bobs Machine" 1118 "L3Harris ASV" 1119 "Balmar" 1120 "Elettromedia" 1127 "Electromaax" 1140 "Across Oceans Systems" 1145 "Kiwi Yachting" 1150 "BSB Artificial Intelligence" 1151 "Orca Technologies" 1154 "TBS Electronics" 1158 "Technoton Electroics" 1160 "MG Energy Systems" 1169 "Sea Machine Robotics" 1171 "Vista Manufacturing" 1183 "Zipwake" 1186 "Sailmon" 1192 "Airmoniq Pro Kft" 1194 "Sierra Marine" 1200 "Xinuo Information Technology (Xiamen)" 1218 "Septentrio" 1233 "NKE Marine Electronics" 1238 "SuperTrack Aps" 1239 "Honda Electronics" 1245 "Raritan Engineering" 1249 "Integrated Power Solutions AG" 1260 "Interactive Technologies" 1283 "LTG-Tech" 1299 "Energy Solutions (UK)" 1300 "WATT Fuel Cell" 1302 "Pro Mainer" 1305 "Dragonfly Energy" 1306 "Koden Electronics" 1311 "Humphree" 1316 "Hinkley Yachts" 1317 "Global Marine Management GmbH (GMM)" 1320 "Triskel Marine" 1330 "Warwick Control Technologies" 1331 "Dolphin Charger" 1337 "Barnacle Systems" 1348 "Radian IoT" 1353 "Ocean LED Marine" 1359 "BluNav" 1361 "OVA (Nantong Saiyang Electronics Co., Ltd)" 1368 "RAD Propulsion" 1369 "Electric Yacht" 1372 "Elco Motor Yachts" 1384 "Tecnoseal Foundry S.r.l" 1385 "Pro Charging Systems" 1389 "EVEX" 1398 "Gobius Sensor Technology" 1403 "Arco Marine" 1408 "Lenco Marine" 1413 "Naocontrol" 1417 "Revatek" 1438 "Aeolionics" 1439 "PredictWind" 1440 "Egis Mobile Electric" 1445 "Starboard Yacht Group" 1446 "Roswell Marine" 1451 "ePropulsion (Guangdong ePropulsion Technology Ltd.)" 1452 "Micro-Air" 1453 "Vital Battery" 1458 "Ride Controller" 1460 "Tocaro Blue" 1461 "Vanquish Yachts" 1471 "FT Technologies" 1478 "Alps Alpine" 1481 "E-Force Marine" 1482 "CMC Marine" 1483 "Nanjing Sandemarine Information Technology" 1850 "Teleflex Marine (SeaStar Solutions)" 1851 "Raymarine" 1852 "Navionics" 1853 "Japan Radio" 1854 "Northstar Technologies" 1855 "Furuno" 1856 "Trimble" 1857 "Simrad" 1858 "Litton" 1859 "Kvasar" 1860 "MMP" 1861 "Vector Cantech" 1862 "Yamaha Marine" 1863 "Faria Instruments" ;
VAL_ 2650736640 Industry_Code 0 "Global" 1 "Highway" 2 "Agriculture" 3 "Construction" 4 "Marine Industry" 5 "Industrial" ;
VAL_ 2583628032 Manufacturer_Code 69 "ARKS Enterprises" 78 "FW Murphy/Enovation Controls" 80 "Twin Disc" 85 "Kohler Power Systems" 88 "Hemisphere GPS" 135 "Airmar" 137 "Maretron" 140 "Lowrance" 144 "Mercury Marine" 147 "Nautibus Electronic" 148 "Blue Water Data" 154 "Westerbeke" 157 "ISSPRO" 161 "Offshore Systems (UK)" 163 "Evinrude/BRP" 165 "CPAC Systems" 168 "Xantrex Technology" 169 "Marlin Technologies" 172 "Yanmar Marine" 174 "Volvo Penta" 176 "Carling Technologies Inc. (Moritz Aerospace)" 185 "Beede Instruments" 192 "Floscan Instrument" 193 "Nobeltec" 198 "Mystic Valley Communications" 199 "Actia" 201 "Disenos Y Technologia" 211 "Digital Switching Systems" 215 "Xintex/Atena" 224 "EMMI NETWORK" 228 "ZF" 229 "Garmin" 233 "Yacht Monitoring Solutions" 235 "Sailormade Marine Telemetry/Tetra Technology" 243 "Eride" 257 "Honda Motor" 272 "Groco" 273 "Actisense" 274 "Amphenol LTW Technology" 275 "Navico" 283 "Hamilton Jet" 285 "Sea Recovery" 286 "Coelmo SRL Italy" 295 "BEP Marine" 304 "Empir Bus" 305 "NovAtel" 306 "Sleipner Motor" 307 "MBW Technologies" 315 "ICOM" 328 "Qwerty" 329 "Dief" 341 "Boening Automationstechnologie" 345 "Korean Maritime University" 351 "Thrane and Thrane" 355 "Mastervolt" 356 "Fischer Panda Generators" 358 "Victron Energy" 370 "Rolls Royce Marine" 373 "Electronic Design" 374 "Northern Lights" 378 "Glendinning" 381 "B & G" 384 "Rose Point Navigation Systems" 385 "Johnson Outdoors Marine Electronics Inc Geonav" 394 "Capi 2" 396 "Beyond Measure" 400 "Livorsi Marine" 404 "ComNav" 409 "Chetco" 419 "Fusion Electronics" 421 "Standard Horizon" 422 "True Heading" 426 "Egersund Marine Electronics" 427 "em-trak Marine Electronics" 431 "Tohatsu Co, JP" 437 "Digital Yacht" 438 "Comar Systems Limited" 440 "Cummins" 443 "VDO (aka Continental-Corporation)" 451 "Parker Hannifin aka Village Marine Tech" 459 "Alltek Marine Electronics" 460 "SAN GIORGIO S.E.I.N" 466 "Veethree Electronics & Marine" 470 "SI-TEX Marine Electronics" 471 "Sea Cross Marine" 475 "GME aka Standard Communications" 476 "Humminbird Marine Electronics" 478 "Ocean Sat" 481 "Chetco Digital Instruments" 493 "Watcheye" 499 "Lcj Capteurs" 502 "Attwood Marine" 503 "Naviop S.R.L." 504 "Vesper Marine" 510 "Marinesoft" 513 "Simarine" 517 "NoLand Engineering" 518 "Transas USA" 529 "National Instruments Korea" 530 "National Marine Electronics Association" 532 "Onwa Marine" 540 "Webasto" 571 "Marinecraft (South Korea)" 573 "McMurdo Group aka Orolia" 578 "Advansea" 579 "KVH" 580 "San Jose Technology" 583 "Yacht Control" 586 "Suzuki Motor" 591 "US Coast Guard" 595 "Ship Module aka Customware" 600 "Aquatic AV" 605 "Aventics" 606 "Intellian" 612 "SamwonIT" 614 "Arlt Tecnologies" 637 "Bavaria Yachts" 641 "Diverse Yacht Services" 644 "Wema U.S.A dba KUS" 658 "Shenzhen Jiuzhou Himunication" 688 "Rockford" 699 "Harman International" 704 "JL Audio" 708 "Lars Thrane" 715 "Autonnic" 717 "Yacht Devices" 734 "REAP Systems" 735 "AEM Performance Electronics" 739 "LxNav" 741 "Littelfuse, Inc (formerly Carling Technologies)" 743 "DaeMyung" 744 "Woosung" 748 "ISOTTA IFRA srl" 773 "Clarion US" 776 "HMI Systems" 777 "Ocean Signal" 778 "Seakeeper" 781 "Poly Planar" 785 "Fischer Panda DE" 795 "Broyda Industries" 796 "Canadian Automotive" 797 "Tides Marine" 798 "Lumishore" 799 "Still Water Designs and Audio" 802 "BJ Technologies (Beneteau)" 803 "Gill Sensors" 811 "Blue Water Desalination" 815 "FLIR" 824 "Undheim Systems" 826 "Lewmar" 838 "TeamSurv" 844 "Fell Marine" 847 "Oceanvolt" 862 "Prospec" 868 "Data Panel" 890 "L3 Technologies" 894 "Rhodan Marine Systems" 896 "Nexfour Solutions" 905 "ASA Electronics" 909 "Marines Co (South Korea)" 911 "Nautic-on" 917 "Sentinel" 929 "JL Marine Systems" 930 "Ecotronix" 944 "Zontisa Marine" 951 "EXOR International" 962 "Timbolier Industries" 963 "TJC Micro" 968 "Cox Powertrain" 969 "Blue Seas" 981 "Kobelt Manufacturing" 992 "Blue Ocean IOT" 997 "Xenta Systems" 999 "Signal K" 1004 "Ultraflex" 1008 "Lintest SmartBoat" 1011 "Soundmax" 1020 "Team Italia Marine (Onyx Marine Automation s.r.l)" 1021 "Entratech" 1022 "ITC" 1029 "The Marine Guardian" 1047 "Sonic" 1051 "ProNav" 1053 "Vetus Maxwell INC." 1056 "Lithium Pros" 1059 "Boatrax" 1062 "Marol Co ltd" 1065 "CALYPSO Instruments" 1066 "Spot Zero Water" 1069 "Lithionics Battery" 1070 "Quick-teck Electronics" 1075 "Uniden America" 1083 "Nauticoncept" 1084 "Shadow-Caster LED lighting" 1085 "Wet Sounds" 1088 "E-T-A Circuit Breakers" 1092 "Scheiber" 1100 "Smart Yachts International Limited" 1109 "Dockmate" 1114 "Bobs Machine" 1118 "L3Harris ASV" 1119 "Balmar" 1120 "Elettromedia" 1127 "Electromaax" 1140 "Across Oceans Systems" 1145 "Kiwi Yachting" 1150 "BSB Artificial Intelligence" 1151 "Orca Technologies" 1154 "TBS Electronics" 1158 "Technoton Electroics" 1160 "MG Energy Systems" 1169 "Sea Machine Robotics" 1171 "Vista Manufacturing" 1183 "Zipwake" 1186 "Sailmon" 1192 "Airmoniq Pro Kft" 1194 "Sierra Marine" 1200 "Xinuo Information Technology (Xiamen)" 1218 "Septentrio" 1233 "NKE Marine Electronics" 1238 "SuperTrack Aps" 1239 "Honda Electronics" 1245 "Raritan Engineering" 1249 "Integrated Power Solutions AG" 1260 "Interactive Technologies" 1283 "LTG-Tech" 1299 "Energy Solutions (UK)" 1300 "WATT Fuel Cell" 1302 "Pro Mainer" 1305 "Dragonfly Energy" 1306 "Koden Electronics" 1311 "Humphree" 1316 "Hinkley Yachts" 1317 "Global Marine Management GmbH (GMM)" 1320 "Triskel Marine" 1330 "Warwick Control Technologies" 1331 "Dolphin Charger" 1337 "Barnacle Systems" 1348 "Radian IoT" 1353 "Ocean LED Marine" 1359 "BluNav" 1361 "OVA (Nantong Saiyang Electronics Co., Ltd)" 1368 "RAD Propulsion" 1369 "Electric Yacht" 1372 "Elco Motor Yachts" 1384 "Tecnoseal Foundry S.r.l" 1385 "Pro Charging Systems" 1389 "EVEX" 1398 "Gobius Sensor Technology" 1403 "Arco Marine" 1408 "Lenco Marine" 1413 "Naocontrol" 1417 "Revatek" 1438 "Aeolionics" 1439 "PredictWind" 1440 "Egis Mobile Electric" 1445 "Starboard Yacht Group" 1446 "Roswell Marine" 1451 "ePropulsion (Guangdong ePropulsion Technology Ltd.)" 1452 "Micro-Air" 1453 "Vital Battery" 1458 "Ride Controller" 1460 "Tocaro Blue" 1461 "Vanquish Yachts" 1471 "FT Technologies" 1478 "Alps Alpine" 1481 "E-Force Marine" 1482 "CMC Marine" 1483 "Nanjing Sandemarine Information Technology" 1850 "Teleflex Marine (SeaStar Solutions)" 1851 "Raymarine" 1852 "Navionics" 1853 "Japan Radio" 1854 "Northstar Technologies" 1855 "Furuno" 1856 "Trimble" 1857 "Simrad" 1858 "Litton" 1859 "Kvasar" 1860 "MMP" 1861 "Vector Cantech" 1862 "Yamaha Marine" 1863 "Faria Instruments" ;
VAL_ 2583628032 Industry_Code 0 "Global" 1 "Highway" 2 "Agriculture" 3 "Construction" 4 "Marine Industry" 5 "Industrial" ;
VAL_ 2583628032 Manufacturer_Code 69 "ARKS Enterprises" 78 "FW Murphy/Enovation Controls" 80 "Twin Disc" 85 "Kohler Power Systems" 88 "Hemisphere GPS" 135 "Airmar" 137 "Maretron" 140 "Lowrance" 144 "Mercury Marine" 147 "Nautibus Electronic" 148 "Blue Water Data" 154 "Westerbeke" 157 "ISSPRO" 161 "Offshore Systems (UK)" 163 "Evinrude/BRP" 165 "CPAC Systems" 168 "Xantrex Technology" 169 "Marlin Technologies" 172 "Yanmar Marine" 174 "Volvo Penta" 176 "Carling Technologies Inc. (Moritz Aerospace)" 185 "Beede Instruments" 192 "Floscan Instrument" 193 "Nobeltec" 198 "Mystic Valley Communications" 199 "Actia" 201 "Disenos Y Technologia" 211 "Digital Switching Systems" 215 "Xintex/Atena" 224 "EMMI NETWORK" 228 "ZF" 229 "Garmin" 233 "Yacht Monitoring Solutions" 235 "Sailormade Marine Telemetry/Tetra Technology" 243 "Eride" 257 "Honda Motor" 272 "Groco" 273 "Actisense" 274 "Amphenol LTW Technology" 275 "Navico" 283 "Hamilton Jet" 285 "Sea Recovery" 286 "Coelmo SRL Italy" 295 "BEP Marine" 304 "Empir Bus" 305 "NovAtel" 306 "Sleipner Motor" 307 "MBW Technologies" 315 "ICOM" 328 "Qwerty" 329 "Dief" 341 "Boening Automationstechnologie" 345 "Korean Maritime University" 351 "Thrane and Thrane" 355 "Mastervolt" 356 "Fischer Panda Generators" 358 "Victron Energy" 370 "Rolls Royce Marine" 373 "Electronic Design" 374 "Northern Lights" 378 "Glendinning" 381 "B & G" 384 "Rose Point Navigation Systems" 385 "Johnson Outdoors Marine Electronics Inc Geonav" 394 "Capi 2" 396 "Beyond Measure" 400 "Livorsi Marine" 404 "ComNav" 409 "Chetco" 419 "Fusion Electronics" 421 "Standard Horizon" 422 "True Heading" 426 "Egersund Marine Electronics" 427 "em-trak Marine Electronics" 431 "Tohatsu Co, JP" 437 "Digital Yacht" 438 "Comar Systems Limited" 440 "Cummins" 443 "VDO (aka Continental-Corporation)" 451 "Parker Hannifin aka Village Marine Tech" 459 "Alltek Marine Electronics" 460 "SAN GIORGIO S.E.I.N" 466 "Veethree Electronics & Marine" 470 "SI-TEX Marine Electronics" 471 "Sea Cross Marine" 475 "GME aka Standard Communications" 476 "Humminbird Marine Electronics" 478 "Ocean Sat" 481 "Chetco Digital Instruments" 493 "Watcheye" 499 "Lcj Capteurs" 502 "Attwood Marine" 503 "Naviop S.R.L." 504 "Vesper Marine" 510 "Marinesoft" 513 "Simarine" 517 "NoLand Engineering" 518 "Transas USA" 529 "National Instruments Korea" 530 "National Marine Electronics Association" 532 "Onwa Marine" 540 "Webasto" 571 "Marinecraft (South Korea)" 573 "McMurdo Group aka Orolia" 578 "Advansea" 579 "KVH" 580 "San Jose Technology" 583 "Yacht Control" 586 "Suzuki Motor" 591 "US Coast Guard" 595 "Ship Module aka Customware" 600 "Aquatic AV" 605 "Aventics" 606 "Intellian" 612 "SamwonIT" 614 "Arlt Tecnologies" 637 "Bavaria Yachts" 641 "Diverse Yacht Services" 644 "Wema U.S.A dba KUS" 658 "Shenzhen Jiuzhou Himunication" 688 "Rockford" 699 "Harman International" 704 "JL Audio" 708 "Lars Thrane" 715 "Autonnic" 717 "Yacht Devices" 734 "REAP Systems" 735 "AEM Performance Electronics" 739 "LxNav" 741 "Littelfuse, Inc (formerly Carling Technologies)" 743 "DaeMyung" 744 "Woosung" 748 "ISOTTA IFRA srl" 773 "Clarion US" 776 "HMI Systems" 777 "Ocean Signal" 778 "Seakeeper" 781 "Poly Planar" 785 "Fischer Panda DE" 795 "Broyda Industries" 796 "Canadian Automotive" 797 "Tides Marine" 798 "Lumishore" 799 "Still Water Designs and Audio" 802 "BJ Technologies (Beneteau)" 803 "Gill Sensors" 811 "Blue Water Desalination" 815 "FLIR" 824 "Undheim Systems" 826 "Lewmar" 838 "TeamSurv" 844 "Fell Marine" 847 "Oceanvolt" 862 "Prospec" 868 "Data Panel" 890 "L3 Technologies" 894 "Rhodan Marine Systems" 896 "Nexfour Solutions" 905 "ASA Electronics" 909 "Marines Co (South Korea)" 911 "Nautic-on" 917 "Sentinel" 929 "JL Marine Systems" 930 "Ecotronix" 944 "Zontisa Marine" 951 "EXOR International" 962 "Timbolier Industries" 963 "TJC Micro" 968 "Cox Powertrain" 969 "Blue Seas" 981 "Kobelt Manufacturing" 992 "Blue Ocean IOT" 997 "Xenta Systems" 999 "Signal K" 1004 "Ultraflex" 1008 "Lintest SmartBoat" 1011 "Soundmax" 1020 "Team Italia Marine (Onyx Marine Automation s.r.l)" 1021 "Entratech" 1022 "ITC" 1029 "The Marine Guardian" 1047 "Sonic" 1051 "ProNav" 1053 "Vetus Maxwell INC." 1056 "Lithium Pros" 1059 "Boatrax" 1062 "Marol Co ltd" 1065 "CALYPSO Instruments" 1066 "Spot Zero Water" 1069 "Lithionics Battery" 1070 "Quick-teck Electronics" 1075 "Uniden America" 1083 "Nauticoncept" 1084 "Shadow-Caster LED lighting" 1085 "Wet Sounds" 1088 "E-T-A Circuit Breakers" 1092 "Scheiber" 1100 "Smart Yachts International Limited" 1109 "Dockmate" 1114 "Bobs Machine" 1118 "L3Harris ASV" 1119 "Balmar" 1120 "Elettromedia" 1127 "Electromaax" 1140 "Across Oceans Systems" 1145 "Kiwi Yachting" 1150 "BSB Artificial Intelligence" 1151 "Orca Technologies" 1154 "TBS Electronics" 1158 "Technoton Electroics" 1160 "MG Energy Systems" 1169 "Sea Machine Robotics" 1171 "Vista Manufacturing" 1183 "Zipwake" 1186 "Sailmon" 1192 "Airmoniq Pro Kft" 1194 "Sierra Marine" 1200 "Xinuo Information Technology (Xiamen)" 1218 "Septentrio" 1233 "NKE Marine Electronics" 1238 "SuperTrack Aps" 1239 "Honda Electronics" 1245 "Raritan Engineering" 1249 "Integrated Power Solutions AG" 1260 "Interactive Technologies" 1283 "LTG-Tech" 1299 "Energy Solutions (UK)" 1300 "WATT Fuel Cell" 1302 "Pro Mainer" 1305 "Dragonfly Energy" 1306 "Koden Electronics" 1311 "Humphree" 1316 "Hinkley Yachts" 1317 "Global Marine Management GmbH (GMM)" 1320 "Triskel Marine" 1330 "Warwick Control Technologies" 1331 "Dolphin Charger" 1337 "Barnacle Systems" 1348 "Radian IoT" 1353 "Ocean LED Marine" 1359 "BluNav" 1361 "OVA (Nantong Saiyang Electronics Co., Ltd)" 1368 "RAD Propulsion" 1369 "Electric Yacht" 1372 "Elco Motor Yachts" 1384 "Tecnoseal Foundry S.r.l" 1385 "Pro Charging Systems" 1389 "EVEX" 1398 "Gobius Sensor Technology" 1403 "Arco Marine" 1408 "Lenco Marine" 1413 "Naocontrol" 1417 "Revatek" 1438 "Aeolionics" 1439 "PredictWind" 1440 "Egis Mobile Electric" 1445 "Starboard Yacht Group" 1446 "Roswell Marine" 1451 "ePropulsion (Guangdong ePropulsion Technology Ltd.)" 1452 "Micro-Air" 1453 "Vital Battery" 1458 "Ride Controller" 1460 "Tocaro Blue" 1461 "Vanquish Yachts" 1471 "FT Technologies" 1478 "Alps Alpine" 1481 "E-Force Marine" 1482 "CMC Marine" 1483 "Nanjing Sandemarine Information Technology" 1850 "Teleflex Marine (SeaStar Solutions)" 1851 "Raymarine" 1852 "Navionics" 1853 "Japan Radio" 1854 "Northstar Technologies" 1855 "Furuno" 1856 "Trimble" 1857 "Simrad" 1858 "Litton" 1859 "Kvasar" 1860 "MMP" 1861 "Vector Cantech" 1862 "Yamaha Marine" 1863 "Faria Instruments" ;
VAL_ 2583628032 Industry_Code 0 "Global" 1 "Highway" 2 "Agriculture" 3 "Construction" 4 "Marine Industry" 5 "Industrial" ;
VAL_ 2650736896 Manufacturer_Code 69 "ARKS Enterprises" 78 "FW Murphy/Enovation Controls" 80 "Twin Disc" 85 "Kohler Power Systems" 88 "Hemisphere GPS" 135 "Airmar" 137 "Maretron" 140 "Lowrance" 144 "Mercury Marine" 147 "Nautibus Electronic" 148 "Blue Water Data" 154 "Westerbeke" 157 "ISSPRO" 161 "Offshore Systems (UK)" 163 "Evinrude/BRP" 165 "CPAC Systems" 168 "Xantrex Technology" 169 "Marlin Technologies" 172 "Yanmar Marine" 174 "Volvo Penta" 176 "Carling Technologies Inc. (Moritz Aerospace)" 185 "Beede Instruments" 192 "Floscan Instrument" 193 "Nobeltec" 198 "Mystic Valley Communications" 199 "Actia" 201 "Disenos Y Technologia" 211 "Digital Switching Systems" 215 "Xintex/Atena" 224 "EMMI NETWORK" 228 "ZF" 229 "Garmin" 233 "Yacht Monitoring Solutions" 235 "Sailormade Marine Telemetry/Tetra Technology" 243 "Eride" 257 "Honda Motor" 272 "Groco" 273 "Actisense" 274 "Amphenol LTW Technology" 275 "Navico" 283 "Hamilton Jet" 285 "Sea Recovery" 286 "Coelmo SRL Italy" 295 "BEP Marine" 304 "Empir Bus" 305 "NovAtel" 306 "Sleipner Motor" 307 "MBW Technologies" 315 "ICOM" 328 "Qwerty" 329 "Dief" 341 "Boening Automationstechnologie" 345 "Korean Maritime University" 351 "Thrane and Thrane" 355 "Mastervolt" 356 "Fischer Panda Generators" 358 "Victron Energy" 370 "Rolls Royce Marine" 373 "Electronic Design" 374 "Northern Lights" 378 "Glendinning" 381 "B & G" 384 "Rose Point Navigation Systems" 385 "Johnson Outdoors Marine Electronics Inc Geonav" 394 "Capi 2" 396 "Beyond Measure" 400 "Livorsi Marine" 404 "ComNav" 409 "Chetco" 419 "Fusion Electronics" 421 "Standard Horizon" 422 "True Heading" 426 "Egersund Marine Electronics" 427 "em-trak Marine Electronics" 431 "Tohatsu Co, JP" 437 "Digital Yacht" 438 "Comar Systems Limited" 440 "Cummins" 443 "VDO (aka Continental-Corporation)" 451 "Parker Hannifin aka Village Marine Tech" 459 "Alltek Marine Electronics" 460 "SAN GIORGIO S.E.I.N" 466 "Veethree Electronics & Marine" 470 "SI-TEX Marine Electronics" 471 "Sea Cross Marine" 475 "GME aka Standard Communications" 476 "Humminbird Marine Electronics" 478 "Ocean Sat" 481 "Chetco Digital Instruments" 493 "Watcheye" 499 "Lcj Capteurs" 502 "Attwood Marine" 503 "Naviop S.R.L." 504 "Vesper Marine" 510 "Marinesoft" 513 "Simarine" 517 "NoLand Engineering" 518 "Transas USA" 529 "National Instruments Korea" 530 "National Marine Electronics Association" 532 "Onwa Marine" 540 "Webasto" 571 "Marinecraft (South Korea)" 573 "McMurdo Group aka Orolia" 578 "Advansea" 579 "KVH" 580 "San Jose Technology" 583 "Yacht Control" 586 "Suzuki Motor" 591 "US Coast Guard" 595 "Ship Module aka Customware" 600 "Aquatic AV" 605 "Aventics" 606 "Intellian" 612 "SamwonIT" 614 "Arlt Tecnologies" 637 "Bavaria Yachts" 641 "Diverse Yacht Services" 644 "Wema U.S.A dba KUS" 658 "Shenzhen Jiuzhou Himunication" 688 "Rockford" 699 "Harman International" 704 "JL Audio" 708 "Lars Thrane" 715 "Autonnic" 717 "Yacht Devices" 734 "REAP Systems" 735 "AEM Performance Electronics" 739 "LxNav" 741 "Littelfuse, Inc (formerly Carling Technologies)" 743 "DaeMyung" 744 "Woosung" 748 "ISOTTA IFRA srl" 773 "Clarion US" 776 "HMI Systems" 777 "Ocean Signal" 778 "Seakeeper" 781 "Poly Planar" 785 "Fischer Panda DE" 795 "Broyda Industries" 796 "Canadian Automotive" 797 "Tides Marine" 798 "Lumishore" 799 "Still Water Designs and Audio" 802 "BJ Technologies (Beneteau)" 803 "Gill Sensors" 811 "Blue Water Desalination" 815 "FLIR" 824 "Undheim Systems" 826 "Lewmar" 838 "TeamSurv" 844 "Fell Marine" 847 "Oceanvolt" 862 "Prospec" 868 "Data Panel" 890 "L3 Technologies" 894 "Rhodan Marine Systems" 896 "Nexfour Solutions" 905 "ASA Electronics" 909 "Marines Co (South Korea)" 911 "Nautic-on" 917 "Sentinel" 929 "JL Marine Systems" 930 "Ecotronix" 944 "Zontisa Marine" 951 "EXOR International" 962 "Timbolier Industries" 963 "TJC Micro" 968 "Cox Powertrain" 969 "Blue Seas" 981 "Kobelt Manufacturing" 992 "Blue Ocean IOT" 997 "Xenta Systems" 999 "Signal K" 1004 "Ultraflex" 1008 "Lintest SmartBoat" 1011 "Soundmax" 1020 "Team Italia Marine (Onyx Marine Automation s.r.l)" 1021 "Entratech" 1022 "ITC" 1029 "The Marine Guardian" 1047 "Sonic" 1051 "ProNav" 1053 "Vetus Maxwell INC." 1056 "Lithium Pros" 1059 "Boatrax" 1062 "Marol Co ltd" 1065 "CALYPSO Instruments" 1066 "Spot Zero Water" 1069 "Lithionics Battery" 1070 "Quick-teck Electronics" 1075 "Uniden America" 1083 "Nauticoncept" 1084 "Shadow-Caster LED lighting" 1085 "Wet Sounds" 1088 "E-T-A Circuit Breakers" 1092 "Scheiber" 1100 "Smart Yachts International Limited" 1109 "Dockmate" 1114 "Bobs Machine" 1118 "L3Harris ASV" 1119 "Balmar" 1120 "Elettromedia" 1127 "Electromaax" 1140 "Across Oceans Systems" 1145 "Kiwi Yachting" 1150 "BSB Artificial Intelligence" 1151 "Orca Technologies" 1154 "TBS Electronics" 1158 "Technoton Electroics" 1160 "MG Energy Systems" 1169 "Sea Machine Robotics" 1171 "Vista Manufacturing" 1183 "Zipwake" 1186 "Sailmon" 1192 "Airmoniq Pro Kft" 1194 "Sierra Marine" 1200 "Xinuo Information Technology (Xiamen)" 1218 "Septentrio" 1233 "NKE Marine Electronics" 1238 "SuperTrack Aps" 1239 "Honda Electronics" 1245 "Raritan Engineering" 1249 "Integrated Power Solutions AG" 1260 "Interactive Technologies" 1283 "LTG-Tech" 1299 "Energy Solutions (UK)" 1300 "WATT Fuel Cell" 1302 "Pro Mainer" 1305 "Dragonfly Energy" 1306 "Koden Electronics" 1311 "Humphree" 1316 "Hinkley Yachts" 1317 "Global Marine Management GmbH (GMM)" 1320 "Triskel Marine" 1330 "Warwick Control Technologies" 1331 "Dolphin Charger" 1337 "Barnacle Systems" 1348 "Radian IoT" 1353 "Ocean LED Marine" 1359 "BluNav" 1361 "OVA (Nantong Saiyang Electronics Co., Ltd)" 1368 "RAD Propulsion" 1369 "Electric Yacht" 1372 "Elco Motor Yachts" 1384 "Tecnoseal Foundry S.r.l" 1385 "Pro Charging Systems" 1389 "EVEX" 1398 "Gobius Sensor Technology" 1403 "Arco Marine" 1408 "Lenco Marine" 1413 "Naocontrol" 1417 "Revatek" 1438 "Aeolionics" 1439 "PredictWind" 1440 "Egis Mobile Electric" 1445 "Starboard Yacht Group" 1446 "Roswell Marine" 1451 "ePropulsion (Guangdong ePropulsion Technology Ltd.)" 1452 "Micro-Air" 1453 "Vital Battery" 1458 "Ride Controller" 1460 "Tocaro Blue" 1461 "Vanquish Yachts" 1471 "FT Technologies" 1478 "Alps Alpine" 1481 "E-Force Marine" 1482 "CMC Marine" 1483 "Nanjing Sandemarine Information Technology" 1850 "Teleflex Marine (SeaStar Solutions)" 1851 "Raymarine" 1852 "Navionics" 1853 "Japan Radio" 1854 "Northstar Technologies" 1855 "Furuno" 1856 "Trimble" 1857 "Simrad" 1858 "Litton" 1859 "Kvasar" 1860 "MMP" 1861 "Vector Cantech" 1862 "Yamaha Marine" 1863 "Faria Instruments" ;
VAL_ 2650736896 Industry_Code 0 "Global" 1 "Highway" 2 "Agriculture" 3 "Construction" 4 "Marine Industry" 5 "Industrial" ;
VAL_ 2650736896 Opcode 0 "Horn Control" 1 "Maintenance Reset Command" 2 "Maintenance Reset Response" 4 "Cruise Control" 5 "Global Brightness" 6 "Active Trim Command" 7 "Active Trim Status" 8 "Autopilot Command" 9 "Active Exhaust" 12 "Oil Level Check Command" 13 "Oil Level Reset Response" ;
VAL_ 2650736896 Manufacturer_Code 69 "ARKS Enterprises" 78 "FW Murphy/Enovation Controls" 80 "Twin Disc" 85 "Kohler Power Systems" 88 "Hemisphere GPS" 135 "Airmar" 137 "Maretron" 140 "Lowrance" 144 "Mercury Marine" 147 "Nautibus Electronic" 148 "Blue Water Data" 154 "Westerbeke" 157 "ISSPRO" 161 "Offshore Systems (UK)" 163 "Evinrude/BRP" 165 "CPAC Systems" 168 "Xantrex Technology" 169 "Marlin Technologies" 172 "Yanmar Marine" 174 "Volvo Penta" 176 "Carling Technologies Inc. (Moritz Aerospace)" 185 "Beede Instruments" 192 "Floscan Instrument" 193 "Nobeltec" 198 "Mystic Valley Communications" 199 "Actia" 201 "Disenos Y Technologia" 211 "Digital Switching Systems" 215 "Xintex/Atena" 224 "EMMI NETWORK" 228 "ZF" 229 "Garmin" 233 "Yacht Monitoring Solutions" 235 "Sailormade Marine Telemetry/Tetra Technology" 243 "Eride" 257 "Honda Motor" 272 "Groco" 273 "Actisense" 274 "Amphenol LTW Technology" 275 "Navico" 283 "Hamilton Jet" 285 "Sea Recovery" 286 "Coelmo SRL Italy" 295 "BEP Marine" 304 "Empir Bus" 305 "NovAtel" 306 "Sleipner Motor" 307 "MBW Technologies" 315 "ICOM" 328 "Qwerty" 329 "Dief" 341 "Boening Automationstechnologie" 345 "Korean Maritime University" 351 "Thrane and Thrane" 355 "Mastervolt" 356 "Fischer Panda Generators" 358 "Victron Energy" 370 "Rolls Royce Marine" 373 "Electronic Design" 374 "Northern Lights" 378 "Glendinning" 381 "B & G" 384 "Rose Point Navigation Systems" 385 "Johnson Outdoors Marine Electronics Inc Geonav" 394 "Capi 2" 396 "Beyond Measure" 400 "Livorsi Marine" 404 "ComNav" 409 "Chetco" 419 "Fusion Electronics" 421 "Standard Horizon" 422 "True Heading" 426 "Egersund Marine Electronics" 427 "em-trak Marine Electronics" 431 "Tohatsu Co, JP" 437 "Digital Yacht" 438 "Comar Systems Limited" 440 "Cummins" 443 "VDO (aka Continental-Corporation)" 451 "Parker Hannifin aka Village Marine Tech" 459 "Alltek Marine Electronics" 460 "SAN GIORGIO S.E.I.N" 466 "Veethree Electronics & Marine" 470 "SI-TEX Marine Electronics" 471 "Sea Cross Marine" 475 "GME aka Standard Communications" 476 "Humminbird Marine Electronics" 478 "Ocean Sat" 481 "Chetco Digital Instruments" 493 "Watcheye" 499 "Lcj Capteurs" 502 "Attwood Marine" 503 "Naviop S.R.L." 504 "Vesper Marine" 510 "Marinesoft" 513 "Simarine" 517 "NoLand Engineering" 518 "Transas USA" 529 "National Instruments Korea" 530 "National Marine Electronics Association" 532 "Onwa Marine" 540 "Webasto" 571 "Marinecraft (South Korea)" 573 "McMurdo Group aka Orolia" 578 "Advansea" 579 "KVH" 580 "San Jose Technology" 583 "Yacht Control" 586 "Suzuki Motor" 591 "US Coast Guard" 595 "Ship Module aka Customware" 600 "Aquatic AV" 605 "Aventics" 606 "Intellian" 612 "SamwonIT" 614 "Arlt Tecnologies" 637 "Bavaria Yachts" 641 "Diverse Yacht Services" 644 "Wema U.S.A dba KUS" 658 "Shenzhen Jiuzhou Himunication" 688 "Rockford" 699 "Harman International" 704 "JL Audio" 708 "Lars Thrane" 715 "Autonnic" 717 "Yacht Devices" 734 "REAP Systems" 735 "AEM Performance Electronics" 739 "LxNav" 741 "Littelfuse, Inc (formerly Carling Technologies)" 743 "DaeMyung" 744 "Woosung" 748 "ISOTTA IFRA srl" 773 "Clarion US" 776 "HMI Systems" 777 "Ocean Signal" 778 "Seakeeper" 781 "Poly Planar" 785 "Fischer Panda DE" 795 "Broyda Industries" 796 "Canadian Automotive" 797 "Tides Marine" 798 "Lumishore" 799 "Still Water Designs and Audio" 802 "BJ Technologies (Beneteau)" 803 "Gill Sensors" 811 "Blue Water Desalination" 815 "FLIR" 824 "Undheim Systems" 826 "Lewmar" 838 "TeamSurv" 844 "Fell Marine" 847 "Oceanvolt" 862 "Prospec" 868 "Data Panel" 890 "L3 Technologies" 894 "Rhodan Marine Systems" 896 "Nexfour Solutions" 905 "ASA Electronics" 909 "Marines Co (South Korea)" 911 "Nautic-on" 917 "Sentinel" 929 "JL Marine Systems" 930 "Ecotronix" 944 "Zontisa Marine" 951 "EXOR International" 962 "Timbolier Industries" 963 "TJC Micro" 968 "Cox Powertrain" 969 "Blue Seas" 981 "Kobelt Manufacturing" 992 "Blue Ocean IOT" 997 "Xenta Systems" 999 "Signal K" 1004 "Ultraflex" 1008 "Lintest SmartBoat" 1011 "Soundmax" 1020 "Team Italia Marine (Onyx Marine Automation s.r.l)" 1021 "Entratech" 1022 "ITC" 1029 "The Marine Guardian" 1047 "Sonic" 1051 "ProNav" 1053 "Vetus Maxwell INC." 1056 "Lithium Pros" 1059 "Boatrax" 1062 "Marol Co ltd" 1065 "CALYPSO Instruments" 1066 "Spot Zero Water" 1069 "Lithionics Battery" 1070 "Quick-teck Electronics" 1075 "Uniden America" 1083 "Nauticoncept" 1084 "Shadow-Caster LED lighting" 1085 "Wet Sounds" 1088 "E-T-A Circuit Breakers" 1092 "Scheiber" 1100 "Smart Yachts International Limited" 1109 "Dockmate" 1114 "Bobs Machine" 1118 "L3Harris ASV" 1119 "Balmar" 1120 "Elettromedia" 1127 "Electromaax" 1140 "Across Oceans Systems" 1145 "Kiwi Yachting" 1150 "BSB Artificial Intelligence" 1151 "Orca Technologies" 1154 "TBS Electronics" 1158 "Technoton Electroics" 1160 "MG Energy Systems" 1169 "Sea Machine Robotics" 1171 "Vista Manufacturing" 1183 "Zipwake" 1186 "Sailmon" 1192 "Airmoniq Pro Kft" 1194 "Sierra Marine" 1200 "Xinuo Information Technology (Xiamen)" 1218 "Septentrio" 1233 "NKE Marine Electronics" 1238 "SuperTrack Aps" 1239 "Honda Electronics" 1245 "Raritan Engineering" 1249 "Integrated Power Solutions AG" 1260 "Interactive Technologies" 1283 "LTG-Tech" 1299 "Energy Solutions (UK)" 1300 "WATT Fuel Cell" 1302 "Pro Mainer" 1305 "Dragonfly Energy" 1306 "Koden Electronics" 1311 "Humphree" 1316 "Hinkley Yachts" 1317 "Global Marine Management GmbH (GMM)" 1320 "Triskel Marine" 1330 "Warwick Control Technologies" 1331 "Dolphin Charger" 1337 "Barnacle Systems" 1348 "Radian IoT" 1353 "Ocean LED Marine" 1359 "BluNav" 1361 "OVA (Nantong Saiyang Electronics Co., Ltd)" 1368 "RAD Propulsion" 1369 "Electric Yacht" 1372 "Elco Motor Yachts" 1384 "Tecnoseal Foundry S.r.l" 1385 "Pro Charging Systems" 1389 "EVEX" 1398 "Gobius Sensor Technology" 1403 "Arco Marine" 1408 "Lenco Marine" 1413 "Naocontrol" 1417 "Revatek" 1438 "Aeolionics" 1439 "PredictWind" 1440 "Egis Mobile Electric" 1445 "Starboard Yacht Group" 1446 "Roswell Marine" 1451 "ePropulsion (Guangdong ePropulsion Technology Ltd.)" 1452 "Micro-Air" 1453 "Vital Battery" 1458 "Ride Controller" 1460 "Tocaro Blue" 1461 "Vanquish Yachts" 1471 "FT Technologies" 1478 "Alps Alpine" 1481 "E-Force Marine" 1482 "CMC Marine" 1483 "Nanjing Sandemarine Information Technology" 1850 "Teleflex Marine (SeaStar Solutions)" 1851 "Raymarine" 1852 "Navionics" 1853 "Japan Radio" 1854 "Northstar Technologies" 1855 "Furuno" 1856 "Trimble" 1857 "Simrad" 1858 "Litton" 1859 "Kvasar" 1860 "MMP" 1861 "Vector Cantech" 1862 "Yamaha Marine" 1863 "Faria Instruments" ;
VAL_ 2650736896 Industry_Code 0 "Global" 1 "Highway" 2 "Agriculture" 3 "Construction" 4 "Marine Industry" 5 "Industrial" ;
VAL_ 2650736896 Opcode 0 "Horn Control" 1 "Maintenance Reset Command" 2 "Maintenance Reset Response" 4 "Cruise Control" 5 "Global Brightness" 6 "Active Trim Command" 7 "Active Trim Status" 8 "Autopilot Command" 9 "Active Exhaust" 12 "Oil Level Check Command" 13 "Oil Level Reset Response" ;
VAL_ 2650736896 Manufacturer_Code 69 "ARKS Enterprises" 78 "FW Murphy/Enovation Controls" 80 "Twin Disc" 85 "Kohler Power Systems" 88 "Hemisphere GPS" 135 "Airmar" 137 "Maretron" 140 "Lowrance" 144 "Mercury Marine" 147 "Nautibus Electronic" 148 "Blue Water Data" 154 "Westerbeke" 157 "ISSPRO" 161 "Offshore Systems (UK)" 163 "Evinrude/BRP" 165 "CPAC Systems" 168 "Xantrex Technology" 169 "Marlin Technologies" 172 "Yanmar Marine" 174 "Volvo Penta" 176 "Carling Technologies Inc. (Moritz Aerospace)" 185 "Beede Instruments" 192 "Floscan Instrument" 193 "Nobeltec" 198 "Mystic Valley Communications" 199 "Actia" 201 "Disenos Y Technologia" 211 "Digital Switching Systems" 215 "Xintex/Atena" 224 "EMMI NETWORK" 228 "ZF" 229 "Garmin" 233 "Yacht Monitoring Solutions" 235 "Sailormade Marine Telemetry/Tetra Technology" 243 "Eride" 257 "Honda Motor" 272 "Groco" 273 "Actisense" 274 "Amphenol LTW Technology" 275 "Navico" 283 "Hamilton Jet" 285 "Sea Recovery" 286 "Coelmo SRL Italy" 295 "BEP Marine" 304 "Empir Bus" 305 "NovAtel" 306 "Sleipner Motor" 307 "MBW Technologies" 315 "ICOM" 328 "Qwerty" 329 "Dief" 341 "Boening Automationstechnologie" 345 "Korean Maritime University" 351 "Thrane and Thrane" 355 "Mastervolt" 356 "Fischer Panda Generators" 358 "Victron Energy" 370 "Rolls Royce Marine" 373 "Electronic Design" 374 "Northern Lights" 378 "Glendinning" 381 "B & G" 384 "Rose Point Navigation Systems" 385 "Johnson Outdoors Marine Electronics Inc Geonav" 394 "Capi 2" 396 "Beyond Measure" 400 "Livorsi Marine" 404 "ComNav" 409 "Chetco" 419 "Fusion Electronics" 421 "Standard Horizon" 422 "True Heading" 426 "Egersund Marine Electronics" 427 "em-trak Marine Electronics" 431 "Tohatsu Co, JP" 437 "Digital Yacht" 438 "Comar Systems Limited" 440 "Cummins" 443 "VDO (aka Continental-Corporation)" 451 "Parker Hannifin aka Village Marine Tech" 459 "Alltek Marine Electronics" 460 "SAN GIORGIO S.E.I.N" 466 "Veethree Electronics & Marine" 470 "SI-TEX Marine Electronics" 471 "Sea Cross Marine" 475 "GME aka Standard Communications" 476 "Humminbird Marine Electronics" 478 "Ocean Sat" 481 "Chetco Digital Instruments" 493 "Watcheye" 499 "Lcj Capteurs" 502 "Attwood Marine" 503 "Naviop S.R.L." 504 "Vesper Marine" 510 "Marinesoft" 513 "Simarine" 517 "NoLand Engineering" 518 "Transas USA" 529 "National Instruments Korea" 530 "National Marine Electronics Association" 532 "Onwa Marine" 540 "Webasto" 571 "Marinecraft (South Korea)" 573 "McMurdo Group aka Orolia" 578 "Advansea" 579 "KVH" 580 "San Jose Technology" 583 "Yacht Control" 586 "Suzuki Motor" 591 "US Coast Guard" 595 "Ship Module aka Customware" 600 "Aquatic AV" 605 "Aventics" 606 "Intellian" 612 "SamwonIT" 614 "Arlt Tecnologies" 637 "Bavaria Yachts" 641 "Diverse Yacht Services" 644 "Wema U.S.A dba KUS" 658 "Shenzhen Jiuzhou Himunication" 688 "Rockford" 699 "Harman International" 704 "JL Audio" 708 "Lars Thrane" 715 "Autonnic" 717 "Yacht Devices" 734 "REAP Systems" 735 "AEM Performance Electronics" 739 "LxNav" 741 "Littelfuse, Inc (formerly Carling Technologies)" 743 "DaeMyung" 744 "Woosung" 748 "ISOTTA IFRA srl" 773 "Clarion US" 776 "HMI Systems" 777 "Ocean Signal" 778 "Seakeeper" 781 "Poly Planar" 785 "Fischer Panda DE" 795 "Broyda Industries" 796 "Canadian Automotive" 797 "Tides Marine" 798 "Lumishore" 799 "Still Water Designs and Audio" 802 "BJ Technologies (Beneteau)" 803 "Gill Sensors" 811 "Blue Water Desalination" 815 "FLIR" 824 "Undheim Systems" 826 "Lewmar" 838 "TeamSurv" 844 "Fell Marine" 847 "Oceanvolt" 862 "Prospec" 868 "Data Panel" 890 "L3 Technologies" 894 "Rhodan Marine Systems" 896 "Nexfour Solutions" 905 "ASA Electronics" 909 "Marines Co (South Korea)" 911 "Nautic-on" 917 "Sentinel" 929 "JL Marine Systems" 930 "Ecotronix" 944 "Zontisa Marine" 951 "EXOR International" 962 "Timbolier Industries" 963 "TJC Micro" 968 "Cox Powertrain" 969 "Blue Seas" 981 "Kobelt Manufacturing" 992 "Blue Ocean IOT" 997 "Xenta Systems" 999 "Signal K" 1004 "Ultraflex" 1008 "Lintest SmartBoat" 1011 "Soundmax" 1020 "Team Italia Marine (Onyx Marine Automation s.r.l)" 1021 "Entratech" 1022 "ITC" 1029 "The Marine Guardian" 1047 "Sonic" 1051 "ProNav" 1053 "Vetus Maxwell INC." 1056 "Lithium Pros" 1059 "Boatrax" 1062 "Marol Co ltd" 1065 "CALYPSO Instruments" 1066 "Spot Zero Water" 1069 "Lithionics Battery" 1070 "Quick-teck Electronics" 1075 "Uniden America" 1083 "Nauticoncept" 1084 "Shadow-Caster LED lighting" 1085 "Wet Sounds" 1088 "E-T-A Circuit Breakers" 1092 "Scheiber" 1100 "Smart Yachts International Limited" 1109 "Dockmate" 1114 "Bobs Machine" 1118 "L3Harris ASV" 1119 "Balmar" 1120 "Elettromedia" 1127 "Electromaax" 1140 "Across Oceans Systems" 1145 "Kiwi Yachting" 1150 "BSB Artificial Intelligence" 1151 "Orca Technologies" 1154 "TBS Electronics" 1158 "Technoton Electroics" 1160 "MG Energy Systems" 1169 "Sea Machine Robotics" 1171 "Vista Manufacturing" 1183 "Zipwake" 1186 "Sailmon" 1192 "Airmoniq Pro Kft" 1194 "Sierra Marine" 1200 "Xinuo Information Technology (Xiamen)" 1218 "Septentrio" 1233 "NKE Marine Electronics" 1238 "SuperTrack Aps" 1239 "Honda Electronics" 1245 "Raritan Engineering" 1249 "Integrated Power Solutions AG" 1260 "Interactive Technologies" 1283 "LTG-Tech" 1299 "Energy Solutions (UK)" 1300 "WATT Fuel Cell" 1302 "Pro Mainer" 1305 "Dragonfly Energy" 1306 "Koden Electronics" 1311 "Humphree" 1316 "Hinkley Yachts" 1317 "Global Marine Management GmbH (GMM)" 1320 "Triskel Marine" 1330 "Warwick Control Technologies" 1331 "Dolphin Charger" 1337 "Barnacle Systems" 1348 "Radian IoT" 1353 "Ocean LED Marine" 1359 "BluNav" 1361 "OVA (Nantong Saiyang Electronics Co., Ltd)" 1368 "RAD Propulsion" 1369 "Electric Yacht" 1372 "Elco Motor Yachts" 1384 "Tecnoseal Foundry S.r.l" 1385 "Pro Charging Systems" 1389 "EVEX" 1398 "Gobius Sensor Technology" 1403 "Arco Marine" 1408 "Lenco Marine" 1413 "Naocontrol" 1417 "Revatek" 1438 "Aeolionics" 1439 "PredictWind" 1440 "Egis Mobile Electric" 1445 "Starboard Yacht Group" 1446 "Roswell Marine" 1451 "ePropulsion (Guangdong ePropulsion Technology Ltd.)" 1452 "Micro-Air" 1453 "Vital Battery" 1458 "Ride Controller" 1460 "Tocaro Blue" 1461 "Vanquish Yachts" 1471 "FT Technologies" 1478 "Alps Alpine" 1481 "E-Force Marine" 1482 "CMC Marine" 1483 "Nanjing Sandemarine Information Technology" 1850 "Teleflex Marine (SeaStar Solutions)" 1851 "Raymarine" 1852 "Navionics" 1853 "Japan Radio" 1854 "Northstar Technologies" 1855 "Furuno" 1856 "Trimble" 1857 "Simrad" 1858 "Litton" 1859 "Kvasar" 1860 "MMP" 1861 "Vector Cantech" 1862 "Yamaha Marine" 1863 "Faria Instruments" ;
VAL_ 2650736896 Industry_Code 0 "Global" 1 "Highway" 2 "Agriculture" 3 "Construction" 4 "Marine Industry" 5 "Industrial" ;
VAL_ 2650736896 Alarm_ID 10 "Shallow water" 11 "Deep water" 12 "Anchor depth" 13 "True wind shift" 14 "True wind high" 15 "True wind low" 16 "Low boat speed" 17 "High voltage" 18 "Low voltage" 19 "Depth data missing" 20 "Wind data missing" 21 "Nav data missing" 22 "Heading missing" 23 "XTE" 24 "Rudder data missing" 25 "Rudder controller fault" 26 "No rudder response" 27 "Rudder drive overload" 28 "High internal temperature" 29 "AP clutch overload" 30 "AP clutch disengaged" 31 "High drive supply" 32 "Low drive supply" 33 "No active autopilot control unit" 34 "No autopilot computer" 35 "Memory fail" 36 "Water temp missing" 37 "Low water temp" 38 "High water temp" 39 "Water temp rate" 40 "Fish" 41 "No GPS fix" 42 "WAAS/DGPS" 45 "Arrival" 46 "Anchor" 47 "Fuel low" 48 "Fuel high" 49 "Tank low" 50 "Tank high" 51 "BEP" 52 "Waypoint radius" 53 "CPA" 54 "AIS range to vessel" 55 "AIS vessel lost" 56 "Vessel message" 57 "Lightning" 58 "Severe weather" 59 "Storm" 61 "Engine Check" 62 "Engine over temperature" 63 "Engine low oil pressure" 64 "Engine low oil level" 65 "Engine low fuel pressure" 66 "Engine low voltage" 67 "Engine low coolant level" 68 "Engine water flow" 69 "Engine water in fuel" 70 "Engine charge" 71 "Engine preheat" 72 "Engine high boost pressure" 73 "Engine rev limit" 74 "Engine EGR system" 75 "Engine throttle position" 76 "Engine emergency stop" 77 "Engine warning level 1" 78 "Engine warning level 2" 79 "Engine power reduction" 80 "Engine maintenance" 81 "Engine comm error" 82 "Engine throttle" 83 "Engine start protect" 84 "Engine shutting down" 85 "Transmission Check" 86 "Transmission over temperature" 87 "Transmission low oil pressure" 88 "Transmission low oil level" 89 "Sail drive" 96 "Fresh water low" 97 "Fresh water high" 98 "Gray water low" 99 "Gray water high" 100 "Live well low" 101 "Live well high" 102 "Oil low" 103 "Oil high" 104 "Black water low" 105 "Black water high" 106 "Weather data missing" 107 "AP Position data missing" 108 "AP Speed data missing" 109 "AP Depth data missing" 110 "AP Heading data missing" 111 "AP Nav data missing" 112 "AP Off course" 113 "AP Rudder data missing" 114 "AP Wind data missing" 115 "Radar guard zone" 116 "MARPA target lost" 117 "MARPA unavailable" 118 "Dangerous vessel" 119 "Radar error" 120 "CZone critical" 121 "CZone important" 122 "CZone standard" 123 "CZone warning" 124 "True wind shift" 125 "EVC Com Error" 126 "EVC override" 127 "High drive temperature" 128 "Drive inhibit" 129 "CAN bus supply overload" 130 "Drive ref voltage missing" 131 "Rudder limit" 132 "Compass difference" 133 "AP Low boat speed" 134 "Monitor compass missing" 135 "Cross track distance limit" 137 "End of route" 138 "Compass alignment" 139 "R.A.I.M" 141 "Off heading" 142 "Supply voltage" 143 "Low CAN bus voltage" 144 "CAN bus failure" 145 "Drive ready missing" 146 "Drive computer missing" 147 "External mode illegal" 148 "Rudder too slow" 149 "Wheel over" 150 "Thruster inhibited" 151 "Check heading" 152 "True wind speed high" 153 "Override" 154 "Speed through water rationality fault" 155 "No drives available" 156 "Fuel remaining low" 157 "Fuel remaining high" 158 "Generator Check" 159 "Generator over temperature" 160 "Generator low oil pressure" 161 "Generator low oil level" 162 "Generator low fuel pressure" 163 "Generator low voltage" 164 "Generator low coolant level" 165 "Generator water flow" 166 "Generator water in fuel" 167 "Generator charge" 168 "Generator preheat" 169 "Generator high boost pressure" 170 "Generator rev limit" 171 "Generator EGR system" 172 "Generator throttle position" 173 "Generator emergency stop" 174 "Generator warning level 1" 175 "Generator warning level 2" 176 "Generator power reduction" 177 "Generator maintenance" 178 "Generator comm error" 179 "Generator throttle" 180 "Generator start protect" 181 "Generator shutting down" 182 "Shallow aft depth" 183 "Forward range" 245 "Alarm source missing" 246 "External" 247 "EVC Com Error" 248 "Wind sensor battery low" 266 "Gasoline low" 267 "Gasoline high" 268 "Charging System" 269 "Seawater Flow" 270 "Water in Drive Seal" 272 "Turnover" 273 "Helm ECU Detect Failure" 274 "Joystick ECU Detect Failure" 275 "Drive ECU Detect Failure" 276 "Hot Transmission" 277 "Low Gear Oil Pressure" 278 "Low Drive Lub Oil Level" 285 "Check Thermostat" 287 "Track offset active" 385 "Navigation Not Supported" ;
VAL_ 2650736896 Alarm_State 0 "Disabled" 1 "Normal" 2 "Active" 3 "Silenced" 4 "Acknowledged" 5 "Awaiting Acknowledge" ;
VAL_ 2650736896 Alarm_Severity 1 "Emergency Alarm" 2 "Alarm" 5 "Warning" 8 "Caution" ;
VAL_ 2583628288 Manufacturer_Code 69 "ARKS Enterprises" 78 "FW Murphy/Enovation Controls" 80 "Twin Disc" 85 "Kohler Power Systems" 88 "Hemisphere GPS" 135 "Airmar" 137 "Maretron" 140 "Lowrance" 144 "Mercury Marine" 147 "Nautibus Electronic" 148 "Blue Water Data" 154 "Westerbeke" 157 "ISSPRO" 161 "Offshore Systems (UK)" 163 "Evinrude/BRP" 165 "CPAC Systems" 168 "Xantrex Technology" 169 "Marlin Technologies" 172 "Yanmar Marine" 174 "Volvo Penta" 176 "Carling Technologies Inc. (Moritz Aerospace)" 185 "Beede Instruments" 192 "Floscan Instrument" 193 "Nobeltec" 198 "Mystic Valley Communications" 199 "Actia" 201 "Disenos Y Technologia" 211 "Digital Switching Systems" 215 "Xintex/Atena" 224 "EMMI NETWORK" 228 "ZF" 229 "Garmin" 233 "Yacht Monitoring Solutions" 235 "Sailormade Marine Telemetry/Tetra Technology" 243 "Eride" 257 "Honda Motor" 272 "Groco" 273 "Actisense" 274 "Amphenol LTW Technology" 275 "Navico" 283 "Hamilton Jet" 285 "Sea Recovery" 286 "Coelmo SRL Italy" 295 "BEP Marine" 304 "Empir Bus" 305 "NovAtel" 306 "Sleipner Motor" 307 "MBW Technologies" 315 "ICOM" 328 "Qwerty" 329 "Dief" 341 "Boening Automationstechnologie" 345 "Korean Maritime University" 351 "Thrane and Thrane" 355 "Mastervolt" 356 "Fischer Panda Generators" 358 "Victron Energy" 370 "Rolls Royce Marine" 373 "Electronic Design" 374 "Northern Lights" 378 "Glendinning" 381 "B & G" 384 "Rose Point Navigation Systems" 385 "Johnson Outdoors Marine Electronics Inc Geonav" 394 "Capi 2" 396 "Beyond Measure" 400 "Livorsi Marine" 404 "ComNav" 409 "Chetco" 419 "Fusion Electronics" 421 "Standard Horizon" 422 "True Heading" 426 "Egersund Marine Electronics" 427 "em-trak Marine Electronics" 431 "Tohatsu Co, JP" 437 "Digital Yacht" 438 "Comar Systems Limited" 440 "Cummins" 443 "VDO (aka Continental-Corporation)" 451 "Parker Hannifin aka Village Marine Tech" 459 "Alltek Marine Electronics" 460 "SAN GIORGIO S.E.I.N" 466 "Veethree Electronics & Marine" 470 "SI-TEX Marine Electronics" 471 "Sea Cross Marine" 475 "GME aka Standard Communications" 476 "Humminbird Marine Electronics" 478 "Ocean Sat" 481 "Chetco Digital Instruments" 493 "Watcheye" 499 "Lcj Capteurs" 502 "Attwood Marine" 503 "Naviop S.R.L." 504 "Vesper Marine" 510 "Marinesoft" 513 "Simarine" 517 "NoLand Engineering" 518 "Transas USA" 529 "National Instruments Korea" 530 "National Marine Electronics Association" 532 "Onwa Marine" 540 "Webasto" 571 "Marinecraft (South Korea)" 573 "McMurdo Group aka Orolia" 578 "Advansea" 579 "KVH" 580 "San Jose Technology" 583 "Yacht Control" 586 "Suzuki Motor" 591 "US Coast Guard" 595 "Ship Module aka Customware" 600 "Aquatic AV" 605 "Aventics" 606 "Intellian" 612 "SamwonIT" 614 "Arlt Tecnologies" 637 "Bavaria Yachts" 641 "Diverse Yacht Services" 644 "Wema U.S.A dba KUS" 658 "Shenzhen Jiuzhou Himunication" 688 "Rockford" 699 "Harman International" 704 "JL Audio" 708 "Lars Thrane" 715 "Autonnic" 717 "Yacht Devices" 734 "REAP Systems" 735 "AEM Performance Electronics" 739 "LxNav" 741 "Littelfuse, Inc (formerly Carling Technologies)" 743 "DaeMyung" 744 "Woosung" 748 "ISOTTA IFRA srl" 773 "Clarion US" 776 "HMI Systems" 777 "Ocean Signal" 778 "Seakeeper" 781 "Poly Planar" 785 "Fischer Panda DE" 795 "Broyda Industries" 796 "Canadian Automotive" 797 "Tides Marine" 798 "Lumishore" 799 "Still Water Designs and Audio" 802 "BJ Technologies (Beneteau)" 803 "Gill Sensors" 811 "Blue Water Desalination" 815 "FLIR" 824 "Undheim Systems" 826 "Lewmar" 838 "TeamSurv" 844 "Fell Marine" 847 "Oceanvolt" 862 "Prospec" 868 "Data Panel" 890 "L3 Technologies" 894 "Rhodan Marine Systems" 896 "Nexfour Solutions" 905 "ASA Electronics" 909 "Marines Co (South Korea)" 911 "Nautic-on" 917 "Sentinel" 929 "JL Marine Systems" 930 "Ecotronix" 944 "Zontisa Marine" 951 "EXOR International" 962 "Timbolier Industries" 963 "TJC Micro" 968 "Cox Powertrain" 969 "Blue Seas" 981 "Kobelt Manufacturing" 992 "Blue Ocean IOT" 997 "Xenta Systems" 999 "Signal K" 1004 "Ultraflex" 1008 "Lintest SmartBoat" 1011 "Soundmax" 1020 "Team Italia Marine (Onyx Marine Automation s.r.l)" 1021 "Entratech" 1022 "ITC" 1029 "The Marine Guardian" 1047 "Sonic" 1051 "ProNav" 1053 "Vetus Maxwell INC." 1056 "Lithium Pros" 1059 "Boatrax" 1062 "Marol Co ltd" 1065 "CALYPSO Instruments" 1066 "Spot Zero Water" 1069 "Lithionics Battery" 1070 "Quick-teck Electronics" 1075 "Uniden America" 1083 "Nauticoncept" 1084 "Shadow-Caster LED lighting" 1085 "Wet Sounds" 1088 "E-T-A Circuit Breakers" 1092 "Scheiber" 1100 "Smart Yachts International Limited" 1109 "Dockmate" 1114 "Bobs Machine" 1118 "L3Harris ASV" 1119 "Balmar" 1120 "Elettromedia" 1127 "Electromaax" 1140 "Across Oceans Systems" 1145 "Kiwi Yachting" 1150 "BSB Artificial Intelligence" 1151 "Orca Technologies" 1154 "TBS Electronics" 1158 "Technoton Electroics" 1160 "MG Energy Systems" 1169 "Sea Machine Robotics" 1171 "Vista Manufacturing" 1183 "Zipwake" 1186 "Sailmon" 1192 "Airmoniq Pro Kft" 1194 "Sierra Marine" 1200 "Xinuo Information Technology (Xiamen)" 1218 "Septentrio" 1233 "NKE Marine Electronics" 1238 "SuperTrack Aps" 1239 "Honda Electronics" 1245 "Raritan Engineering" 1249 "Integrated Power Solutions AG" 1260 "Interactive Technologies" 1283 "LTG-Tech" 1299 "Energy Solutions (UK)" 1300 "WATT Fuel Cell" 1302 "Pro Mainer" 1305 "Dragonfly Energy" 1306 "Koden Electronics" 1311 "Humphree" 1316 "Hinkley Yachts" 1317 "Global Marine Management GmbH (GMM)" 1320 "Triskel Marine" 1330 "Warwick Control Technologies" 1331 "Dolphin Charger" 1337 "Barnacle Systems" 1348 "Radian IoT" 1353 "Ocean LED Marine" 1359 "BluNav" 1361 "OVA (Nantong Saiyang Electronics Co., Ltd)" 1368 "RAD Propulsion" 1369 "Electric Yacht" 1372 "Elco Motor Yachts" 1384 "Tecnoseal Foundry S.r.l" 1385 "Pro Charging Systems" 1389 "EVEX" 1398 "Gobius Sensor Technology" 1403 "Arco Marine" 1408 "Lenco Marine" 1413 "Naocontrol" 1417 "Revatek" 1438 "Aeolionics" 1439 "PredictWind" 1440 "Egis Mobile Electric" 1445 "Starboard Yacht Group" 1446 "Roswell Marine" 1451 "ePropulsion (Guangdong ePropulsion Technology Ltd.)" 1452 "Micro-Air" 1453 "Vital Battery" 1458 "Ride Controller" 1460 "Tocaro Blue" 1461 "Vanquish Yachts" 1471 "FT Technologies" 1478 "Alps Alpine" 1481 "E-Force Marine" 1482 "CMC Marine" 1483 "Nanjing Sandemarine Information Technology" 1850 "Teleflex Marine (SeaStar Solutions)" 1851 "Raymarine" 1852 "Navionics" 1853 "Japan Radio" 1854 "Northstar Technologies" 1855 "Furuno" 1856 "Trimble" 1857 "Simrad" 1858 "Litton" 1859 "Kvasar" 1860 "MMP" 1861 "Vector Cantech" 1862 "Yamaha Marine" 1863 "Faria Instruments" ;
VAL_ 2583628288 Industry_Code 0 "Global" 1 "Highway" 2 "Agriculture" 3 "Construction" 4 "Marine Industry" 5 "Industrial" ;
VAL_ 2315192832 Manufacturer_Code 69 "ARKS Enterprises" 78 "FW Murphy/Enovation Controls" 80 "Twin Disc" 85 "Kohler Power Systems" 88 "Hemisphere GPS" 135 "Airmar" 137 "Maretron" 140 "Lowrance" 144 "Mercury Marine" 147 "Nautibus Electronic" 148 "Blue Water Data" 154 "Westerbeke" 157 "ISSPRO" 161 "Offshore Systems (UK)" 163 "Evinrude/BRP" 165 "CPAC Systems" 168 "Xantrex Technology" 169 "Marlin Technologies" 172 "Yanmar Marine" 174 "Volvo Penta" 176 "Carling Technologies Inc. (Moritz Aerospace)" 185 "Beede Instruments" 192 "Floscan Instrument" 193 "Nobeltec" 198 "Mystic Valley Communications" 199 "Actia" 201 "Disenos Y Technologia" 211 "Digital Switching Systems" 215 "Xintex/Atena" 224 "EMMI NETWORK" 228 "ZF" 229 "Garmin" 233 "Yacht Monitoring Solutions" 235 "Sailormade Marine Telemetry/Tetra Technology" 243 "Eride" 257 "Honda Motor" 272 "Groco" 273 "Actisense" 274 "Amphenol LTW Technology" 275 "Navico" 283 "Hamilton Jet" 285 "Sea Recovery" 286 "Coelmo SRL Italy" 295 "BEP Marine" 304 "Empir Bus" 305 "NovAtel" 306 "Sleipner Motor" 307 "MBW Technologies" 315 "ICOM" 328 "Qwerty" 329 "Dief" 341 "Boening Automationstechnologie" 345 "Korean Maritime University" 351 "Thrane and Thrane" 355 "Mastervolt" 356 "Fischer Panda Generators" 358 "Victron Energy" 370 "Rolls Royce Marine" 373 "Electronic Design" 374 "Northern Lights" 378 "Glendinning" 381 "B & G" 384 "Rose Point Navigation Systems" 385 "Johnson Outdoors Marine Electronics Inc Geonav" 394 "Capi 2" 396 "Beyond Measure" 400 "Livorsi Marine" 404 "ComNav" 409 "Chetco" 419 "Fusion Electronics" 421 "Standard Horizon" 422 "True Heading" 426 "Egersund Marine Electronics" 427 "em-trak Marine Electronics" 431 "Tohatsu Co, JP" 437 "Digital Yacht" 438 "Comar Systems Limited" 440 "Cummins" 443 "VDO (aka Continental-Corporation)" 451 "Parker Hannifin aka Village Marine Tech" 459 "Alltek Marine Electronics" 460 "SAN GIORGIO S.E.I.N" 466 "Veethree Electronics & Marine" 470 "SI-TEX Marine Electronics" 471 "Sea Cross Marine" 475 "GME aka Standard Communications" 476 "Humminbird Marine Electronics" 478 "Ocean Sat" 481 "Chetco Digital Instruments" 493 "Watcheye" 499 "Lcj Capteurs" 502 "Attwood Marine" 503 "Naviop S.R.L." 504 "Vesper Marine" 510 "Marinesoft" 513 "Simarine" 517 "NoLand Engineering" 518 "Transas USA" 529 "National Instruments Korea" 530 "National Marine Electronics Association" 532 "Onwa Marine" 540 "Webasto" 571 "Marinecraft (South Korea)" 573 "McMurdo Group aka Orolia" 578 "Advansea" 579 "KVH" 580 "San Jose Technology" 583 "Yacht Control" 586 "Suzuki Motor" 591 "US Coast Guard" 595 "Ship Module aka Customware" 600 "Aquatic AV" 605 "Aventics" 606 "Intellian" 612 "SamwonIT" 614 "Arlt Tecnologies" 637 "Bavaria Yachts" 641 "Diverse Yacht Services" 644 "Wema U.S.A dba KUS" 658 "Shenzhen Jiuzhou Himunication" 688 "Rockford" 699 "Harman International" 704 "JL Audio" 708 "Lars Thrane" 715 "Autonnic" 717 "Yacht Devices" 734 "REAP Systems" 735 "AEM Performance Electronics" 739 "LxNav" 741 "Littelfuse, Inc (formerly Carling Technologies)" 743 "DaeMyung" 744 "Woosung" 748 "ISOTTA IFRA srl" 773 "Clarion US" 776 "HMI Systems" 777 "Ocean Signal" 778 "Seakeeper" 781 "Poly Planar" 785 "Fischer Panda DE" 795 "Broyda Industries" 796 "Canadian Automotive" 797 "Tides Marine" 798 "Lumishore" 799 "Still Water Designs and Audio" 802 "BJ Technologies (Beneteau)" 803 "Gill Sensors" 811 "Blue Water Desalination" 815 "FLIR" 824 "Undheim Systems" 826 "Lewmar" 838 "TeamSurv" 844 "Fell Marine" 847 "Oceanvolt" 862 "Prospec" 868 "Data Panel" 890 "L3 Technologies" 894 "Rhodan Marine Systems" 896 "Nexfour Solutions" 905 "ASA Electronics" 909 "Marines Co (South Korea)" 911 "Nautic-on" 917 "Sentinel" 929 "JL Marine Systems" 930 "Ecotronix" 944 "Zontisa Marine" 951 "EXOR International" 962 "Timbolier Industries" 963 "TJC Micro" 968 "Cox Powertrain" 969 "Blue Seas" 981 "Kobelt Manufacturing" 992 "Blue Ocean IOT" 997 "Xenta Systems" 999 "Signal K" 1004 "Ultraflex" 1008 "Lintest SmartBoat" 1011 "Soundmax" 1020 "Team Italia Marine (Onyx Marine Automation s.r.l)" 1021 "Entratech" 1022 "ITC" 1029 "The Marine Guardian" 1047 "Sonic" 1051 "ProNav" 1053 "Vetus Maxwell INC." 1056 "Lithium Pros" 1059 "Boatrax" 1062 "Marol Co ltd" 1065 "CALYPSO Instruments" 1066 "Spot Zero Water" 1069 "Lithionics Battery" 1070 "Quick-teck Electronics" 1075 "Uniden America" 1083 "Nauticoncept" 1084 "Shadow-Caster LED lighting" 1085 "Wet Sounds" 1088 "E-T-A Circuit Breakers" 1092 "Scheiber" 1100 "Smart Yachts International Limited" 1109 "Dockmate" 1114 "Bobs Machine" 1118 "L3Harris ASV" 1119 "Balmar" 1120 "Elettromedia" 1127 "Electromaax" 1140 "Across Oceans Systems" 1145 "Kiwi Yachting" 1150 "BSB Artificial Intelligence" 1151 "Orca Technologies" 1154 "TBS Electronics" 1158 "Technoton Electroics" 1160 "MG Energy Systems" 1169 "Sea Machine Robotics" 1171 "Vista Manufacturing" 1183 "Zipwake" 1186 "Sailmon" 1192 "Airmoniq Pro Kft" 1194 "Sierra Marine" 1200 "Xinuo Information Technology (Xiamen)" 1218 "Septentrio" 1233 "NKE Marine Electronics" 1238 "SuperTrack Aps" 1239 "Honda Electronics" 1245 "Raritan Engineering" 1249 "Integrated Power Solutions AG" 1260 "Interactive Technologies" 1283 "LTG-Tech" 1299 "Energy Solutions (UK)" 1300 "WATT Fuel Cell" 1302 "Pro Mainer" 1305 "Dragonfly Energy" 1306 "Koden Electronics" 1311 "Humphree" 1316 "Hinkley Yachts" 1317 "Global Marine Management GmbH (GMM)" 1320 "Triskel Marine" 1330 "Warwick Control Technologies" 1331 "Dolphin Charger" 1337 "Barnacle Systems" 1348 "Radian IoT" 1353 "Ocean LED Marine" 1359 "BluNav" 1361 "OVA (Nantong Saiyang Electronics Co., Ltd)" 1368 "RAD Propulsion" 1369 "Electric Yacht" 1372 "Elco Motor Yachts" 1384 "Tecnoseal Foundry S.r.l" 1385 "Pro Charging Systems" 1389 "EVEX" 1398 "Gobius Sensor Technology" 1403 "Arco Marine" 1408 "Lenco Marine" 1413 "Naocontrol" 1417 "Revatek" 1438 "Aeolionics" 1439 "PredictWind" 1440 "Egis Mobile Electric" 1445 "Starboard Yacht Group" 1446 "Roswell Marine" 1451 "ePropulsion (Guangdong ePropulsion Technology Ltd.)" 1452 "Micro-Air" 1453 "Vital Battery" 1458 "Ride Controller" 1460 "Tocaro Blue" 1461 "Vanquish Yachts" 1471 "FT Technologies" 1478 "Alps Alpine" 1481 "E-Force Marine" 1482 "CMC Marine" 1483 "Nanjing Sandemarine Information Technology" 1850 "Teleflex Marine (SeaStar Solutions)" 1851 "Raymarine" 1852 "Navionics" 1853 "Japan Radio" 1854 "Northstar Technologies" 1855 "Furuno" 1856 "Trimble" 1857 "Simrad" 1858 "Litton" 1859 "Kvasar" 1860 "MMP" 1861 "Vector Cantech" 1862 "Yamaha Marine" 1863 "Faria Instruments" ;
VAL_ 2315192832 Industry_Code 0 "Global" 1 "Highway" 2 "Agriculture" 3 "Construction" 4 "Marine Industry" 5 "Industrial" ;
VAL_ 2650737152 Manufacturer_Code 69 "ARKS Enterprises" 78 "FW Murphy/Enovation Controls" 80 "Twin Disc" 85 "Kohler Power Systems" 88 "Hemisphere GPS" 135 "Airmar" 137 "Maretron" 140 "Lowrance" 144 "Mercury Marine" 147 "Nautibus Electronic" 148 "Blue Water Data" 154 "Westerbeke" 157 "ISSPRO" 161 "Offshore Systems (UK)" 163 "Evinrude/BRP" 165 "CPAC Systems" 168 "Xantrex Technology" 169 "Marlin Technologies" 172 "Yanmar Marine" 174 "Volvo Penta" 176 "Carling Technologies Inc. (Moritz Aerospace)" 185 "Beede Instruments" 192 "Floscan Instrument" 193 "Nobeltec" 198 "Mystic Valley Communications" 199 "Actia" 201 "Disenos Y Technologia" 211 "Digital Switching Systems" 215 "Xintex/Atena" 224 "EMMI NETWORK" 228 "ZF" 229 "Garmin" 233 "Yacht Monitoring Solutions" 235 "Sailormade Marine Telemetry/Tetra Technology" 243 "Eride" 257 "Honda Motor" 272 "Groco" 273 "Actisense" 274 "Amphenol LTW Technology" 275 "Navico" 283 "Hamilton Jet" 285 "Sea Recovery" 286 "Coelmo SRL Italy" 295 "BEP Marine" 304 "Empir Bus" 305 "NovAtel" 306 "Sleipner Motor" 307 "MBW Technologies" 315 "ICOM" 328 "Qwerty" 329 "Dief" 341 "Boening Automationstechnologie" 345 "Korean Maritime University" 351 "Thrane and Thrane" 355 "Mastervolt" 356 "Fischer Panda Generators" 358 "Victron Energy" 370 "Rolls Royce Marine" 373 "Electronic Design" 374 "Northern Lights" 378 "Glendinning" 381 "B & G" 384 "Rose Point Navigation Systems" 385 "Johnson Outdoors Marine Electronics Inc Geonav" 394 "Capi 2" 396 "Beyond Measure" 400 "Livorsi Marine" 404 "ComNav" 409 "Chetco" 419 "Fusion Electronics" 421 "Standard Horizon" 422 "True Heading" 426 "Egersund Marine Electronics" 427 "em-trak Marine Electronics" 431 "Tohatsu Co, JP" 437 "Digital Yacht" 438 "Comar Systems Limited" 440 "Cummins" 443 "VDO (aka Continental-Corporation)" 451 "Parker Hannifin aka Village Marine Tech" 459 "Alltek Marine Electronics" 460 "SAN GIORGIO S.E.I.N" 466 "Veethree Electronics & Marine" 470 "SI-TEX Marine Electronics" 471 "Sea Cross Marine" 475 "GME aka Standard Communications" 476 "Humminbird Marine Electronics" 478 "Ocean Sat" 481 "Chetco Digital Instruments" 493 "Watcheye" 499 "Lcj Capteurs" 502 "Attwood Marine" 503 "Naviop S.R.L." 504 "Vesper Marine" 510 "Marinesoft" 513 "Simarine" 517 "NoLand Engineering" 518 "Transas USA" 529 "National Instruments Korea" 530 "National Marine Electronics Association" 532 "Onwa Marine" 540 "Webasto" 571 "Marinecraft (South Korea)" 573 "McMurdo Group aka Orolia" 578 "Advansea" 579 "KVH" 580 "San Jose Technology" 583 "Yacht Control" 586 "Suzuki Motor" 591 "US Coast Guard" 595 "Ship Module aka Customware" 600 "Aquatic AV" 605 "Aventics" 606 "Intellian" 612 "SamwonIT" 614 "Arlt Tecnologies" 637 "Bavaria Yachts" 641 "Diverse Yacht Services" 644 "Wema U.S.A dba KUS" 658 "Shenzhen Jiuzhou Himunication" 688 "Rockford" 699 "Harman International" 704 "JL Audio" 708 "Lars Thrane" 715 "Autonnic" 717 "Yacht Devices" 734 "REAP Systems" 735 "AEM Performance Electronics" 739 "LxNav" 741 "Littelfuse, Inc (formerly Carling Technologies)" 743 "DaeMyung" 744 "Woosung" 748 "ISOTTA IFRA srl" 773 "Clarion US" 776 "HMI Systems" 777 "Ocean Signal" 778 "Seakeeper" 781 "Poly Planar" 785 "Fischer Panda DE" 795 "Broyda Industries" 796 "Canadian Automotive" 797 "Tides Marine" 798 "Lumishore" 799 "Still Water Designs and Audio" 802 "BJ Technologies (Beneteau)" 803 "Gill Sensors" 811 "Blue Water Desalination" 815 "FLIR" 824 "Undheim Systems" 826 "Lewmar" 838 "TeamSurv" 844 "Fell Marine" 847 "Oceanvolt" 862 "Prospec" 868 "Data Panel" 890 "L3 Technologies" 894 "Rhodan Marine Systems" 896 "Nexfour Solutions" 905 "ASA Electronics" 909 "Marines Co (South Korea)" 911 "Nautic-on" 917 "Sentinel" 929 "JL Marine Systems" 930 "Ecotronix" 944 "Zontisa Marine" 951 "EXOR International" 962 "Timbolier Industries" 963 "TJC Micro" 968 "Cox Powertrain" 969 "Blue Seas" 981 "Kobelt Manufacturing" 992 "Blue Ocean IOT" 997 "Xenta Systems" 999 "Signal K" 1004 "Ultraflex" 1008 "Lintest SmartBoat" 1011 "Soundmax" 1020 "Team Italia Marine (Onyx Marine Automation s.r.l)" 1021 "Entratech" 1022 "ITC" 1029 "The Marine Guardian" 1047 "Sonic" 1051 "ProNav" 1053 "Vetus Maxwell INC." 1056 "Lithium Pros" 1059 "Boatrax" 1062 "Marol Co ltd" 1065 "CALYPSO Instruments" 1066 "Spot Zero Water" 1069 "Lithionics Battery" 1070 "Quick-teck Electronics" 1075 "Uniden America" 1083 "Nauticoncept" 1084 "Shadow-Caster LED lighting" 1085 "Wet Sounds" 1088 "E-T-A Circuit Breakers" 1092 "Scheiber" 1100 "Smart Yachts International Limited" 1109 "Dockmate" 1114 "Bobs Machine" 1118 "L3Harris ASV" 1119 "Balmar" 1120 "Elettromedia" 1127 "Electromaax" 1140 "Across Oceans Systems" 1145 "Kiwi Yachting" 1150 "BSB Artificial Intelligence" 1151 "Orca Technologies" 1154 "TBS Electronics" 1158 "Technoton Electroics" 1160 "MG Energy Systems" 1169 "Sea Machine Robotics" 1171 "Vista Manufacturing" 1183 "Zipwake" 1186 "Sailmon" 1192 "Airmoniq Pro Kft" 1194 "Sierra Marine" 1200 "Xinuo Information Technology (Xiamen)" 1218 "Septentrio" 1233 "NKE Marine Electronics" 1238 "SuperTrack Aps" 1239 "Honda Electronics" 1245 "Raritan Engineering" 1249 "Integrated Power Solutions AG" 1260 "Interactive Technologies" 1283 "LTG-Tech" 1299 "Energy Solutions (UK)" 1300 "WATT Fuel Cell" 1302 "Pro Mainer" 1305 "Dragonfly Energy" 1306 "Koden Electronics" 1311 "Humphree" 1316 "Hinkley Yachts" 1317 "Global Marine Management GmbH (GMM)" 1320 "Triskel Marine" 1330 "Warwick Control Technologies" 1331 "Dolphin Charger" 1337 "Barnacle Systems" 1348 "Radian IoT" 1353 "Ocean LED Marine" 1359 "BluNav" 1361 "OVA (Nantong Saiyang Electronics Co., Ltd)" 1368 "RAD Propulsion" 1369 "Electric Yacht" 1372 "Elco Motor Yachts" 1384 "Tecnoseal Foundry S.r.l" 1385 "Pro Charging Systems" 1389 "EVEX" 1398 "Gobius Sensor Technology" 1403 "Arco Marine" 1408 "Lenco Marine" 1413 "Naocontrol" 1417 "Revatek" 1438 "Aeolionics" 1439 "PredictWind" 1440 "Egis Mobile Electric" 1445 "Starboard Yacht Group" 1446 "Roswell Marine" 1451 "ePropulsion (Guangdong ePropulsion Technology Ltd.)" 1452 "Micro-Air" 1453 "Vital Battery" 1458 "Ride Controller" 1460 "Tocaro Blue" 1461 "Vanquish Yachts" 1471 "FT Technologies" 1478 "Alps Alpine" 1481 "E-Force Marine" 1482 "CMC Marine" 1483 "Nanjing Sandemarine Information Technology" 1850 "Teleflex Marine (SeaStar Solutions)" 1851 "Raymarine" 1852 "Navionics" 1853 "Japan Radio" 1854 "Northstar Technologies" 1855 "Furuno" 1856 "Trimble" 1857 "Simrad" 1858 "Litton" 1859 "Kvasar" 1860 "MMP" 1861 "Vector Cantech" 1862 "Yamaha Marine" 1863 "Faria Instruments" ;
VAL_ 2650737152 Industry_Code 0 "Global" 1 "Highway" 2 "Agriculture" 3 "Construction" 4 "Marine Industry" 5 "Industrial" ;

BA_DEF_ BO_ "GenMsgCycleTime" INT 0 60000;
BA_DEF_ BO_ "ProtocolType" STRING;

BA_DEF_ BO_ "J1939PGN" INT 0 262143;
BA_ "J1939PGN" BO_ 2382300672 130822;
BA_ "J1939PGN" BO_ 2382300672 130822;
BA_ "J1939PGN" BO_ 2382300672 130822;
BA_ "J1939PGN" BO_ 2382300672 130822;
BA_ "J1939PGN" BO_ 2382300672 130822;
BA_ "J1939PGN" BO_ 2382300672 130822;
BA_ "J1939PGN" BO_ 2382300672 130822;
BA_ "J1939PGN" BO_ 2382300672 130822;
BA_ "J1939PGN" BO_ 2382300928 130823;
BA_ "J1939PGN" BO_ 2583627520 130823;
BA_ "J1939PGN" BO_ 2583627520 130823;
BA_ "J1939PGN" BO_ 2583627520 130823;
BA_ "J1939PGN" BO_ 2315192320 130824;
BA_ "GenMsgCycleTime" BO_ 2315192320 1000;
BA_ "J1939PGN" BO_ 2650736640 130824;
BA_ "J1939PGN" BO_ 2650736640 130824;
BA_ "J1939PGN" BO_ 2583628032 130825;
BA_ "J1939PGN" BO_ 2583628032 130825;
BA_ "J1939PGN" BO_ 2650736896 130825;
BA_ "J1939PGN" BO_ 2650736896 130825;
BA_ "J1939PGN" BO_ 2650736896 130825;
BA_ "J1939PGN" BO_ 2583628288 130826;
BA_ "J1939PGN" BO_ 2315192832 130826;
BA_ "J1939PGN" BO_ 2650737152 130826;
